VERSION "created by canmatrix"

NS_ :

BS_:

BU_: IPD

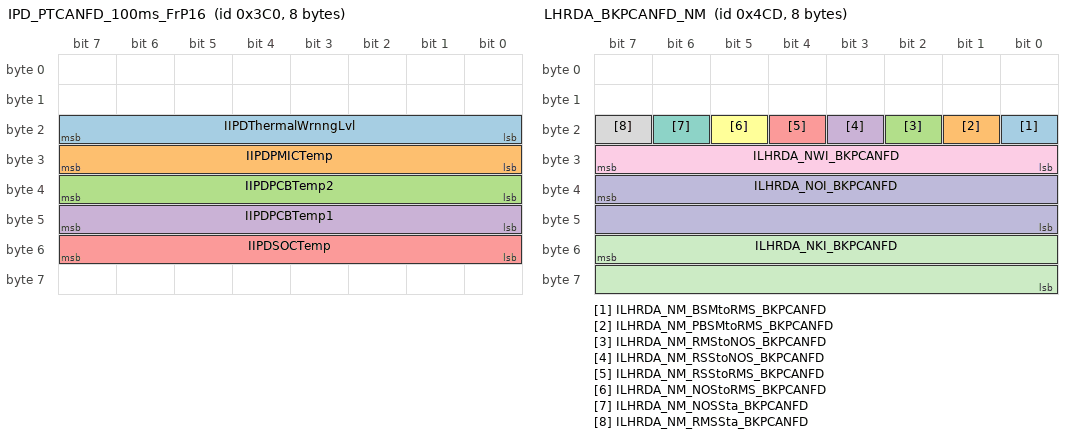
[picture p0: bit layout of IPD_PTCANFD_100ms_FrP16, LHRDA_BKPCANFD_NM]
BO_ 960 IPD_PTCANFD_100ms_FrP16: 8 IPD
 SG_ IIPDThermalWrnngLvl : 23|8@0+ (1,0) [0|255] "null" Vector__XXX
 SG_ IIPDPMICTemp : 31|8@0+ (1,-40) [-40|215] "℃" Vector__XXX
 SG_ IIPDPCBTemp2 : 39|8@0+ (1,-40) [-40|215] "℃" Vector__XXX
 SG_ IIPDPCBTemp1 : 47|8@0+ (1,-40) [-40|215] "℃" Vector__XXX
 SG_ IIPDSOCTemp : 55|8@0+ (1,-40) [-40|215] "℃" Vector__XXX

BO_ 1229 LHRDA_BKPCANFD_NM: 8 Vector__XXX
 SG_ ILHRDA_NM_BSMtoRMS_BKPCANFD : 16|1@0+ (1,0) [0|1] "null" Vector__XXX
 SG_ ILHRDA_NM_PBSMtoRMS_BKPCANFD : 17|1@0+ (1,0) [0|1] "null" Vector__XXX
 SG_ ILHRDA_NM_RMStoNOS_BKPCANFD : 18|1@0+ (1,0) [0|1] "null" Vector__XXX
 SG_ ILHRDA_NM_RSStoNOS_BKPCANFD : 19|1@0+ (1,0) [0|1] "null" Vector__XXX
 SG_ ILHRDA_NM_RSStoRMS_BKPCANFD : 20|1@0+ (1,0) [0|1] "null" Vector__XXX
 SG_ ILHRDA_NM_NOStoRMS_BKPCANFD : 21|1@0+ (1,0) [0|1] "null" Vector__XXX
 SG_ ILHRDA_NM_NOSSta_BKPCANFD : 22|1@0+ (1,0) [0|1] "null" Vector__XXX
 SG_ ILHRDA_NM_RMSSta_BKPCANFD : 23|1@0+ (1,0) [0|1] "null" Vector__XXX
 SG_ ILHRDA_NWI_BKPCANFD : 31|8@0+ (1,0) [0|255] "null" Vector__XXX
 SG_ ILHRDA_NOI_BKPCANFD : 39|16@0+ (1,0) [0|65535] "null" Vector__XXX
 SG_ ILHRDA_NKI_BKPCANFD : 55|16@0+ (1,0) [0|65535] "null" Vector__XXX

BO_ 181 LHZCU_BKBCANFD_10ms_FrP32: 12 Vector__XXX
 SG_ IDircnLghtOnReq_LHZCU : 41|2@0+ (1,0) [0|3] "null" IPD

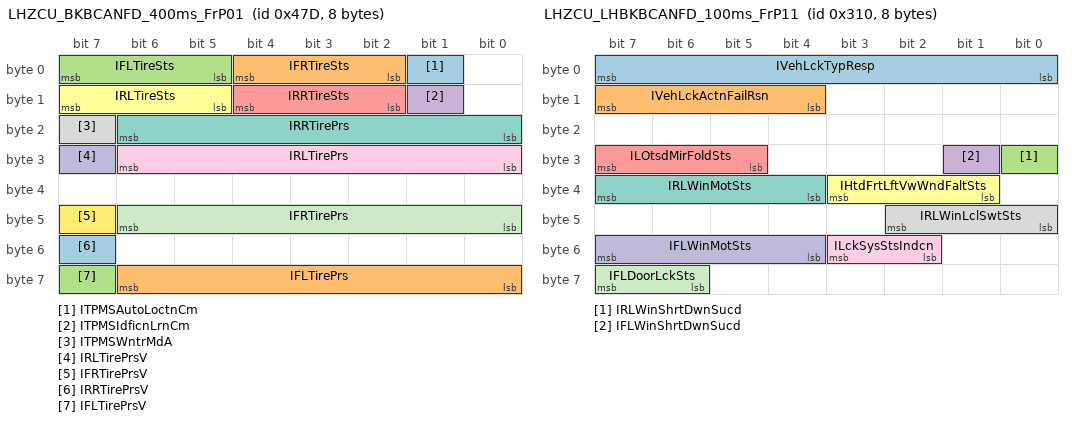
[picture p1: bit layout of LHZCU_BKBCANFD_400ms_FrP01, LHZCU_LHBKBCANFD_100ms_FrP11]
BO_ 1149 LHZCU_BKBCANFD_400ms_FrP01: 8 Vector__XXX
 SG_ ITPMSAutoLoctnCm : 1|1@0+ (1,0) [0|1] "null" Vector__XXX
 SG_ IFRTireSts : 4|3@0+ (1,0) [0|7] "null" IPD
 SG_ IFLTireSts : 7|3@0+ (1,0) [0|7] "null" IPD
 SG_ ITPMSIdficnLrnCm : 9|1@0+ (1,0) [0|1] "null" Vector__XXX
 SG_ IRRTireSts : 12|3@0+ (1,0) [0|7] "null" IPD
 SG_ IRLTireSts : 15|3@0+ (1,0) [0|7] "null" IPD
 SG_ IRRTirePrs : 22|7@0+ (4,0) [0|508] "kPa" IPD
 SG_ ITPMSWntrMdA : 23|1@0+ (1,0) [0|1] "null" IPD
 SG_ IRLTirePrs : 30|7@0+ (4,0) [0|508] "kPa" IPD
 SG_ IRLTirePrsV : 31|1@0+ (1,0) [0|1] "null" IPD
 SG_ IFRTirePrs : 46|7@0+ (4,0) [0|508] "kPa" IPD
 SG_ IFRTirePrsV : 47|1@0+ (1,0) [0|1] "null" IPD
 SG_ IRRTirePrsV : 55|1@0+ (1,0) [0|1] "null" IPD
 SG_ IFLTirePrs : 62|7@0+ (4,0) [0|508] "kPa" IPD
 SG_ IFLTirePrsV : 63|1@0+ (1,0) [0|1] "null" IPD

BO_ 638 LHZCU_BKBCANFD_50ms_FrP24: 20 Vector__XXX
 SG_ IVehIlluminateCtrlCmd : 24|1@0+ (1,0) [0|1] "null" Vector__XXX
 SG_ IBrkLghtSta : 32|1@0+ (1,0) [0|1] "null" Vector__XXX
 SG_ IBrkLghtFltSta : 40|1@0+ (1,0) [0|1] "null" Vector__XXX
 SG_ IDircnLghtSts : 52|3@0+ (1,0) [0|7] "null" Vector__XXX
 SG_ IDircnLghtMdSts : 53|1@0+ (1,0) [0|1] "null" Vector__XXX
 SG_ IRevsLghtFltSta : 54|1@0+ (1,0) [0|1] "null" Vector__XXX
 SG_ IRevsLghtSta : 55|1@0+ (1,0) [0|1] "null" Vector__XXX
 SG_ IRearFogLghtAcFltsts : 56|1@0+ (1,0) [0|1] "null" Vector__XXX
 SG_ IRearFogLghtAcSts : 57|1@0+ (1,0) [0|1] "null" Vector__XXX
 SG_ IRearFogLghtCtrl : 58|1@0+ (1,0) [0|1] "null" Vector__XXX
 SG_ ISideLghtFltsts : 59|1@0+ (1,0) [0|1] "null" Vector__XXX
 SG_ IRRSideLghtCtrl : 61|1@0+ (1,0) [0|1] "null" Vector__XXX
 SG_ IRLSideLghtCtrl : 62|1@0+ (1,0) [0|1] "null" Vector__XXX
 SG_ IHdlmpLvlngFltSts : 64|1@0+ (1,0) [0|1] "null" Vector__XXX
 SG_ IHdlmpLvlngCrtl : 67|3@0+ (1,0) [0|7] "null" Vector__XXX
 SG_ IDayTmRunngLghtFltsts : 68|1@0+ (1,0) [0|1] "null" Vector__XXX
 SG_ IDayTmRunngLghtSts : 69|1@0+ (1,0) [0|1] "null" Vector__XXX
 SG_ IFrtFogLghtSts : 74|1@0+ (1,0) [0|1] "null" Vector__XXX
 SG_ IRFrtFogLghtCtrl : 75|1@0+ (1,0) [0|1] "null" Vector__XXX
 SG_ ILFrtFogLghtCtrl : 76|1@0+ (1,0) [0|1] "null" Vector__XXX
 SG_ IHdlmpLvlngSts : 79|3@0+ (1,0) [0|7] "null" Vector__XXX
 SG_ IDircnLghtSwReq : 84|3@0+ (1,0) [0|7] "null" IPD
 SG_ IFrtFogLghtFltSts : 87|1@0+ (1,0) [0|1] "null" Vector__XXX
 SG_ IDircnLghtFltsts : 105|2@0+ (1,0) [0|3] "null" IPD

BO_ 745 LHZCU_BKBCANFD_50ms_FrP34: 16 Vector__XXX
 SG_ IAutoMainBeamLghtOn : 12|1@0+ (1,0) [0|1] "null" IPD
 SG_ IMainBeamLghtOn : 13|1@0+ (1,0) [0|1] "null" IPD
 SG_ IRLDoorLckSts : 21|2@0+ (1,0) [0|3] "null" Vector__XXX
 SG_ IComfortDircnLghtDsp : 25|2@0+ (1,0) [0|3] "null" Vector__XXX
 SG_ IFrtWiperTemp : 39|8@0+ (0.5,-40) [-40|87.5] "degreeCelsius" Vector__XXX
 SG_ IDircnLghtMdDsp : 44|2@0+ (1,0) [0|3] "null" Vector__XXX
 SG_ IAllWndAndSrfLazyClsReq : 45|1@0+ (1,0) [0|1] "null" Vector__XXX
 SG_ IRrSrvcPosReq : 46|1@0+ (1,0) [0|1] "null" Vector__XXX
 SG_ IRrWiperFnEnb : 47|1@0+ (1,0) [0|1] "null" Vector__XXX

BO_ 1150 LHZCU_LHBKBCANFDF_400ms_FrP18: 8 Vector__XXX
 SG_ ITPMSF : 12|1@0+ (1,0) [0|1] "null" IPD
 SG_ ITPMSTirePrsLowIO : 13|1@0+ (1,0) [0|1] "null" IPD

BO_ 784 LHZCU_LHBKBCANFD_100ms_FrP11: 8 Vector__XXX
 SG_ IVehLckTypResp : 7|8@0+ (1,0) [0|255] "null" Vector__XXX
 SG_ IVehLckActnFailRsn : 15|4@0+ (1,0) [0|15] "null" Vector__XXX
 SG_ IRLWinShrtDwnSucd : 24|1@0+ (1,0) [0|1] "null" Vector__XXX
 SG_ IFLWinShrtDwnSucd : 25|1@0+ (1,0) [0|1] "null" Vector__XXX
 SG_ ILOtsdMirFoldSts : 31|3@0+ (1,0) [0|7] "null" IPD
 SG_ IHtdFrtLftVwWndFaltSts : 35|3@0+ (1,0) [0|7] "null" Vector__XXX
 SG_ IRLWinMotSts : 39|4@0+ (1,0) [0|15] "null" Vector__XXX
 SG_ IRLWinLclSwtSts : 42|3@0+ (1,0) [0|7] "null" Vector__XXX
 SG_ ILckSysStsIndcn : 51|2@0+ (1,0) [0|3] "null" Vector__XXX
 SG_ IFLWinMotSts : 55|4@0+ (1,0) [0|15] "null" Vector__XXX
 SG_ IFLDoorLckSts : 63|2@0+ (1,0) [0|3] "null" Vector__XXX

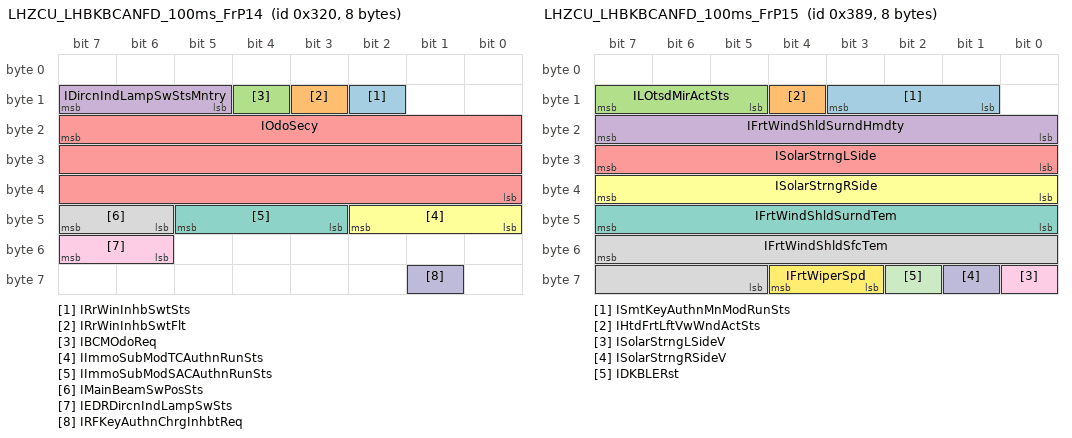
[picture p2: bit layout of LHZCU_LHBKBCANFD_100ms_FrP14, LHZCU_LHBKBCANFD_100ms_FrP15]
BO_ 800 LHZCU_LHBKBCANFD_100ms_FrP14: 8 Vector__XXX
 SG_ IRrWinInhbSwtSts : 10|1@0+ (1,0) [0|1] "null" Vector__XXX
 SG_ IRrWinInhbSwtFlt : 11|1@0+ (1,0) [0|1] "null" Vector__XXX
 SG_ IBCMOdoReq : 12|1@0+ (1,0) [0|1] "null" Vector__XXX
 SG_ IDircnIndLampSwStsMntry : 15|3@0+ (1,0) [0|7] "null" IPD
 SG_ IOdoSecy : 23|24@0+ (1,0) [0|16777215] "km" Vector__XXX
 SG_ IImmoSubModTCAuthnRunSts : 42|3@0+ (1,0) [0|7] "null" Vector__XXX
 SG_ IImmoSubModSACAuthnRunSts : 45|3@0+ (1,0) [0|7] "null" Vector__XXX
 SG_ IMainBeamSwPosSts : 47|2@0+ (1,0) [0|3] "null" IPD
 SG_ IEDRDircnIndLampSwSts : 55|2@0+ (1,0) [0|3] "null" Vector__XXX
 SG_ IRFKeyAuthnChrgInhbtReq : 57|1@0+ (1,0) [0|1] "null" Vector__XXX

BO_ 905 LHZCU_LHBKBCANFD_100ms_FrP15: 8 Vector__XXX
 SG_ ISmtKeyAuthnMnModRunSts : 11|3@0+ (1,0) [0|7] "null" Vector__XXX
 SG_ IHtdFrtLftVwWndActSts : 12|1@0+ (1,0) [0|1] "null" Vector__XXX
 SG_ ILOtsdMirActSts : 15|3@0+ (1,0) [0|7] "null" Vector__XXX
 SG_ IFrtWindShldSurndHmdty : 23|8@0+ (0.5,0) [0|127.5] "Percent" Vector__XXX
 SG_ ISolarStrngLSide : 31|8@0+ (5,0) [0|1275] "null" Vector__XXX
 SG_ ISolarStrngRSide : 39|8@0+ (5,0) [0|1275] "null" Vector__XXX
 SG_ IFrtWindShldSurndTem : 47|8@0+ (0.5,-40) [-40|87.5] "degreeCelsius" Vector__XXX
 SG_ IFrtWindShldSfcTem : 55|11@0+ (0.1,-40) [-40|164.7] "degreeCelsius" Vector__XXX
 SG_ ISolarStrngLSideV : 56|1@0+ (1,0) [0|1] "null" Vector__XXX
 SG_ ISolarStrngRSideV : 57|1@0+ (1,0) [0|1] "null" Vector__XXX
 SG_ IDKBLERst : 58|1@0+ (1,0) [0|1] "null" Vector__XXX
 SG_ IFrtWiperSpd : 60|2@0+ (1,0) [0|3] "null" IPD

BO_ 783 LHZCU_LHBKBCANFD_100ms_FrP16: 64 Vector__XXX
 SG_ ILHZCUeFs12Crnt : 7|9@0+ (0.1,0) [0|51.1] "A" Vector__XXX
 SG_ ILHZCUeSw40Crnt : 14|9@0+ (0.1,0) [0|51.1] "A" Vector__XXX
 SG_ IWlcmReq : 19|2@0+ (1,0) [0|3] "null" Vector__XXX
 SG_ IFllwMeReq : 21|2@0+ (1,0) [0|3] "null" Vector__XXX
 SG_ ILHZCUInptVol : 47|8@0+ (0.1,0) [0|25.5] "V" Vector__XXX
 SG_ ILHZCUeFs8Crnt : 55|9@0+ (0.1,0) [0|51.1] "A" Vector__XXX
 SG_ ILHZCUeSw24Crnt : 56|9@0+ (0.1,0) [0|51.1] "A" Vector__XXX
 SG_ ILHZCUeSw17Crnt : 76|9@0+ (0.1,0) [0|51.1] "A" Vector__XXX
 SG_ IKickSnsrDetnEnb : 77|1@0+ (1,0) [0|1] "null" Vector__XXX
 SG_ ILHZCUeSw16Crnt : 83|9@0+ (0.1,0) [0|51.1] "A" Vector__XXX
 SG_ ILHZCUeSw15Crnt : 90|9@0+ (0.1,0) [0|51.1] "A" Vector__XXX
 SG_ ILHZCUeSw14Crnt : 97|9@0+ (0.1,0) [0|51.1] "A" Vector__XXX
 SG_ ILHZCUeSw13Crnt : 104|9@0+ (0.1,0) [0|51.1] "A" Vector__XXX
 SG_ ILHZCUeSw12Crnt : 127|9@0+ (0.1,0) [0|51.1] "A" Vector__XXX
 SG_ ILHZCUeSw26Crnt : 128|9@0+ (0.1,0) [0|51.1] "A" Vector__XXX
 SG_ ILHZCUeFs6Crnt : 148|9@0+ (0.1,0) [0|51.1] "A" Vector__XXX
 SG_ IKickSnsrDfct : 149|1@0+ (1,0) [0|1] "null" Vector__XXX
 SG_ IKickSnsrEleDfct : 150|1@0+ (1,0) [0|1] "null" Vector__XXX
 SG_ IKickSnsrPlayProtn : 151|1@0+ (1,0) [0|1] "null" Vector__XXX
 SG_ ILHZCUeSw32Crnt : 155|9@0+ (0.1,0) [0|51.1] "A" Vector__XXX
 SG_ ILHZCUeFs4Crnt : 162|9@0+ (0.1,0) [0|51.1] "A" Vector__XXX
 SG_ ILHZCUeSw27Crnt : 168|9@0+ (0.1,0) [0|51.1] "A" Vector__XXX
 SG_ IKickSnsrSts : 169|1@0+ (1,0) [0|1] "null" Vector__XXX
 SG_ ILHZCUBkupInptVol : 191|8@0+ (0.1,0) [0|25.5] "V" Vector__XXX
 SG_ ILHZCUeSw1Crnt : 199|9@0+ (0.1,0) [0|51.1] "A" Vector__XXX
 SG_ ILHZCUeSw20Crnt : 206|9@0+ (0.1,0) [0|51.1] "A" Vector__XXX
 SG_ ILHZCUeSw3Crnt : 213|9@0+ (0.1,0) [0|51.1] "A" Vector__XXX
 SG_ ILHZCUeSw29Crnt : 216|9@0+ (0.1,0) [0|51.1] "A" Vector__XXX
 SG_ ILHZCUeSw36Crnt : 239|9@0+ (0.1,0) [0|51.1] "A" Vector__XXX
 SG_ ILHZCUeFs13Crnt : 240|9@0+ (0.1,0) [0|51.1] "A" Vector__XXX
 SG_ ILHZCUeSw30Crnt : 263|9@0+ (0.1,0) [0|51.1] "A" Vector__XXX
 SG_ ILHZCUeSw31Crnt : 264|9@0+ (0.1,0) [0|51.1] "A" Vector__XXX
 SG_ IFrwlLghtReq_LHZCU : 267|1@0+ (1,0) [0|1] "null" Vector__XXX
 SG_ ILHZCUeSw43Crnt : 287|9@0+ (0.1,0) [0|51.1] "A" Vector__XXX
 SG_ ILHZCUAddtnInptVol : 303|8@0+ (0.1,0) [0|25.5] "V" Vector__XXX
 SG_ ILHZCUeSw44Crnt : 311|9@0+ (0.1,0) [0|51.1] "A" Vector__XXX
 SG_ ILHZCUeSw45Crnt : 318|9@0+ (0.1,0) [0|51.1] "A" Vector__XXX
 SG_ ILHZCUeSw46Crnt : 335|9@0+ (0.1,0) [0|51.1] "A" Vector__XXX
 SG_ ILHZCUeSw47Crnt : 336|9@0+ (0.1,0) [0|51.1] "A" Vector__XXX
 SG_ IWlcmLghtReq_LHZCU : 338|1@0+ (1,0) [0|1] "null" Vector__XXX
 SG_ IFLDoorOpenSts : 341|2@0+ (1,0) [0|3] "null" IPD
 SG_ IHUDLghtSnsrHdwrFltPrst : 342|1@0+ (1,0) [0|1] "null" Vector__XXX
 SG_ IHUDFwdLkngAmbtLghtLvl : 383|14@0+ (10,0) [0|163830] "LUX" Vector__XXX
 SG_ IFollowMeHomeReq_LHZCU : 384|1@0+ (1,0) [0|1] "null" Vector__XXX
 SG_ IBklghtReq : 385|1@0+ (1,0) [0|1] "null" Vector__XXX
 SG_ IHUDRLSAmbtLghtLvl : 399|12@0+ (10,0) [0|40950] "LUX" Vector__XXX
 SG_ ILHZCUeFs15Crnt : 400|9@0+ (0.1,0) [0|51.1] "A" Vector__XXX
 SG_ IHmdtySnsrHdwrFltPrst : 401|1@0+ (1,0) [0|1] "null" Vector__XXX
 SG_ IFrtPsngDoorOpenSts_LHZCU : 403|2@0+ (1,0) [0|3] "null" IPD
 SG_ ILHZCUeFs17Crnt : 423|9@0+ (0.1,0) [0|51.1] "A" Vector__XXX

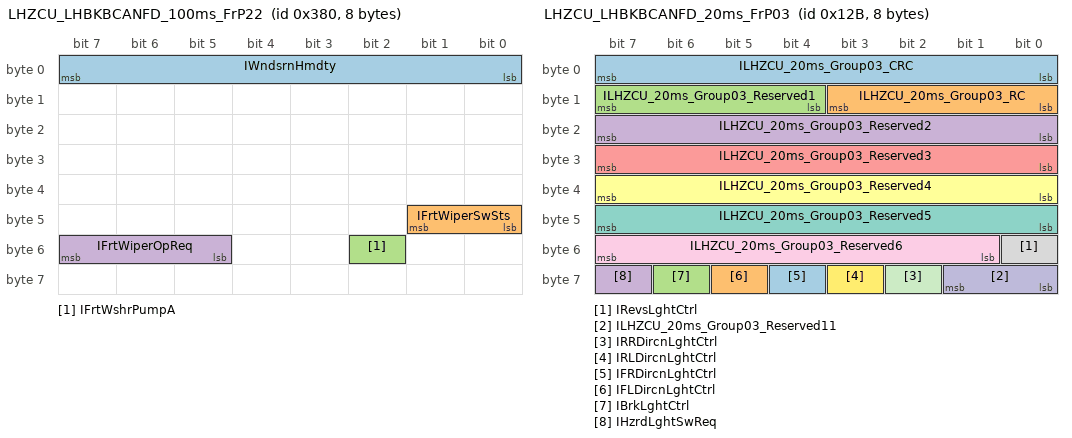
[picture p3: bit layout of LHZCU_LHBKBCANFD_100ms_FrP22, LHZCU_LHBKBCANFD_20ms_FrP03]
BO_ 896 LHZCU_LHBKBCANFD_100ms_FrP22: 8 Vector__XXX
 SG_ IWndsrnHmdty : 7|8@0+ (1,0) [0|255] "null" IPD
 SG_ IFrtWiperSwSts : 41|2@0+ (1,0) [0|3] "null" IPD
 SG_ IFrtWshrPumpA : 50|1@0+ (1,0) [0|1] "null" Vector__XXX
 SG_ IFrtWiperOpReq : 55|3@0+ (1,0) [0|7] "null" Vector__XXX

BO_ 299 LHZCU_LHBKBCANFD_20ms_FrP03: 8 Vector__XXX
 SG_ ILHZCU_20ms_Group03_CRC : 7|8@0+ (1,0) [0|255] "null" IPD
 SG_ ILHZCU_20ms_Group03_RC : 11|4@0+ (1,0) [0|15] "null" IPD
 SG_ ILHZCU_20ms_Group03_Reserved1 : 15|4@0+ (1,0) [0|15] "null" IPD
 SG_ ILHZCU_20ms_Group03_Reserved2 : 23|8@0+ (1,0) [0|255] "null" IPD
 SG_ ILHZCU_20ms_Group03_Reserved3 : 31|8@0+ (1,0) [0|255] "null" IPD
 SG_ ILHZCU_20ms_Group03_Reserved4 : 39|8@0+ (1,0) [0|255] "null" IPD
 SG_ ILHZCU_20ms_Group03_Reserved5 : 47|8@0+ (1,0) [0|255] "null" IPD
 SG_ IRevsLghtCtrl : 48|1@0+ (1,0) [0|1] "null" IPD
 SG_ ILHZCU_20ms_Group03_Reserved6 : 55|7@0+ (1,0) [0|127] "null" IPD
 SG_ ILHZCU_20ms_Group03_Reserved11 : 57|2@0+ (1,0) [0|3] "null" IPD
 SG_ IRRDircnLghtCtrl : 58|1@0+ (1,0) [0|1] "null" IPD
 SG_ IRLDircnLghtCtrl : 59|1@0+ (1,0) [0|1] "null" IPD
 SG_ IFRDircnLghtCtrl : 60|1@0+ (1,0) [0|1] "null" IPD
 SG_ IFLDircnLghtCtrl : 61|1@0+ (1,0) [0|1] "null" IPD
 SG_ IBrkLghtCtrl : 62|1@0+ (1,0) [0|1] "null" IPD
 SG_ IHzrdLghtSwReq : 63|1@0+ (1,0) [0|1] "null" IPD

BO_ 566 LHZCU_LHBKBCANFD_50ms_FrP04: 8 Vector__XXX
 SG_ IFindCarFuncInfoDsp : 2|2@0+ (1,0) [0|3] "null" Vector__XXX
 SG_ IDipdBeamLghtFltsts : 5|1@0+ (1,0) [0|1] "null" IPD
 SG_ IFLDoorHndlPESwtActv : 7|2@0+ (1,0) [0|3] "null" IPD
 SG_ IFRDoorHndlPESwtActv : 13|2@0+ (1,0) [0|3] "null" IPD
 SG_ IMainBeamLghtMdSts : 15|2@0+ (1,0) [0|3] "null" IPD
 SG_ IVehHzrdMdSts : 19|4@0+ (1,0) [0|15] "null" IPD
 SG_ IHzrdLghtSwSts : 20|1@0+ (1,0) [0|1] "null" IPD
 SG_ IBrkLghtSwStsV : 21|1@0+ (1,0) [0|1] "null" Vector__XXX
 SG_ IBrkLghtSwSts : 22|1@0+ (1,0) [0|1] "null" Vector__XXX
 SG_ IRrWiperReq : 23|1@0+ (1,0) [0|1] "null" Vector__XXX
 SG_ IMainBeamLghtFltSts : 26|1@0+ (1,0) [0|1] "null" IPD
 SG_ IMainBeamLghtSts : 27|1@0+ (1,0) [0|1] "null" Vector__XXX
 SG_ IMainBeamLghtSwSts : 29|2@0+ (1,0) [0|3] "null" Vector__XXX
 SG_ IDircnIndLghtSwSts : 31|2@0+ (1,0) [0|3] "null" IPD
 SG_ ILdspcRlseSwtActv : 32|1@0+ (1,0) [0|1] "null" Vector__XXX
 SG_ IRRWinDrvrSwtSts : 35|3@0+ (1,0) [0|7] "null" Vector__XXX
 SG_ ILckCtrlResp : 39|4@0+ (1,0) [0|15] "null" IPD
 SG_ IRLWinDrvrSwtSts : 44|3@0+ (1,0) [0|7] "null" Vector__XXX
 SG_ IFRWinDrvrSwtSts : 47|3@0+ (1,0) [0|7] "null" Vector__XXX
 SG_ IDipdBeamLghtSts : 48|1@0+ (1,0) [0|1] "null" IPD
 SG_ IBrkPdlTrigd : 49|1@0+ (1,0) [0|1] "null" Vector__XXX
 SG_ IFLWinLclSwtSts : 52|3@0+ (1,0) [0|7] "null" Vector__XXX
 SG_ IExtrLckActnIndcn : 55|3@0+ (1,0) [0|7] "null" Vector__XXX
 SG_ IAutoMainBeamLghtSts : 57|2@0+ (1,0) [0|3] "null" Vector__XXX
 SG_ IDrvrDetSnsrFltSts : 60|3@0+ (1,0) [0|7] "null" Vector__XXX
 SG_ IDircnIndLghtMdSts : 63|3@0+ (1,0) [0|7] "null" IPD

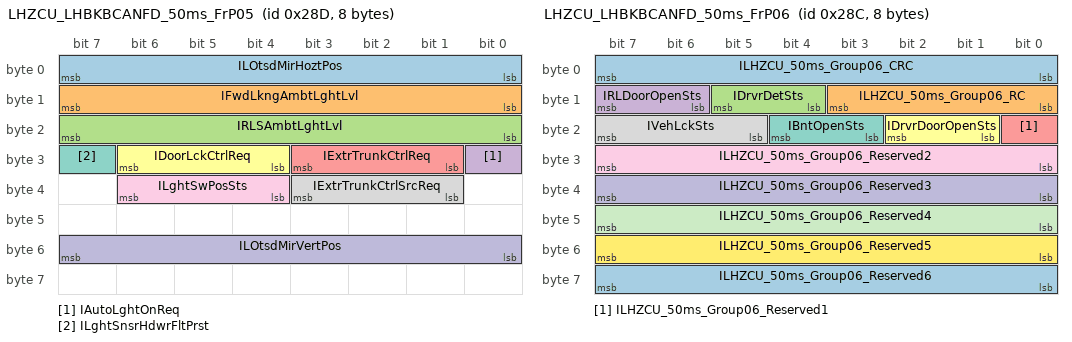
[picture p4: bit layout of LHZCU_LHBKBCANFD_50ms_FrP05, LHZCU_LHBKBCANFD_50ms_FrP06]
BO_ 653 LHZCU_LHBKBCANFD_50ms_FrP05: 8 Vector__XXX
 SG_ ILOtsdMirHoztPos : 7|8@0+ (1,0) [0|255] "null" Vector__XXX
 SG_ IFwdLkngAmbtLghtLvl : 15|8@0+ (20,0) [0|5100] "lux" IPD
 SG_ IRLSAmbtLghtLvl : 23|8@0+ (20,0) [0|5100] "lux" IPD
 SG_ IAutoLghtOnReq : 24|1@0+ (1,0) [0|1] "null" IPD
 SG_ IExtrTrunkCtrlReq : 27|3@0+ (1,0) [0|7] "null" Vector__XXX
 SG_ IDoorLckCtrlReq : 30|3@0+ (1,0) [0|7] "null" Vector__XXX
 SG_ ILghtSnsrHdwrFltPrst : 31|1@0+ (1,0) [0|1] "null" IPD
 SG_ IExtrTrunkCtrlSrcReq : 35|3@0+ (1,0) [0|7] "null" Vector__XXX
 SG_ ILghtSwPosSts : 38|3@0+ (1,0) [0|7] "null" IPD
 SG_ ILOtsdMirVertPos : 55|8@0+ (1,0) [0|255] "null" Vector__XXX

BO_ 652 LHZCU_LHBKBCANFD_50ms_FrP06: 8 Vector__XXX
 SG_ ILHZCU_50ms_Group06_CRC : 7|8@0+ (1,0) [0|255] "null" IPD
 SG_ ILHZCU_50ms_Group06_RC : 11|4@0+ (1,0) [0|15] "null" IPD
 SG_ IDrvrDetSts : 13|2@0+ (1,0) [0|3] "null" IPD
 SG_ IRLDoorOpenSts : 15|2@0+ (1,0) [0|3] "null" IPD
 SG_ ILHZCU_50ms_Group06_Reserved1 : 16|1@0+ (1,0) [0|1] "null" IPD
 SG_ IDrvrDoorOpenSts : 18|2@0+ (1,0) [0|3] "null" IPD
 SG_ IBntOpenSts : 20|2@0+ (1,0) [0|3] "null" IPD
 SG_ IVehLckSts : 23|3@0+ (1,0) [0|7] "null" IPD
 SG_ ILHZCU_50ms_Group06_Reserved2 : 31|8@0+ (1,0) [0|255] "null" IPD
 SG_ ILHZCU_50ms_Group06_Reserved3 : 39|8@0+ (1,0) [0|255] "null" IPD
 SG_ ILHZCU_50ms_Group06_Reserved4 : 47|8@0+ (1,0) [0|255] "null" IPD
 SG_ ILHZCU_50ms_Group06_Reserved5 : 55|8@0+ (1,0) [0|255] "null" IPD
 SG_ ILHZCU_50ms_Group06_Reserved6 : 63|8@0+ (1,0) [0|255] "null" IPD

BO_ 714 PICM_PTCANFD_100ms_FrP06: 20 Vector__XXX
 SG_ IAGSModestatus2 : 13|2@0+ (1,0) [0|3] "null" Vector__XXX
 SG_ IAGSModestatus1 : 15|2@0+ (1,0) [0|3] "null" Vector__XXX
 SG_ IAGS1FltRsn : 23|12@0+ (1,0) [0|4095] "null" Vector__XXX
 SG_ IAGS2FltRsn : 27|12@0+ (1,0) [0|4095] "null" Vector__XXX
 SG_ IAGSActualPosition1 : 47|8@0+ (0.392157,0) [0.000000|100.000035] "null" Vector__XXX
 SG_ IAGSActualPosition2 : 55|8@0+ (0.392157,0) [0.000000|100.000035] "null" Vector__XXX
 SG_ IEPTElecWtrPumpActuSpd : 63|8@0+ (0.4,0) [0|102] "null" IPD
 SG_ IESSElecWtrPumpActuSpd : 71|8@0+ (0.4,0) [0|102] "null" Vector__XXX
 SG_ IEDUClntTem : 79|8@0+ (1,-40) [-40|215] "null" IPD
 SG_ IAGSTorqueResponse2 : 81|2@0+ (1,0) [0|3] "null" Vector__XXX
 SG_ IAGSTorqueResponse1 : 83|2@0+ (1,0) [0|3] "null" Vector__XXX
 SG_ IAGSSelflearnStatus2 : 85|2@0+ (1,0) [0|3] "null" Vector__XXX
 SG_ IAGSSelflearnStatus1 : 87|2@0+ (1,0) [0|3] "null" Vector__XXX
 SG_ IEDUClntTemV : 93|1@0+ (1,0) [0|1] "null" IPD
 SG_ IAGSMoveStatus2 : 94|1@0+ (1,0) [0|1] "null" Vector__XXX
 SG_ IAGSMoveStatus1 : 95|1@0+ (1,0) [0|1] "null" Vector__XXX

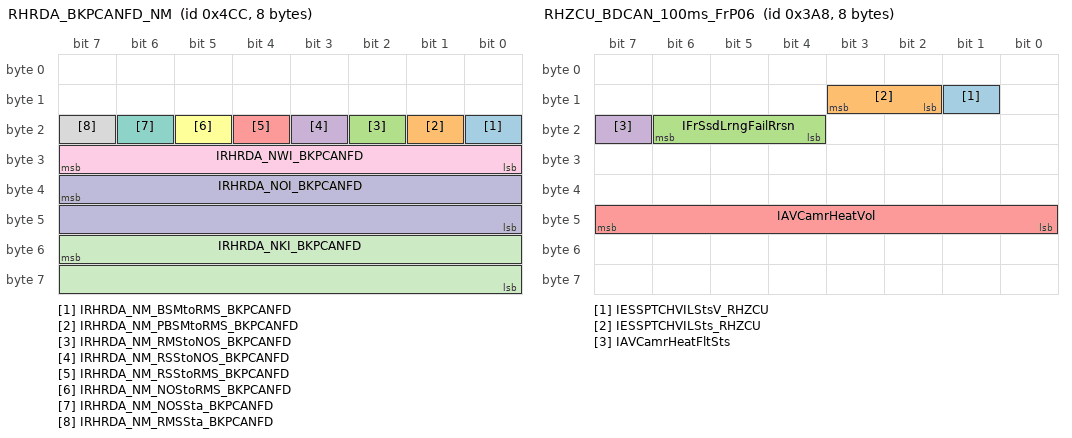
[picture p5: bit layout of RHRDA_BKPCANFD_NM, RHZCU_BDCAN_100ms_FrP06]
BO_ 1228 RHRDA_BKPCANFD_NM: 8 Vector__XXX
 SG_ IRHRDA_NM_BSMtoRMS_BKPCANFD : 16|1@0+ (1,0) [0|1] "null" Vector__XXX
 SG_ IRHRDA_NM_PBSMtoRMS_BKPCANFD : 17|1@0+ (1,0) [0|1] "null" Vector__XXX
 SG_ IRHRDA_NM_RMStoNOS_BKPCANFD : 18|1@0+ (1,0) [0|1] "null" Vector__XXX
 SG_ IRHRDA_NM_RSStoNOS_BKPCANFD : 19|1@0+ (1,0) [0|1] "null" Vector__XXX
 SG_ IRHRDA_NM_RSStoRMS_BKPCANFD : 20|1@0+ (1,0) [0|1] "null" Vector__XXX
 SG_ IRHRDA_NM_NOStoRMS_BKPCANFD : 21|1@0+ (1,0) [0|1] "null" Vector__XXX
 SG_ IRHRDA_NM_NOSSta_BKPCANFD : 22|1@0+ (1,0) [0|1] "null" Vector__XXX
 SG_ IRHRDA_NM_RMSSta_BKPCANFD : 23|1@0+ (1,0) [0|1] "null" Vector__XXX
 SG_ IRHRDA_NWI_BKPCANFD : 31|8@0+ (1,0) [0|255] "null" Vector__XXX
 SG_ IRHRDA_NOI_BKPCANFD : 39|16@0+ (1,0) [0|65535] "null" Vector__XXX
 SG_ IRHRDA_NKI_BKPCANFD : 55|16@0+ (1,0) [0|65535] "null" Vector__XXX

BO_ 936 RHZCU_BDCAN_100ms_FrP06: 8 Vector__XXX
 SG_ IESSPTCHVILStsV_RHZCU : 9|1@0+ (1,0) [0|1] "null" Vector__XXX
 SG_ IESSPTCHVILSts_RHZCU : 11|2@0+ (1,0) [0|3] "null" Vector__XXX
 SG_ IFrSsdLrngFailRrsn : 22|3@0+ (1,0) [0|7] "null" Vector__XXX
 SG_ IAVCamrHeatFltSts : 23|1@0+ (1,0) [0|1] "null" IPD
 SG_ IAVCamrHeatVol : 47|8@0+ (0.1,3) [3|28.5] "V" IPD

BO_ 701 RHZCU_RHBKBCANFD_100ms_FrP11: 12 Vector__XXX
 SG_ IITMSEDUClntInltTem : 7|8@0+ (1,-40) [-40|215] "degreeCelsius" IPD
 SG_ IITMSAGS1Pos : 15|8@0+ (1,0) [0|255] "Percent" Vector__XXX
 SG_ IITMSAGS2Pos : 23|8@0+ (1,0) [0|255] "Percent" Vector__XXX
 SG_ IITMSEDUClntInltTemV : 48|1@0+ (1,0) [0|1] "null" IPD
 SG_ IEACPwrLmtSts : 49|1@0+ (1,0) [0|1] "null" Vector__XXX
 SG_ IITMSEnbWPTC : 51|2@0+ (1,0) [0|3] "null" Vector__XXX
 SG_ IITMSEPTCoolngFanSts : 53|2@0+ (1,0) [0|3] "null" Vector__XXX
 SG_ IITMSMotHeatEnb : 55|1@0+ (1,0) [0|1] "null" Vector__XXX
 SG_ IITMSBMSClntPumpSts : 59|2@0+ (1,0) [0|3] "null" Vector__XXX
 SG_ IPTCPwrLmtSts : 60|1@0+ (1,0) [0|1] "null" Vector__XXX
 SG_ IITMSEPTEDUClntPumpSts : 63|3@0+ (1,0) [0|7] "null" IPD
 SG_ IITMSTMHeatPowReq : 71|8@0+ (0.1,0) [0|25.5] "null" Vector__XXX

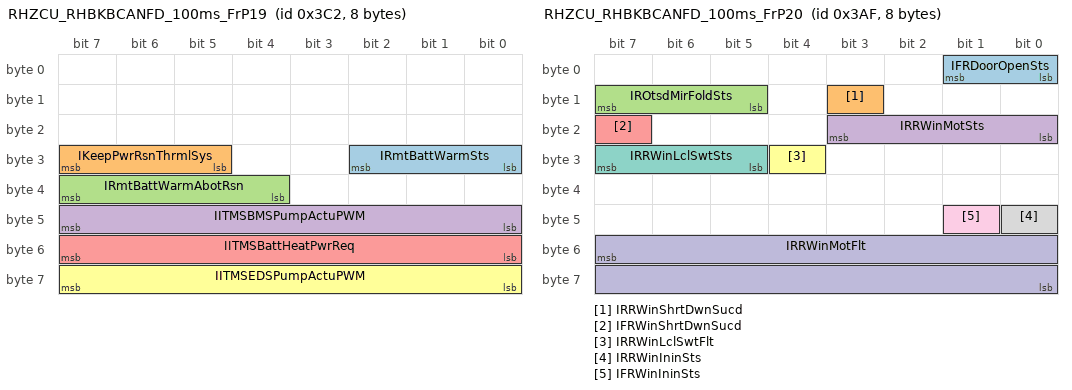
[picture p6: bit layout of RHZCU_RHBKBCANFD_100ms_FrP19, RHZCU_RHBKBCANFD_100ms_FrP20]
BO_ 962 RHZCU_RHBKBCANFD_100ms_FrP19: 8 Vector__XXX
 SG_ IRmtBattWarmSts : 26|3@0+ (1,0) [0|7] "null" Vector__XXX
 SG_ IKeepPwrRsnThrmlSys : 31|3@0+ (1,0) [0|7] "null" Vector__XXX
 SG_ IRmtBattWarmAbotRsn : 39|4@0+ (1,0) [0|15] "null" Vector__XXX
 SG_ IITMSBMSPumpActuPWM : 47|8@0+ (0.4,0) [0|102] "Percent" Vector__XXX
 SG_ IITMSBattHeatPwrReq : 55|8@0+ (0.1,0) [0|25.5] "kW" Vector__XXX
 SG_ IITMSEDSPumpActuPWM : 63|8@0+ (0.4,0) [0|102] "Percent
%" IPD

BO_ 943 RHZCU_RHBKBCANFD_100ms_FrP20: 8 Vector__XXX
 SG_ IFRDoorOpenSts : 1|2@0+ (1,0) [0|3] "null" IPD
 SG_ IRRWinShrtDwnSucd : 11|1@0+ (1,0) [0|1] "null" Vector__XXX
 SG_ IROtsdMirFoldSts : 15|3@0+ (1,0) [0|7] "null" IPD
 SG_ IRRWinMotSts : 19|4@0+ (1,0) [0|15] "null" Vector__XXX
 SG_ IFRWinShrtDwnSucd : 23|1@0+ (1,0) [0|1] "null" Vector__XXX
 SG_ IRRWinLclSwtFlt : 28|1@0+ (1,0) [0|1] "null" Vector__XXX
 SG_ IRRWinLclSwtSts : 31|3@0+ (1,0) [0|7] "null" Vector__XXX
 SG_ IRRWinIninSts : 40|1@0+ (1,0) [0|1] "null" Vector__XXX
 SG_ IFRWinIninSts : 41|1@0+ (1,0) [0|1] "null" Vector__XXX
 SG_ IRRWinMotFlt : 55|16@0+ (1,0) [0|65535] "null" Vector__XXX

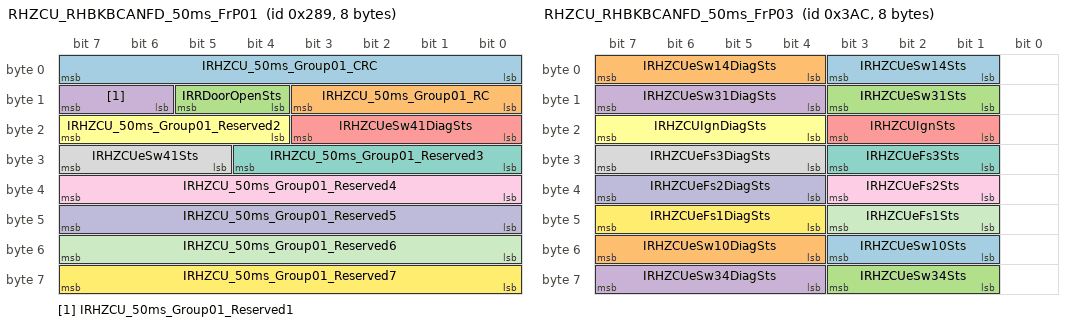
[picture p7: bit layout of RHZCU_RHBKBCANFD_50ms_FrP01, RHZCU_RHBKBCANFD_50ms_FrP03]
BO_ 649 RHZCU_RHBKBCANFD_50ms_FrP01: 8 Vector__XXX
 SG_ IRHZCU_50ms_Group01_CRC : 7|8@0+ (1,0) [0|255] "null" IPD
 SG_ IRHZCU_50ms_Group01_RC : 11|4@0+ (1,0) [0|15] "null" IPD
 SG_ IRRDoorOpenSts : 13|2@0+ (1,0) [0|3] "null" IPD
 SG_ IRHZCU_50ms_Group01_Reserved1 : 15|2@0+ (1,0) [0|3] "null" IPD
 SG_ IRHZCUeSw41DiagSts : 19|4@0+ (1,0) [0|15] "null" IPD
 SG_ IRHZCU_50ms_Group01_Reserved2 : 23|4@0+ (1,0) [0|15] "null" IPD
 SG_ IRHZCU_50ms_Group01_Reserved3 : 28|5@0+ (1,0) [0|31] "null" IPD
 SG_ IRHZCUeSw41Sts : 31|3@0+ (1,0) [0|7] "null" IPD
 SG_ IRHZCU_50ms_Group01_Reserved4 : 39|8@0+ (1,0) [0|255] "null" IPD
 SG_ IRHZCU_50ms_Group01_Reserved5 : 47|8@0+ (1,0) [0|255] "null" IPD
 SG_ IRHZCU_50ms_Group01_Reserved6 : 55|8@0+ (1,0) [0|255] "null" IPD
 SG_ IRHZCU_50ms_Group01_Reserved7 : 63|8@0+ (1,0) [0|255] "null" IPD

BO_ 940 RHZCU_RHBKBCANFD_50ms_FrP03: 8 Vector__XXX
 SG_ IRHZCUeSw14Sts : 3|3@0+ (1,0) [0|7] "null" Vector__XXX
 SG_ IRHZCUeSw14DiagSts : 7|4@0+ (1,0) [0|15] "null" Vector__XXX
 SG_ IRHZCUeSw31Sts : 11|3@0+ (1,0) [0|7] "null" Vector__XXX
 SG_ IRHZCUeSw31DiagSts : 15|4@0+ (1,0) [0|15] "null" Vector__XXX
 SG_ IRHZCUIgnSts : 19|3@0+ (1,0) [0|7] "null" IPD
 SG_ IRHZCUIgnDiagSts : 23|4@0+ (1,0) [0|15] "null" Vector__XXX
 SG_ IRHZCUeFs3Sts : 27|3@0+ (1,0) [0|7] "null" Vector__XXX
 SG_ IRHZCUeFs3DiagSts : 31|4@0+ (1,0) [0|15] "null" Vector__XXX
 SG_ IRHZCUeFs2Sts : 35|3@0+ (1,0) [0|7] "null" Vector__XXX
 SG_ IRHZCUeFs2DiagSts : 39|4@0+ (1,0) [0|15] "null" Vector__XXX
 SG_ IRHZCUeFs1Sts : 43|3@0+ (1,0) [0|7] "null" Vector__XXX
 SG_ IRHZCUeFs1DiagSts : 47|4@0+ (1,0) [0|15] "null" Vector__XXX
 SG_ IRHZCUeSw10Sts : 51|3@0+ (1,0) [0|7] "null" Vector__XXX
 SG_ IRHZCUeSw10DiagSts : 55|4@0+ (1,0) [0|15] "null" Vector__XXX
 SG_ IRHZCUeSw34Sts : 59|3@0+ (1,0) [0|7] "null" Vector__XXX
 SG_ IRHZCUeSw34DiagSts : 63|4@0+ (1,0) [0|15] "null" Vector__XXX

BO_ 564 RZCU_LHBKBCANFD_50ms_FrP37: 8 Vector__XXX
 SG_ IRLDircnLghtSts : 26|1@0+ (1,0) [0|1] "null" Vector__XXX
 SG_ IRRDircnLghtSts : 35|1@0+ (1,0) [0|1] "null" Vector__XXX
 SG_ IRRDircnLghtFltsts : 37|1@0+ (1,0) [0|1] "null" Vector__XXX
 SG_ IRLDircnLghtFltsts : 39|1@0+ (1,0) [0|1] "null" Vector__XXX
 SG_ IRRDircnLghtFltsts_HW : 40|1@0+ (1,0) [0|1] "null" Vector__XXX
 SG_ IRLDircnLghtFltsts_HW : 41|1@0+ (1,0) [0|1] "null" Vector__XXX
 SG_ IRearFogLghtFltsts : 42|1@0+ (1,0) [0|1] "null" Vector__XXX
 SG_ IRearFogLghtSts : 43|1@0+ (1,0) [0|1] "null" Vector__XXX
 SG_ IRevsLghtFltSts : 44|1@0+ (1,0) [0|1] "null" Vector__XXX
 SG_ IBrkLghtFltSts_HW : 45|1@0+ (1,0) [0|1] "null" Vector__XXX
 SG_ IBrkLghtSts_HW : 50|1@0+ (1,0) [0|1] "null" Vector__XXX
 SG_ IRLDircnLghtSts_HW : 51|1@0+ (1,0) [0|1] "null" Vector__XXX
 SG_ IRRDircnLghtSts_HW : 52|1@0+ (1,0) [0|1] "null" Vector__XXX
 SG_ ILdspcOpenSts : 53|1@0+ (1,0) [0|1] "null" IPD
 SG_ IRevsLghtSts : 54|1@0+ (1,0) [0|1] "null" IPD
 SG_ ILdspcOpenStsV : 55|1@0+ (1,0) [0|1] "null" IPD
 SG_ IRLChrgrFlapOpenPos : 63|8@0+ (1,0) [0|255] "null" Vector__XXX

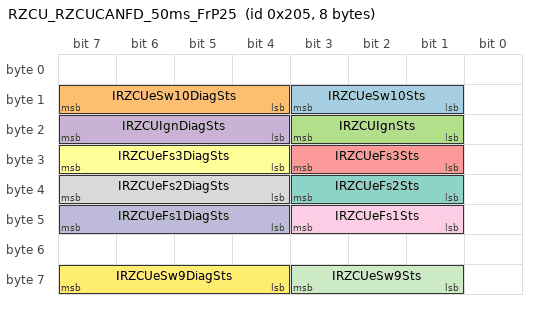
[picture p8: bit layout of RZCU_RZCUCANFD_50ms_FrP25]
BO_ 517 RZCU_RZCUCANFD_50ms_FrP25: 8 Vector__XXX
 SG_ IRZCUeSw10Sts : 11|3@0+ (1,0) [0|7] "null" Vector__XXX
 SG_ IRZCUeSw10DiagSts : 15|4@0+ (1,0) [0|15] "null" Vector__XXX
 SG_ IRZCUIgnSts : 19|3@0+ (1,0) [0|7] "null" IPD
 SG_ IRZCUIgnDiagSts : 23|4@0+ (1,0) [0|15] "null" IPD
 SG_ IRZCUeFs3Sts : 27|3@0+ (1,0) [0|7] "null" Vector__XXX
 SG_ IRZCUeFs3DiagSts : 31|4@0+ (1,0) [0|15] "null" Vector__XXX
 SG_ IRZCUeFs2Sts : 35|3@0+ (1,0) [0|7] "null" Vector__XXX
 SG_ IRZCUeFs2DiagSts : 39|4@0+ (1,0) [0|15] "null" Vector__XXX
 SG_ IRZCUeFs1Sts : 43|3@0+ (1,0) [0|7] "null" Vector__XXX
 SG_ IRZCUeFs1DiagSts : 47|4@0+ (1,0) [0|15] "null" Vector__XXX
 SG_ IRZCUeSw9Sts : 59|3@0+ (1,0) [0|7] "null" Vector__XXX
 SG_ IRZCUeSw9DiagSts : 63|4@0+ (1,0) [0|15] "null" Vector__XXX

BA_DEF_ BO_ "FrameTriggeringName" STRING;
BA_DEF_ BO_ "GenMsgCycleTime" INT 0 65535;
BA_DEF_ BO_ "GenMsgDelayTime" INT 0 65535;
BA_DEF_ BO_ "GenMsgSendType" ENUM  "cyclicX","spontanX","cyclicIfActiveX","spontanWithDelay","cyclicAndSpontanX","cyclicAndSpontanWithDelay","spontanWithRepitition","cyclicIfActiveAndSpontanWD","cyclicIfActiveFast","cyclicWithRepeatOnDemand","none";
BA_DEF_ BO_ "GenMsgStartValue" STRING;
BA_DEF_ BO_ "PduName" STRING;
BA_DEF_ BO_ "VFrameFormat" ENUM  "StandardCAN","ExtendedCAN","reserved","reserved","reserved","reserved","reserved","reserved","reserved","reserved","reserved","reserved","reserved","reserved","StandardCAN_FD","ExtendedCAN_FD";
BA_DEF_ SG_ "CompuMethodName" STRING;
BA_DEF_ SG_ "GenSigStartValue" FLOAT 0 100000000000;
BA_DEF_ SG_ "ISignalName" STRING;
BA_DEF_ SG_ "LongName" STRING;
BA_DEF_ SG_ "SysSignalName" STRING;
BA_DEF_ SG_ "SystemSignalLongSymbol" STRING;
BA_ "FrameTriggeringName" BO_ 960 "IPD_PTCANFD_100ms_FrP16";
BA_ "GenMsgCycleTime" BO_ 960 100;
BA_ "GenMsgSendType" BO_ 960 0;
BA_ "GenMsgStartValue" BO_ 960 "000000ffffffff00";
BA_ "PduName" BO_ 960 "IPD_100ms_PDU16";
BA_ "VFrameFormat" BO_ 960 14;
BA_ "FrameTriggeringName" BO_ 1229 "LHRDA_BKPCANFD_NM";
BA_ "GenMsgSendType" BO_ 1229 1;
BA_ "GenMsgStartValue" BO_ 1229 "0000000000000000";
BA_ "PduName" BO_ 1229 "NmPDU_BKPCANFD_LHRDA";
BA_ "VFrameFormat" BO_ 1229 14;
BA_ "FrameTriggeringName" BO_ 181 "LHZCU_BKBCANFD_10ms_FrP32";
BA_ "GenMsgCycleTime" BO_ 181 10;
BA_ "GenMsgSendType" BO_ 181 0;
BA_ "GenMsgStartValue" BO_ 181 "000000000000000000000000";
BA_ "PduName" BO_ 181 "LHZCU_10ms_PDU32";
BA_ "VFrameFormat" BO_ 181 14;
BA_ "FrameTriggeringName" BO_ 1149 "LHZCU_BKBCANFD_400ms_FrP01";
BA_ "GenMsgCycleTime" BO_ 1149 400;
BA_ "GenMsgSendType" BO_ 1149 0;
BA_ "GenMsgStartValue" BO_ 1149 "0202373700370037";
BA_ "PduName" BO_ 1149 "LHZCU_400ms_PDU01";
BA_ "VFrameFormat" BO_ 1149 14;
BA_ "FrameTriggeringName" BO_ 638 "LHZCU_BKBCANFD_50ms_FrP24";
BA_ "GenMsgCycleTime" BO_ 638 50;
BA_ "GenMsgSendType" BO_ 638 0;
BA_ "GenMsgStartValue" BO_ 638 "0000000000000000000000000000000000000000";
BA_ "PduName" BO_ 638 "LHZCU_50ms_PDU24";
BA_ "VFrameFormat" BO_ 638 14;
BA_ "FrameTriggeringName" BO_ 745 "LHZCU_BKBCANFD_50ms_FrP34";
BA_ "GenMsgCycleTime" BO_ 745 50;
BA_ "GenMsgSendType" BO_ 745 0;
BA_ "GenMsgStartValue" BO_ 745 "00000000000000000000000000000000";
BA_ "PduName" BO_ 745 "LHZCU_50ms_PDU34";
BA_ "VFrameFormat" BO_ 745 14;
BA_ "FrameTriggeringName" BO_ 1150 "LHZCU_LHBKBCANFDF_400ms_FrP18";
BA_ "GenMsgCycleTime" BO_ 1150 400;
BA_ "GenMsgSendType" BO_ 1150 0;
BA_ "GenMsgStartValue" BO_ 1150 "0000000000000000";
BA_ "PduName" BO_ 1150 "LHZCU_400ms_PDU18";
BA_ "VFrameFormat" BO_ 1150 14;
BA_ "FrameTriggeringName" BO_ 784 "LHZCU_LHBKBCANFD_100ms_FrP11";
BA_ "GenMsgCycleTime" BO_ 784 100;
BA_ "GenMsgSendType" BO_ 784 0;
BA_ "GenMsgStartValue" BO_ 784 "0000000000000000";
BA_ "PduName" BO_ 784 "LHZCU_100ms_PDU11";
BA_ "VFrameFormat" BO_ 784 14;
BA_ "FrameTriggeringName" BO_ 800 "LHZCU_LHBKBCANFD_100ms_FrP14";
BA_ "GenMsgCycleTime" BO_ 800 100;
BA_ "GenMsgSendType" BO_ 800 0;
BA_ "GenMsgStartValue" BO_ 800 "0000000000000000";
BA_ "PduName" BO_ 800 "LHZCU_100ms_PDU14";
BA_ "VFrameFormat" BO_ 800 14;
BA_ "FrameTriggeringName" BO_ 905 "LHZCU_LHBKBCANFD_100ms_FrP15";
BA_ "GenMsgCycleTime" BO_ 905 100;
BA_ "GenMsgSendType" BO_ 905 0;
BA_ "GenMsgStartValue" BO_ 905 "0000000000000000";
BA_ "PduName" BO_ 905 "LHZCU_100ms_PDU15";
BA_ "VFrameFormat" BO_ 905 14;
BA_ "FrameTriggeringName" BO_ 783 "LHZCU_LHBKBCANFD_100ms_FrP16";
BA_ "GenMsgCycleTime" BO_ 783 100;
BA_ "GenMsgSendType" BO_ 783 0;
BA_ "GenMsgStartValue" BO_ 783 "00000000000000000000000000000000000000000000000000000000000000000000000000000000000000000000000000000000000000000000000000000000";
BA_ "PduName" BO_ 783 "LHZCU_100ms_PDU16";
BA_ "VFrameFormat" BO_ 783 14;
BA_ "FrameTriggeringName" BO_ 896 "LHZCU_LHBKBCANFD_100ms_FrP22";
BA_ "GenMsgCycleTime" BO_ 896 100;
BA_ "GenMsgSendType" BO_ 896 0;
BA_ "GenMsgStartValue" BO_ 896 "0000000000000000";
BA_ "PduName" BO_ 896 "LHZCU_100ms_PDU22";
BA_ "VFrameFormat" BO_ 896 14;
BA_ "FrameTriggeringName" BO_ 299 "LHZCU_LHBKBCANFD_20ms_FrP03";
BA_ "GenMsgCycleTime" BO_ 299 20;
BA_ "GenMsgSendType" BO_ 299 0;
BA_ "GenMsgStartValue" BO_ 299 "00f0fffffffffe03";
BA_ "PduName" BO_ 299 "LHZCU_20ms_PDU03";
BA_ "VFrameFormat" BO_ 299 14;
BA_ "FrameTriggeringName" BO_ 566 "LHZCU_LHBKBCANFD_50ms_FrP04";
BA_ "GenMsgCycleTime" BO_ 566 50;
BA_ "GenMsgSendType" BO_ 566 0;
BA_ "GenMsgStartValue" BO_ 566 "0010000000000000";
BA_ "PduName" BO_ 566 "LHZCU_50ms_PDU04";
BA_ "VFrameFormat" BO_ 566 14;
BA_ "FrameTriggeringName" BO_ 653 "LHZCU_LHBKBCANFD_50ms_FrP05";
BA_ "GenMsgCycleTime" BO_ 653 50;
BA_ "GenMsgSendType" BO_ 653 0;
BA_ "GenMsgStartValue" BO_ 653 "ff0000000000ff00";
BA_ "PduName" BO_ 653 "LHZCU_50ms_PDU05";
BA_ "VFrameFormat" BO_ 653 14;
BA_ "FrameTriggeringName" BO_ 652 "LHZCU_LHBKBCANFD_50ms_FrP06";
BA_ "GenMsgCycleTime" BO_ 652 50;
BA_ "GenMsgSendType" BO_ 652 0;
BA_ "GenMsgStartValue" BO_ 652 "0000e1ffffffffff";
BA_ "PduName" BO_ 652 "LHZCU_50ms_PDU06";
BA_ "VFrameFormat" BO_ 652 14;
BA_ "FrameTriggeringName" BO_ 714 "PICM_PTCANFD_100ms_FrP06";
BA_ "GenMsgCycleTime" BO_ 714 100;
BA_ "GenMsgSendType" BO_ 714 0;
BA_ "GenMsgStartValue" BO_ 714 "00f00000000000ffff00ff000000000000000000";
BA_ "PduName" BO_ 714 "PICM_100ms_PDU06";
BA_ "VFrameFormat" BO_ 714 14;
BA_ "FrameTriggeringName" BO_ 1228 "RHRDA_BKPCANFD_NM";
BA_ "GenMsgSendType" BO_ 1228 1;
BA_ "GenMsgStartValue" BO_ 1228 "0000000000000000";
BA_ "PduName" BO_ 1228 "NmPDU_BKPCANFD_RHRDA";
BA_ "VFrameFormat" BO_ 1228 14;
BA_ "FrameTriggeringName" BO_ 936 "RHZCU_BDCAN_100ms_FrP06";
BA_ "GenMsgCycleTime" BO_ 936 100;
BA_ "GenMsgSendType" BO_ 936 0;
BA_ "GenMsgStartValue" BO_ 936 "0002000000000000";
BA_ "PduName" BO_ 936 "RHZCU_100ms_PDU06";
BA_ "VFrameFormat" BO_ 936 14;
BA_ "FrameTriggeringName" BO_ 701 "RHZCU_RHBKBCANFD_100ms_FrP11";
BA_ "GenMsgCycleTime" BO_ 701 100;
BA_ "GenMsgSendType" BO_ 701 0;
BA_ "GenMsgStartValue" BO_ 701 "000000000000000000000000";
BA_ "PduName" BO_ 701 "RHZCU_100ms_PDU11";
BA_ "VFrameFormat" BO_ 701 14;
BA_ "FrameTriggeringName" BO_ 962 "RHZCU_RHBKBCANFD_100ms_FrP19";
BA_ "GenMsgCycleTime" BO_ 962 100;
BA_ "GenMsgSendType" BO_ 962 0;
BA_ "GenMsgStartValue" BO_ 962 "0000000000000000";
BA_ "PduName" BO_ 962 "RHZCU_100ms_PDU19";
BA_ "VFrameFormat" BO_ 962 14;
BA_ "FrameTriggeringName" BO_ 943 "RHZCU_RHBKBCANFD_100ms_FrP20";
BA_ "GenMsgCycleTime" BO_ 943 100;
BA_ "GenMsgSendType" BO_ 943 0;
BA_ "GenMsgStartValue" BO_ 943 "0000000000000000";
BA_ "PduName" BO_ 943 "RHZCU_100ms_PDU20";
BA_ "VFrameFormat" BO_ 943 14;
BA_ "FrameTriggeringName" BO_ 649 "RHZCU_RHBKBCANFD_50ms_FrP01";
BA_ "GenMsgCycleTime" BO_ 649 50;
BA_ "GenMsgSendType" BO_ 649 0;
BA_ "GenMsgStartValue" BO_ 649 "00c0f01fffffffff";
BA_ "PduName" BO_ 649 "RHZCU_50ms_PDU01";
BA_ "VFrameFormat" BO_ 649 14;
BA_ "FrameTriggeringName" BO_ 940 "RHZCU_RHBKBCANFD_50ms_FrP03";
BA_ "GenMsgCycleTime" BO_ 940 50;
BA_ "GenMsgSendType" BO_ 940 0;
BA_ "GenMsgStartValue" BO_ 940 "0000000000000000";
BA_ "PduName" BO_ 940 "RHZCU_50ms_PDU03";
BA_ "VFrameFormat" BO_ 940 14;
BA_ "FrameTriggeringName" BO_ 564 "RZCU_LHBKBCANFD_50ms_FrP37";
BA_ "GenMsgCycleTime" BO_ 564 50;
BA_ "GenMsgSendType" BO_ 564 0;
BA_ "GenMsgStartValue" BO_ 564 "0000000000000000";
BA_ "PduName" BO_ 564 "RZCU_50ms_PDU37";
BA_ "VFrameFormat" BO_ 564 14;
BA_ "FrameTriggeringName" BO_ 517 "RZCU_RZCUCANFD_50ms_FrP25";
BA_ "GenMsgCycleTime" BO_ 517 50;
BA_ "GenMsgSendType" BO_ 517 0;
BA_ "GenMsgStartValue" BO_ 517 "0000000000000000";
BA_ "PduName" BO_ 517 "RZCU_50ms_PDU25";
BA_ "VFrameFormat" BO_ 517 14;
BA_ "CompuMethodName" SG_ 960 IIPDThermalWrnngLvl "IPDThermalWrnngLvl";
BA_ "ISignalName" SG_ 960 IIPDThermalWrnngLvl "IIPDThermalWrnngLvl";
BA_ "LongName" SG_ 960 IIPDThermalWrnngLvl "IPD Thermal Warning Level";
BA_ "SysSignalName" SG_ 960 IIPDThermalWrnngLvl "IPDThermalWrnngLvl";
BA_ "CompuMethodName" SG_ 960 IIPDPMICTemp "IPDPMICTemp";
BA_ "GenSigStartValue" SG_ 960 IIPDPMICTemp 255;
BA_ "ISignalName" SG_ 960 IIPDPMICTemp "IIPDPMICTemp";
BA_ "LongName" SG_ 960 IIPDPMICTemp "IPD PMIC Temperature";
BA_ "SysSignalName" SG_ 960 IIPDPMICTemp "IPDPMICTemp";
BA_ "CompuMethodName" SG_ 960 IIPDPCBTemp2 "IPDPCBTemp2";
BA_ "GenSigStartValue" SG_ 960 IIPDPCBTemp2 255;
BA_ "ISignalName" SG_ 960 IIPDPCBTemp2 "IIPDPCBTemp2";
BA_ "LongName" SG_ 960 IIPDPCBTemp2 "IPD PCB Temperature 2";
BA_ "SysSignalName" SG_ 960 IIPDPCBTemp2 "IPDPCBTemp2";
BA_ "CompuMethodName" SG_ 960 IIPDPCBTemp1 "IPDPCBTemp1";
BA_ "GenSigStartValue" SG_ 960 IIPDPCBTemp1 255;
BA_ "ISignalName" SG_ 960 IIPDPCBTemp1 "IIPDPCBTemp1";
BA_ "LongName" SG_ 960 IIPDPCBTemp1 "IPD PCB Temperature 1";
BA_ "SysSignalName" SG_ 960 IIPDPCBTemp1 "IPDPCBTemp1";
BA_ "CompuMethodName" SG_ 960 IIPDSOCTemp "IPDSOCTemp";
BA_ "GenSigStartValue" SG_ 960 IIPDSOCTemp 255;
BA_ "ISignalName" SG_ 960 IIPDSOCTemp "IIPDSOCTemp";
BA_ "LongName" SG_ 960 IIPDSOCTemp "IPD SOC Temperature";
BA_ "SysSignalName" SG_ 960 IIPDSOCTemp "IPDSOCTemp";
BA_ "CompuMethodName" SG_ 1229 ILHRDA_NM_BSMtoRMS_BKPCANFD "LHRDA_NM_BSMtoRMS_BKPCANFD";
BA_ "ISignalName" SG_ 1229 ILHRDA_NM_BSMtoRMS_BKPCANFD "ILHRDA_NM_BSMtoRMS_BKPCANFD";
BA_ "LongName" SG_ 1229 ILHRDA_NM_BSMtoRMS_BKPCANFD "LHRDA_NM_BSMtoRMS_BKPCANFD";
BA_ "SysSignalName" SG_ 1229 ILHRDA_NM_BSMtoRMS_BKPCANFD "LHRDA_NM_BSMtoRMS_BKPCANFD";
BA_ "CompuMethodName" SG_ 1229 ILHRDA_NM_PBSMtoRMS_BKPCANFD "LHRDA_NM_PBSMtoRMS_BKPCANFD";
BA_ "ISignalName" SG_ 1229 ILHRDA_NM_PBSMtoRMS_BKPCANFD "ILHRDA_NM_PBSMtoRMS_BKPCANFD";
BA_ "LongName" SG_ 1229 ILHRDA_NM_PBSMtoRMS_BKPCANFD "LHRDA_NM_PBSMtoRMS_BKPCANFD";
BA_ "SysSignalName" SG_ 1229 ILHRDA_NM_PBSMtoRMS_BKPCANFD "LHRDA_NM_PBSMtoRMS_BKPCANFD";
BA_ "CompuMethodName" SG_ 1229 ILHRDA_NM_RMStoNOS_BKPCANFD "LHRDA_NM_RMStoNOS_BKPCANFD";
BA_ "ISignalName" SG_ 1229 ILHRDA_NM_RMStoNOS_BKPCANFD "ILHRDA_NM_RMStoNOS_BKPCANFD";
BA_ "LongName" SG_ 1229 ILHRDA_NM_RMStoNOS_BKPCANFD "LHRDA_NM_RMStoNOS_BKPCANFD";
BA_ "SysSignalName" SG_ 1229 ILHRDA_NM_RMStoNOS_BKPCANFD "LHRDA_NM_RMStoNOS_BKPCANFD";
BA_ "CompuMethodName" SG_ 1229 ILHRDA_NM_RSStoNOS_BKPCANFD "LHRDA_NM_RSStoNOS_BKPCANFD";
BA_ "ISignalName" SG_ 1229 ILHRDA_NM_RSStoNOS_BKPCANFD "ILHRDA_NM_RSStoNOS_BKPCANFD";
BA_ "LongName" SG_ 1229 ILHRDA_NM_RSStoNOS_BKPCANFD "LHRDA_NM_RSStoNOS_BKPCANFD";
BA_ "SysSignalName" SG_ 1229 ILHRDA_NM_RSStoNOS_BKPCANFD "LHRDA_NM_RSStoNOS_BKPCANFD";
BA_ "CompuMethodName" SG_ 1229 ILHRDA_NM_RSStoRMS_BKPCANFD "LHRDA_NM_RSStoRMS_BKPCANFD";
BA_ "ISignalName" SG_ 1229 ILHRDA_NM_RSStoRMS_BKPCANFD "ILHRDA_NM_RSStoRMS_BKPCANFD";
BA_ "LongName" SG_ 1229 ILHRDA_NM_RSStoRMS_BKPCANFD "LHRDA_NM_RSStoRMS_BKPCANFD";
BA_ "SysSignalName" SG_ 1229 ILHRDA_NM_RSStoRMS_BKPCANFD "LHRDA_NM_RSStoRMS_BKPCANFD";
BA_ "CompuMethodName" SG_ 1229 ILHRDA_NM_NOStoRMS_BKPCANFD "LHRDA_NM_NOStoRMS_BKPCANFD";
BA_ "ISignalName" SG_ 1229 ILHRDA_NM_NOStoRMS_BKPCANFD "ILHRDA_NM_NOStoRMS_BKPCANFD";
BA_ "LongName" SG_ 1229 ILHRDA_NM_NOStoRMS_BKPCANFD "LHRDA_NM_NOStoRMS_BKPCANFD";
BA_ "SysSignalName" SG_ 1229 ILHRDA_NM_NOStoRMS_BKPCANFD "LHRDA_NM_NOStoRMS_BKPCANFD";
BA_ "CompuMethodName" SG_ 1229 ILHRDA_NM_NOSSta_BKPCANFD "LHRDA_NM_NOSSta_BKPCANFD";
BA_ "ISignalName" SG_ 1229 ILHRDA_NM_NOSSta_BKPCANFD "ILHRDA_NM_NOSSta_BKPCANFD";
BA_ "LongName" SG_ 1229 ILHRDA_NM_NOSSta_BKPCANFD "LHRDA_NM_NOSSta_BKPCANFD";
BA_ "SysSignalName" SG_ 1229 ILHRDA_NM_NOSSta_BKPCANFD "LHRDA_NM_NOSSta_BKPCANFD";
BA_ "CompuMethodName" SG_ 1229 ILHRDA_NM_RMSSta_BKPCANFD "LHRDA_NM_RMSSta_BKPCANFD";
BA_ "ISignalName" SG_ 1229 ILHRDA_NM_RMSSta_BKPCANFD "ILHRDA_NM_RMSSta_BKPCANFD";
BA_ "LongName" SG_ 1229 ILHRDA_NM_RMSSta_BKPCANFD "LHRDA_NM_RMSSta_BKPCANFD";
BA_ "SysSignalName" SG_ 1229 ILHRDA_NM_RMSSta_BKPCANFD "LHRDA_NM_RMSSta_BKPCANFD";
BA_ "CompuMethodName" SG_ 1229 ILHRDA_NWI_BKPCANFD "LHRDA_NWI_BKPCANFD";
BA_ "ISignalName" SG_ 1229 ILHRDA_NWI_BKPCANFD "ILHRDA_NWI_BKPCANFD";
BA_ "LongName" SG_ 1229 ILHRDA_NWI_BKPCANFD "LHRDA BKPCANFD Network_Wakeup_Indication";
BA_ "SysSignalName" SG_ 1229 ILHRDA_NWI_BKPCANFD "LHRDA_NWI_BKPCANFD";
BA_ "CompuMethodName" SG_ 1229 ILHRDA_NOI_BKPCANFD "LHRDA_NOI_BKPCANFD";
BA_ "ISignalName" SG_ 1229 ILHRDA_NOI_BKPCANFD "ILHRDA_NOI_BKPCANFD";
BA_ "LongName" SG_ 1229 ILHRDA_NOI_BKPCANFD "LHRDA BKPCANFD Network Operation Indication";
BA_ "SysSignalName" SG_ 1229 ILHRDA_NOI_BKPCANFD "LHRDA_NOI_BKPCANFD";
BA_ "CompuMethodName" SG_ 1229 ILHRDA_NKI_BKPCANFD "LHRDA_NKI_BKPCANFD";
BA_ "ISignalName" SG_ 1229 ILHRDA_NKI_BKPCANFD "ILHRDA_NKI_BKPCANFD";
BA_ "LongName" SG_ 1229 ILHRDA_NKI_BKPCANFD "LHRDA BKPCANFD Network Keep Indication";
BA_ "SysSignalName" SG_ 1229 ILHRDA_NKI_BKPCANFD "LHRDA_NKI_BKPCANFD";
BA_ "CompuMethodName" SG_ 181 IDircnLghtOnReq_LHZCU "DircnLghtOnReq_LHZCU";
BA_ "ISignalName" SG_ 181 IDircnLghtOnReq_LHZCU "IDircnLghtOnReq_LHZCU";
BA_ "LongName" SG_ 181 IDircnLghtOnReq_LHZCU "Direction Light On Request";
BA_ "SysSignalName" SG_ 181 IDircnLghtOnReq_LHZCU "DircnLghtOnReq_LHZCU";
BA_ "CompuMethodName" SG_ 1149 ITPMSAutoLoctnCm "TPMSAutoLoctnCm";
BA_ "GenSigStartValue" SG_ 1149 ITPMSAutoLoctnCm 1;
BA_ "ISignalName" SG_ 1149 ITPMSAutoLoctnCm "ITPMSAutoLoctnCm";
BA_ "LongName" SG_ 1149 ITPMSAutoLoctnCm "Tire_Pressure_Monitor_System_Auto_Location_Complete";
BA_ "SysSignalName" SG_ 1149 ITPMSAutoLoctnCm "TPMSAutoLoctnCm";
BA_ "CompuMethodName" SG_ 1149 IFRTireSts "FRTireSts";
BA_ "ISignalName" SG_ 1149 IFRTireSts "IFRTireSts";
BA_ "LongName" SG_ 1149 IFRTireSts "Front_Right_Tire_Status";
BA_ "SysSignalName" SG_ 1149 IFRTireSts "FRTireSts";
BA_ "CompuMethodName" SG_ 1149 IFLTireSts "FLTireSts";
BA_ "ISignalName" SG_ 1149 IFLTireSts "IFLTireSts";
BA_ "LongName" SG_ 1149 IFLTireSts "Front_Left_Tire_Status";
BA_ "SysSignalName" SG_ 1149 IFLTireSts "FLTireSts";
BA_ "CompuMethodName" SG_ 1149 ITPMSIdficnLrnCm "TPMSIdficnLrnCm";
BA_ "GenSigStartValue" SG_ 1149 ITPMSIdficnLrnCm 1;
BA_ "ISignalName" SG_ 1149 ITPMSIdficnLrnCm "ITPMSIdficnLrnCm";
BA_ "LongName" SG_ 1149 ITPMSIdficnLrnCm "Tire_Pressure_Monitor_System_Identification_Learn_Complete";
BA_ "SysSignalName" SG_ 1149 ITPMSIdficnLrnCm "TPMSIdficnLrnCm";
BA_ "CompuMethodName" SG_ 1149 IRRTireSts "RRTireSts";
BA_ "ISignalName" SG_ 1149 IRRTireSts "IRRTireSts";
BA_ "LongName" SG_ 1149 IRRTireSts "Rear_Right_Tire_Status";
BA_ "SysSignalName" SG_ 1149 IRRTireSts "RRTireSts";
BA_ "CompuMethodName" SG_ 1149 IRLTireSts "RLTireSts";
BA_ "ISignalName" SG_ 1149 IRLTireSts "IRLTireSts";
BA_ "LongName" SG_ 1149 IRLTireSts "Rear_Left_Tire_Status";
BA_ "SysSignalName" SG_ 1149 IRLTireSts "RLTireSts";
BA_ "CompuMethodName" SG_ 1149 IRRTirePrs "RRTirePrs";
BA_ "GenSigStartValue" SG_ 1149 IRRTirePrs 55;
BA_ "ISignalName" SG_ 1149 IRRTirePrs "IRRTirePrs";
BA_ "LongName" SG_ 1149 IRRTirePrs "Rear_Right_Tire_Pressure";
BA_ "SysSignalName" SG_ 1149 IRRTirePrs "RRTirePrs";
BA_ "CompuMethodName" SG_ 1149 ITPMSWntrMdA "TPMSWntrMdA";
BA_ "ISignalName" SG_ 1149 ITPMSWntrMdA "ITPMSWntrMdA";
BA_ "LongName" SG_ 1149 ITPMSWntrMdA "Tire Pressure Monitor System Winter Mode Active";
BA_ "SysSignalName" SG_ 1149 ITPMSWntrMdA "TPMSWntrMdA";
BA_ "CompuMethodName" SG_ 1149 IRLTirePrs "RLTirePrs";
BA_ "GenSigStartValue" SG_ 1149 IRLTirePrs 55;
BA_ "ISignalName" SG_ 1149 IRLTirePrs "IRLTirePrs";
BA_ "LongName" SG_ 1149 IRLTirePrs "Rear_Left_Tire_Pressure";
BA_ "SysSignalName" SG_ 1149 IRLTirePrs "RLTirePrs";
BA_ "CompuMethodName" SG_ 1149 IRLTirePrsV "RLTirePrsV";
BA_ "ISignalName" SG_ 1149 IRLTirePrsV "IRLTirePrsV";
BA_ "LongName" SG_ 1149 IRLTirePrsV "Rear_Left_Tire_Pressure_Validity";
BA_ "SysSignalName" SG_ 1149 IRLTirePrsV "RLTirePrsV";
BA_ "CompuMethodName" SG_ 1149 IFRTirePrs "FRTirePrs";
BA_ "GenSigStartValue" SG_ 1149 IFRTirePrs 55;
BA_ "ISignalName" SG_ 1149 IFRTirePrs "IFRTirePrs";
BA_ "LongName" SG_ 1149 IFRTirePrs "Front_Right_Tire_Pressure";
BA_ "SysSignalName" SG_ 1149 IFRTirePrs "FRTirePrs";
BA_ "CompuMethodName" SG_ 1149 IFRTirePrsV "FRTirePrsV";
BA_ "ISignalName" SG_ 1149 IFRTirePrsV "IFRTirePrsV";
BA_ "LongName" SG_ 1149 IFRTirePrsV "Front_Right_Tire_Pressure_Validity";
BA_ "SysSignalName" SG_ 1149 IFRTirePrsV "FRTirePrsV";
BA_ "CompuMethodName" SG_ 1149 IRRTirePrsV "RRTirePrsV";
BA_ "ISignalName" SG_ 1149 IRRTirePrsV "IRRTirePrsV";
BA_ "LongName" SG_ 1149 IRRTirePrsV "Rear_Right_Tire_Pressure_Validity";
BA_ "SysSignalName" SG_ 1149 IRRTirePrsV "RRTirePrsV";
BA_ "CompuMethodName" SG_ 1149 IFLTirePrs "FLTirePrs";
BA_ "GenSigStartValue" SG_ 1149 IFLTirePrs 55;
BA_ "ISignalName" SG_ 1149 IFLTirePrs "IFLTirePrs";
BA_ "LongName" SG_ 1149 IFLTirePrs "Front_Left_Tire_Pressure";
BA_ "SysSignalName" SG_ 1149 IFLTirePrs "FLTirePrs";
BA_ "CompuMethodName" SG_ 1149 IFLTirePrsV "FLTirePrsV";
BA_ "ISignalName" SG_ 1149 IFLTirePrsV "IFLTirePrsV";
BA_ "LongName" SG_ 1149 IFLTirePrsV "Front_Left_Tire_Pressure_Validity";
BA_ "SysSignalName" SG_ 1149 IFLTirePrsV "FLTirePrsV";
BA_ "CompuMethodName" SG_ 638 IVehIlluminateCtrlCmd "VehIlluminateCtrlCmd";
BA_ "ISignalName" SG_ 638 IVehIlluminateCtrlCmd "IVehIlluminateCtrlCmd";
BA_ "LongName" SG_ 638 IVehIlluminateCtrlCmd "Vehicle Illuminate Control Command";
BA_ "SysSignalName" SG_ 638 IVehIlluminateCtrlCmd "VehIlluminateCtrlCmd";
BA_ "CompuMethodName" SG_ 638 IBrkLghtSta "BrkLghtSta";
BA_ "ISignalName" SG_ 638 IBrkLghtSta "IBrkLghtSta";
BA_ "LongName" SG_ 638 IBrkLghtSta "Brake_Light_State";
BA_ "SysSignalName" SG_ 638 IBrkLghtSta "BrkLghtSta";
BA_ "CompuMethodName" SG_ 638 IBrkLghtFltSta "BrkLghtFltSta";
BA_ "ISignalName" SG_ 638 IBrkLghtFltSta "IBrkLghtFltSta";
BA_ "LongName" SG_ 638 IBrkLghtFltSta "Brake_Light_Fault_State";
BA_ "SysSignalName" SG_ 638 IBrkLghtFltSta "BrkLghtFltSta";
BA_ "CompuMethodName" SG_ 638 IDircnLghtSts "DircnLghtSts";
BA_ "ISignalName" SG_ 638 IDircnLghtSts "IDircnLghtSts";
BA_ "LongName" SG_ 638 IDircnLghtSts "Direction_Light_Status";
BA_ "SysSignalName" SG_ 638 IDircnLghtSts "DircnLghtSts";
BA_ "CompuMethodName" SG_ 638 IDircnLghtMdSts "DircnLghtMdSts";
BA_ "ISignalName" SG_ 638 IDircnLghtMdSts "IDircnLghtMdSts";
BA_ "LongName" SG_ 638 IDircnLghtMdSts "Direction_Light_Mode_Status";
BA_ "SysSignalName" SG_ 638 IDircnLghtMdSts "DircnLghtMdSts";
BA_ "CompuMethodName" SG_ 638 IRevsLghtFltSta "RevsLghtFltSta";
BA_ "ISignalName" SG_ 638 IRevsLghtFltSta "IRevsLghtFltSta";
BA_ "LongName" SG_ 638 IRevsLghtFltSta "Reverse_Light_Fault_State";
BA_ "SysSignalName" SG_ 638 IRevsLghtFltSta "RevsLghtFltSta";
BA_ "CompuMethodName" SG_ 638 IRevsLghtSta "RevsLghtSta";
BA_ "ISignalName" SG_ 638 IRevsLghtSta "IRevsLghtSta";
BA_ "LongName" SG_ 638 IRevsLghtSta "Reverse_Light_State";
BA_ "SysSignalName" SG_ 638 IRevsLghtSta "RevsLghtSta";
BA_ "CompuMethodName" SG_ 638 IRearFogLghtAcFltsts "RearFogLghtAcFltsts";
BA_ "ISignalName" SG_ 638 IRearFogLghtAcFltsts "IRearFogLghtAcFltsts";
BA_ "LongName" SG_ 638 IRearFogLghtAcFltsts "Rear_Fog_Light_Active_Fault_Status";
BA_ "SysSignalName" SG_ 638 IRearFogLghtAcFltsts "RearFogLghtAcFltsts";
BA_ "CompuMethodName" SG_ 638 IRearFogLghtAcSts "RearFogLghtAcSts";
BA_ "ISignalName" SG_ 638 IRearFogLghtAcSts "IRearFogLghtAcSts";
BA_ "LongName" SG_ 638 IRearFogLghtAcSts "Rear_Fog_Light__Active_Status";
BA_ "SysSignalName" SG_ 638 IRearFogLghtAcSts "RearFogLghtAcSts";
BA_ "CompuMethodName" SG_ 638 IRearFogLghtCtrl "RearFogLghtCtrl";
BA_ "ISignalName" SG_ 638 IRearFogLghtCtrl "IRearFogLghtCtrl";
BA_ "LongName" SG_ 638 IRearFogLghtCtrl "Rear_Fog_Light_Control";
BA_ "SysSignalName" SG_ 638 IRearFogLghtCtrl "RearFogLghtCtrl";
BA_ "CompuMethodName" SG_ 638 ISideLghtFltsts "SideLghtFltsts";
BA_ "ISignalName" SG_ 638 ISideLghtFltsts "ISideLghtFltsts";
BA_ "LongName" SG_ 638 ISideLghtFltsts "Side_Light_Fault_Status";
BA_ "SysSignalName" SG_ 638 ISideLghtFltsts "SideLghtFltsts";
BA_ "CompuMethodName" SG_ 638 IRRSideLghtCtrl "RRSideLghtCtrl";
BA_ "ISignalName" SG_ 638 IRRSideLghtCtrl "IRRSideLghtCtrl";
BA_ "LongName" SG_ 638 IRRSideLghtCtrl "Right_Rear_Side_Light_Control";
BA_ "SysSignalName" SG_ 638 IRRSideLghtCtrl "RRSideLghtCtrl";
BA_ "CompuMethodName" SG_ 638 IRLSideLghtCtrl "RLSideLghtCtrl";
BA_ "ISignalName" SG_ 638 IRLSideLghtCtrl "IRLSideLghtCtrl";
BA_ "LongName" SG_ 638 IRLSideLghtCtrl "Left_Rear_Side_Light_Control";
BA_ "SysSignalName" SG_ 638 IRLSideLghtCtrl "RLSideLghtCtrl";
BA_ "CompuMethodName" SG_ 638 IHdlmpLvlngFltSts "HdlmpLvlngFltSts";
BA_ "ISignalName" SG_ 638 IHdlmpLvlngFltSts "IHdlmpLvlngFltSts";
BA_ "LongName" SG_ 638 IHdlmpLvlngFltSts "Headlamp_Leveling_Fault_Status";
BA_ "SysSignalName" SG_ 638 IHdlmpLvlngFltSts "HdlmpLvlngFltSts";
BA_ "CompuMethodName" SG_ 638 IHdlmpLvlngCrtl "HdlmpLvlngCrtl";
BA_ "ISignalName" SG_ 638 IHdlmpLvlngCrtl "IHdlmpLvlngCrtl";
BA_ "LongName" SG_ 638 IHdlmpLvlngCrtl "Headlamp_Leveling_Control";
BA_ "SysSignalName" SG_ 638 IHdlmpLvlngCrtl "HdlmpLvlngCrtl";
BA_ "CompuMethodName" SG_ 638 IDayTmRunngLghtFltsts "DayTmRunngLghtFltsts";
BA_ "ISignalName" SG_ 638 IDayTmRunngLghtFltsts "IDayTmRunngLghtFltsts";
BA_ "LongName" SG_ 638 IDayTmRunngLghtFltsts "Day_time_Running_Light_Fault_Status";
BA_ "SysSignalName" SG_ 638 IDayTmRunngLghtFltsts "DayTmRunngLghtFltsts";
BA_ "CompuMethodName" SG_ 638 IDayTmRunngLghtSts "DayTmRunngLghtSts";
BA_ "ISignalName" SG_ 638 IDayTmRunngLghtSts "IDayTmRunngLghtSts";
BA_ "LongName" SG_ 638 IDayTmRunngLghtSts "Day_time_Running_Light_Status";
BA_ "SysSignalName" SG_ 638 IDayTmRunngLghtSts "DayTmRunngLghtSts";
BA_ "CompuMethodName" SG_ 638 IFrtFogLghtSts "FrtFogLghtSts";
BA_ "ISignalName" SG_ 638 IFrtFogLghtSts "IFrtFogLghtSts";
BA_ "LongName" SG_ 638 IFrtFogLghtSts "Left_Front_Fog_Light_Status";
BA_ "SysSignalName" SG_ 638 IFrtFogLghtSts "FrtFogLghtSts";
BA_ "CompuMethodName" SG_ 638 IRFrtFogLghtCtrl "RFrtFogLghtCtrl";
BA_ "ISignalName" SG_ 638 IRFrtFogLghtCtrl "IRFrtFogLghtCtrl";
BA_ "LongName" SG_ 638 IRFrtFogLghtCtrl "Right_Front_Fog_Light_Control";
BA_ "SysSignalName" SG_ 638 IRFrtFogLghtCtrl "RFrtFogLghtCtrl";
BA_ "CompuMethodName" SG_ 638 ILFrtFogLghtCtrl "LFrtFogLghtCtrl";
BA_ "ISignalName" SG_ 638 ILFrtFogLghtCtrl "ILFrtFogLghtCtrl";
BA_ "LongName" SG_ 638 ILFrtFogLghtCtrl "Left_Front_Fog_Light_Control";
BA_ "SysSignalName" SG_ 638 ILFrtFogLghtCtrl "LFrtFogLghtCtrl";
BA_ "CompuMethodName" SG_ 638 IHdlmpLvlngSts "HdlmpLvlngSts";
BA_ "ISignalName" SG_ 638 IHdlmpLvlngSts "IHdlmpLvlngSts";
BA_ "LongName" SG_ 638 IHdlmpLvlngSts "Headlamp_Leveling_Status";
BA_ "SysSignalName" SG_ 638 IHdlmpLvlngSts "HdlmpLvlngSts";
BA_ "CompuMethodName" SG_ 638 IDircnLghtSwReq "DircnLghtSwReq";
BA_ "ISignalName" SG_ 638 IDircnLghtSwReq "IDircnLghtSwReq";
BA_ "LongName" SG_ 638 IDircnLghtSwReq "Direction_Light_Switch_Request";
BA_ "SysSignalName" SG_ 638 IDircnLghtSwReq "DircnLghtSwReq";
BA_ "CompuMethodName" SG_ 638 IFrtFogLghtFltSts "FrtFogLghtFltSts";
BA_ "ISignalName" SG_ 638 IFrtFogLghtFltSts "IFrtFogLghtFltSts";
BA_ "LongName" SG_ 638 IFrtFogLghtFltSts "Right_Front_Fog_Light_Status";
BA_ "SysSignalName" SG_ 638 IFrtFogLghtFltSts "FrtFogLghtFltSts";
BA_ "CompuMethodName" SG_ 638 IDircnLghtFltsts "DircnLghtFltsts";
BA_ "ISignalName" SG_ 638 IDircnLghtFltsts "IDircnLghtFltsts";
BA_ "LongName" SG_ 638 IDircnLghtFltsts "Direction_Light_Fault_Status";
BA_ "SysSignalName" SG_ 638 IDircnLghtFltsts "DircnLghtFltsts";
BA_ "CompuMethodName" SG_ 745 IAutoMainBeamLghtOn "AutoMainBeamLghtOn";
BA_ "ISignalName" SG_ 745 IAutoMainBeamLghtOn "IAutoMainBeamLghtOn";
BA_ "LongName" SG_ 745 IAutoMainBeamLghtOn "Auto Main Beam Light On";
BA_ "SysSignalName" SG_ 745 IAutoMainBeamLghtOn "AutoMainBeamLghtOn";
BA_ "CompuMethodName" SG_ 745 IMainBeamLghtOn "MainBeamLghtOn";
BA_ "ISignalName" SG_ 745 IMainBeamLghtOn "IMainBeamLghtOn";
BA_ "LongName" SG_ 745 IMainBeamLghtOn "Main_Beam_Light_On";
BA_ "SysSignalName" SG_ 745 IMainBeamLghtOn "MainBeamLghtOn";
BA_ "CompuMethodName" SG_ 745 IRLDoorLckSts "RLDoorLckSts";
BA_ "ISignalName" SG_ 745 IRLDoorLckSts "IRLDoorLckSts";
BA_ "LongName" SG_ 745 IRLDoorLckSts "Rear Left Door Lock Status";
BA_ "SysSignalName" SG_ 745 IRLDoorLckSts "RLDoorLckSts";
BA_ "CompuMethodName" SG_ 745 IComfortDircnLghtDsp "ComfortDircnLghtDsp";
BA_ "ISignalName" SG_ 745 IComfortDircnLghtDsp "IComfortDircnLghtDsp";
BA_ "LongName" SG_ 745 IComfortDircnLghtDsp "Comfortable Direction Light Display";
BA_ "SysSignalName" SG_ 745 IComfortDircnLghtDsp "ComfortDircnLghtDsp";
BA_ "CompuMethodName" SG_ 745 IFrtWiperTemp "FrtWiperTemp";
BA_ "ISignalName" SG_ 745 IFrtWiperTemp "IFrtWiperTemp";
BA_ "LongName" SG_ 745 IFrtWiperTemp "Front Wiper Temperature";
BA_ "SysSignalName" SG_ 745 IFrtWiperTemp "FrtWiperTemp";
BA_ "CompuMethodName" SG_ 745 IDircnLghtMdDsp "DircnLghtMdDsp";
BA_ "ISignalName" SG_ 745 IDircnLghtMdDsp "IDircnLghtMdDsp";
BA_ "LongName" SG_ 745 IDircnLghtMdDsp "Driection light Mode Display";
BA_ "SysSignalName" SG_ 745 IDircnLghtMdDsp "DircnLghtMdDsp";
BA_ "CompuMethodName" SG_ 745 IAllWndAndSrfLazyClsReq "AllWndAndSrfLazyClsReq";
BA_ "ISignalName" SG_ 745 IAllWndAndSrfLazyClsReq "IAllWndAndSrfLazyClsReq";
BA_ "LongName" SG_ 745 IAllWndAndSrfLazyClsReq "All Window And Sunroof Lazy Close Request";
BA_ "SysSignalName" SG_ 745 IAllWndAndSrfLazyClsReq "AllWndAndSrfLazyClsReq";
BA_ "CompuMethodName" SG_ 745 IRrSrvcPosReq "RrSrvcPosReq";
BA_ "ISignalName" SG_ 745 IRrSrvcPosReq "IRrSrvcPosReq";
BA_ "LongName" SG_ 745 IRrSrvcPosReq "Rear Service Position Request";
BA_ "SysSignalName" SG_ 745 IRrSrvcPosReq "RrSrvcPosReq";
BA_ "CompuMethodName" SG_ 745 IRrWiperFnEnb "RrWiperFnEnb";
BA_ "ISignalName" SG_ 745 IRrWiperFnEnb "IRrWiperFnEnb";
BA_ "LongName" SG_ 745 IRrWiperFnEnb "Rear Wiper Function Enable";
BA_ "SysSignalName" SG_ 745 IRrWiperFnEnb "RrWiperFnEnb";
BA_ "CompuMethodName" SG_ 1150 ITPMSF "TPMSF";
BA_ "ISignalName" SG_ 1150 ITPMSF "ITPMSF";
BA_ "LongName" SG_ 1150 ITPMSF "Tire Pressure Monitor System Failed";
BA_ "SysSignalName" SG_ 1150 ITPMSF "TPMSF";
BA_ "CompuMethodName" SG_ 1150 ITPMSTirePrsLowIO "TPMSTirePrsLowIO";
BA_ "ISignalName" SG_ 1150 ITPMSTirePrsLowIO "ITPMSTirePrsLowIO";
BA_ "LongName" SG_ 1150 ITPMSTirePrsLowIO "Tire Pressure Monitor System Tire Pressure Low Indication On";
BA_ "SysSignalName" SG_ 1150 ITPMSTirePrsLowIO "TPMSTirePrsLowIO";
BA_ "CompuMethodName" SG_ 784 IVehLckTypResp "VehLckTypResp";
BA_ "ISignalName" SG_ 784 IVehLckTypResp "IVehLckTypResp";
BA_ "LongName" SG_ 784 IVehLckTypResp "Vehicle Lock Type Response";
BA_ "SysSignalName" SG_ 784 IVehLckTypResp "VehLckTypResp";
BA_ "CompuMethodName" SG_ 784 IVehLckActnFailRsn "VehLckActnFailRsn";
BA_ "ISignalName" SG_ 784 IVehLckActnFailRsn "IVehLckActnFailRsn";
BA_ "LongName" SG_ 784 IVehLckActnFailRsn "Vehicle Lock Action Fail Reason";
BA_ "SysSignalName" SG_ 784 IVehLckActnFailRsn "VehLckActnFailRsn";
BA_ "CompuMethodName" SG_ 784 IRLWinShrtDwnSucd "RLWinShrtDwnSucd";
BA_ "ISignalName" SG_ 784 IRLWinShrtDwnSucd "IRLWinShrtDwnSucd";
BA_ "LongName" SG_ 784 IRLWinShrtDwnSucd "Rear Left Window short down successed";
BA_ "SysSignalName" SG_ 784 IRLWinShrtDwnSucd "RLWinShrtDwnSucd";
BA_ "CompuMethodName" SG_ 784 IFLWinShrtDwnSucd "FLWinShrtDwnSucd";
BA_ "ISignalName" SG_ 784 IFLWinShrtDwnSucd "IFLWinShrtDwnSucd";
BA_ "LongName" SG_ 784 IFLWinShrtDwnSucd "Front Left Window short down successed";
BA_ "SysSignalName" SG_ 784 IFLWinShrtDwnSucd "FLWinShrtDwnSucd";
BA_ "CompuMethodName" SG_ 784 ILOtsdMirFoldSts "LOtsdMirFoldSts";
BA_ "ISignalName" SG_ 784 ILOtsdMirFoldSts "ILOtsdMirFoldSts";
BA_ "LongName" SG_ 784 ILOtsdMirFoldSts "Left Outside Mirror Fold Status";
BA_ "SysSignalName" SG_ 784 ILOtsdMirFoldSts "LOtsdMirFoldSts";
BA_ "CompuMethodName" SG_ 784 IHtdFrtLftVwWndFaltSts "HtdFrtLftVwWndFaltSts";
BA_ "ISignalName" SG_ 784 IHtdFrtLftVwWndFaltSts "IHtdFrtLftVwWndFaltSts";
BA_ "LongName" SG_ 784 IHtdFrtLftVwWndFaltSts "Heated Front  Left View Window Fault Status";
BA_ "SysSignalName" SG_ 784 IHtdFrtLftVwWndFaltSts "HtdFrtLftVwWndFaltSts";
BA_ "CompuMethodName" SG_ 784 IRLWinMotSts "RLWinMotSts";
BA_ "ISignalName" SG_ 784 IRLWinMotSts "IRLWinMotSts";
BA_ "LongName" SG_ 784 IRLWinMotSts "Rear Left Window Motor Status";
BA_ "SysSignalName" SG_ 784 IRLWinMotSts "RLWinMotSts";
BA_ "CompuMethodName" SG_ 784 IRLWinLclSwtSts "RLWinLclSwtSts";
BA_ "ISignalName" SG_ 784 IRLWinLclSwtSts "IRLWinLclSwtSts";
BA_ "LongName" SG_ 784 IRLWinLclSwtSts "Rear Left Window Local Switch Status";
BA_ "SysSignalName" SG_ 784 IRLWinLclSwtSts "RLWinLclSwtSts";
BA_ "CompuMethodName" SG_ 784 ILckSysStsIndcn "LckSysStsIndcn";
BA_ "ISignalName" SG_ 784 ILckSysStsIndcn "ILckSysStsIndcn";
BA_ "LongName" SG_ 784 ILckSysStsIndcn "Lock System Status Indication";
BA_ "SysSignalName" SG_ 784 ILckSysStsIndcn "LckSysStsIndcn";
BA_ "CompuMethodName" SG_ 784 IFLWinMotSts "FLWinMotSts";
BA_ "ISignalName" SG_ 784 IFLWinMotSts "IFLWinMotSts";
BA_ "LongName" SG_ 784 IFLWinMotSts "Front Left Window Motor Status";
BA_ "SysSignalName" SG_ 784 IFLWinMotSts "FLWinMotSts";
BA_ "CompuMethodName" SG_ 784 IFLDoorLckSts "FLDoorLckSts";
BA_ "ISignalName" SG_ 784 IFLDoorLckSts "IFLDoorLckSts";
BA_ "LongName" SG_ 784 IFLDoorLckSts "Front Left Door Lock Status";
BA_ "SysSignalName" SG_ 784 IFLDoorLckSts "FLDoorLckSts";
BA_ "CompuMethodName" SG_ 800 IRrWinInhbSwtSts "RrWinInhbSwtSts";
BA_ "ISignalName" SG_ 800 IRrWinInhbSwtSts "IRrWinInhbSwtSts";
BA_ "LongName" SG_ 800 IRrWinInhbSwtSts "Rear Window Inhibit Switch Status";
BA_ "SysSignalName" SG_ 800 IRrWinInhbSwtSts "RrWinInhbSwtSts";
BA_ "CompuMethodName" SG_ 800 IRrWinInhbSwtFlt "RrWinInhbSwtFlt";
BA_ "ISignalName" SG_ 800 IRrWinInhbSwtFlt "IRrWinInhbSwtFlt";
BA_ "LongName" SG_ 800 IRrWinInhbSwtFlt "Rear Window Inhibit Switch Fault";
BA_ "SysSignalName" SG_ 800 IRrWinInhbSwtFlt "RrWinInhbSwtFlt";
BA_ "CompuMethodName" SG_ 800 IBCMOdoReq "BCMOdoReq";
BA_ "ISignalName" SG_ 800 IBCMOdoReq "IBCMOdoReq";
BA_ "LongName" SG_ 800 IBCMOdoReq "Body Control Module Odometer Request";
BA_ "SysSignalName" SG_ 800 IBCMOdoReq "BCMOdoReq";
BA_ "CompuMethodName" SG_ 800 IDircnIndLampSwStsMntry "DircnIndLampSwStsMntry";
BA_ "ISignalName" SG_ 800 IDircnIndLampSwStsMntry "IDircnIndLampSwStsMntry";
BA_ "LongName" SG_ 800 IDircnIndLampSwStsMntry "Direction Indication Lamp Switch Status Momentary";
BA_ "SysSignalName" SG_ 800 IDircnIndLampSwStsMntry "DircnIndLampSwStsMntry";
BA_ "CompuMethodName" SG_ 800 IOdoSecy "OdoSecy";
BA_ "ISignalName" SG_ 800 IOdoSecy "IOdoSecy";
BA_ "LongName" SG_ 800 IOdoSecy "Odometer Secondary";
BA_ "SysSignalName" SG_ 800 IOdoSecy "OdoSecy";
BA_ "CompuMethodName" SG_ 800 IImmoSubModTCAuthnRunSts "ImmoSubModTCAuthnRunSts";
BA_ "ISignalName" SG_ 800 IImmoSubModTCAuthnRunSts "IImmoSubModTCAuthnRunSts";
BA_ "LongName" SG_ 800 IImmoSubModTCAuthnRunSts "Immobilizer_Sub_Module_Traction_Controller_Authentication_Run_Status";
BA_ "SysSignalName" SG_ 800 IImmoSubModTCAuthnRunSts "ImmoSubModTCAuthnRunSts";
BA_ "CompuMethodName" SG_ 800 IImmoSubModSACAuthnRunSts "ImmoSubModSACAuthnRunSts";
BA_ "ISignalName" SG_ 800 IImmoSubModSACAuthnRunSts "IImmoSubModSACAuthnRunSts";
BA_ "LongName" SG_ 800 IImmoSubModSACAuthnRunSts "Immobilizer_Sub_Module_Sencondery_Axis_Controller_Authentication_Run_Status";
BA_ "SysSignalName" SG_ 800 IImmoSubModSACAuthnRunSts "ImmoSubModSACAuthnRunSts";
BA_ "CompuMethodName" SG_ 800 IMainBeamSwPosSts "MainBeamSwPosSts";
BA_ "ISignalName" SG_ 800 IMainBeamSwPosSts "IMainBeamSwPosSts";
BA_ "LongName" SG_ 800 IMainBeamSwPosSts "Main Beam Switch Position Status";
BA_ "SysSignalName" SG_ 800 IMainBeamSwPosSts "MainBeamSwPosSts";
BA_ "CompuMethodName" SG_ 800 IEDRDircnIndLampSwSts "EDRDircnIndLampSwSts";
BA_ "ISignalName" SG_ 800 IEDRDircnIndLampSwSts "IEDRDircnIndLampSwSts";
BA_ "LongName" SG_ 800 IEDRDircnIndLampSwSts "EDR direction indication lamp switch status";
BA_ "SysSignalName" SG_ 800 IEDRDircnIndLampSwSts "EDRDircnIndLampSwSts";
BA_ "CompuMethodName" SG_ 800 IRFKeyAuthnChrgInhbtReq "RFKeyAuthnChrgInhbtReq";
BA_ "ISignalName" SG_ 800 IRFKeyAuthnChrgInhbtReq "IRFKeyAuthnChrgInhbtReq";
BA_ "LongName" SG_ 800 IRFKeyAuthnChrgInhbtReq "RFKey Authentication Charging Inhibit Request";
BA_ "SysSignalName" SG_ 800 IRFKeyAuthnChrgInhbtReq "RFKeyAuthnChrgInhbtReq";
BA_ "CompuMethodName" SG_ 905 ISmtKeyAuthnMnModRunSts "SmtKeyAuthnMnModRunSts";
BA_ "ISignalName" SG_ 905 ISmtKeyAuthnMnModRunSts "ISmtKeyAuthnMnModRunSts";
BA_ "LongName" SG_ 905 ISmtKeyAuthnMnModRunSts "Smart_Key__Authentication_Platform_Run_Status";
BA_ "SysSignalName" SG_ 905 ISmtKeyAuthnMnModRunSts "SmtKeyAuthnMnModRunSts";
BA_ "CompuMethodName" SG_ 905 IHtdFrtLftVwWndActSts "HtdFrtLftVwWndActSts";
BA_ "ISignalName" SG_ 905 IHtdFrtLftVwWndActSts "IHtdFrtLftVwWndActSts";
BA_ "LongName" SG_ 905 IHtdFrtLftVwWndActSts "Heated Front  Left View Window Actual Status";
BA_ "SysSignalName" SG_ 905 IHtdFrtLftVwWndActSts "HtdFrtLftVwWndActSts";
BA_ "CompuMethodName" SG_ 905 ILOtsdMirActSts "LOtsdMirActSts";
BA_ "ISignalName" SG_ 905 ILOtsdMirActSts "ILOtsdMirActSts";
BA_ "LongName" SG_ 905 ILOtsdMirActSts "Left_Outside_Mirror_Action_Status";
BA_ "SysSignalName" SG_ 905 ILOtsdMirActSts "LOtsdMirActSts";
BA_ "CompuMethodName" SG_ 905 IFrtWindShldSurndHmdty "FrtWindShldSurndHmdty";
BA_ "ISignalName" SG_ 905 IFrtWindShldSurndHmdty "IFrtWindShldSurndHmdty";
BA_ "LongName" SG_ 905 IFrtWindShldSurndHmdty "Front Windsheld Surround Humidity";
BA_ "SysSignalName" SG_ 905 IFrtWindShldSurndHmdty "FrtWindShldSurndHmdty";
BA_ "CompuMethodName" SG_ 905 ISolarStrngLSide "SolarStrngLSide";
BA_ "ISignalName" SG_ 905 ISolarStrngLSide "ISolarStrngLSide";
BA_ "LongName" SG_ 905 ISolarStrngLSide "Solar Strength Left Side";
BA_ "SysSignalName" SG_ 905 ISolarStrngLSide "SolarStrngLSide";
BA_ "CompuMethodName" SG_ 905 ISolarStrngRSide "SolarStrngRSide";
BA_ "ISignalName" SG_ 905 ISolarStrngRSide "ISolarStrngRSide";
BA_ "LongName" SG_ 905 ISolarStrngRSide "Solar Strength Right Side";
BA_ "SysSignalName" SG_ 905 ISolarStrngRSide "SolarStrngRSide";
BA_ "CompuMethodName" SG_ 905 IFrtWindShldSurndTem "FrtWindShldSurndTem";
BA_ "ISignalName" SG_ 905 IFrtWindShldSurndTem "IFrtWindShldSurndTem";
BA_ "LongName" SG_ 905 IFrtWindShldSurndTem "Front Windsheld Surround Temperature";
BA_ "SysSignalName" SG_ 905 IFrtWindShldSurndTem "FrtWindShldSurndTem";
BA_ "CompuMethodName" SG_ 905 IFrtWindShldSfcTem "FrtWindShldSfcTem";
BA_ "ISignalName" SG_ 905 IFrtWindShldSfcTem "IFrtWindShldSfcTem";
BA_ "LongName" SG_ 905 IFrtWindShldSfcTem "Front Windsheld Surface Temperature";
BA_ "SysSignalName" SG_ 905 IFrtWindShldSfcTem "FrtWindShldSfcTem";
BA_ "CompuMethodName" SG_ 905 ISolarStrngLSideV "SolarStrngLSideV";
BA_ "ISignalName" SG_ 905 ISolarStrngLSideV "ISolarStrngLSideV";
BA_ "LongName" SG_ 905 ISolarStrngLSideV "Solar Strength Left Side Valid";
BA_ "SysSignalName" SG_ 905 ISolarStrngLSideV "SolarStrngLSideV";
BA_ "CompuMethodName" SG_ 905 ISolarStrngRSideV "SolarStrngRSideV";
BA_ "ISignalName" SG_ 905 ISolarStrngRSideV "ISolarStrngRSideV";
BA_ "LongName" SG_ 905 ISolarStrngRSideV "Solar Strength Right Side Valid";
BA_ "SysSignalName" SG_ 905 ISolarStrngRSideV "SolarStrngRSideV";
BA_ "CompuMethodName" SG_ 905 IDKBLERst "DKBLERst";
BA_ "ISignalName" SG_ 905 IDKBLERst "IDKBLERst";
BA_ "LongName" SG_ 905 IDKBLERst "Digital Key Ble Reset";
BA_ "SysSignalName" SG_ 905 IDKBLERst "DKBLERst";
BA_ "CompuMethodName" SG_ 905 IFrtWiperSpd "FrtWiperSpd";
BA_ "ISignalName" SG_ 905 IFrtWiperSpd "IFrtWiperSpd";
BA_ "LongName" SG_ 905 IFrtWiperSpd "Front Wiper Speed";
BA_ "SysSignalName" SG_ 905 IFrtWiperSpd "FrtWiperSpd";
BA_ "CompuMethodName" SG_ 783 ILHZCUeFs12Crnt "LHZCUeFs12Crnt";
BA_ "ISignalName" SG_ 783 ILHZCUeFs12Crnt "ILHZCUeFs12Crnt";
BA_ "LongName" SG_ 783 ILHZCUeFs12Crnt "LHZCU eFuse12 Current";
BA_ "SysSignalName" SG_ 783 ILHZCUeFs12Crnt "LHZCUeFs12Crnt";
BA_ "CompuMethodName" SG_ 783 ILHZCUeSw40Crnt "LHZCUeSw40Crnt";
BA_ "ISignalName" SG_ 783 ILHZCUeSw40Crnt "ILHZCUeSw40Crnt";
BA_ "LongName" SG_ 783 ILHZCUeSw40Crnt "LHZCU eSwitch40 Current";
BA_ "SysSignalName" SG_ 783 ILHZCUeSw40Crnt "LHZCUeSw40Crnt";
BA_ "CompuMethodName" SG_ 783 IWlcmReq "WlcmReq";
BA_ "ISignalName" SG_ 783 IWlcmReq "IWlcmReq";
BA_ "LongName" SG_ 783 IWlcmReq "Welcome Request";
BA_ "SysSignalName" SG_ 783 IWlcmReq "WlcmReq";
BA_ "CompuMethodName" SG_ 783 IFllwMeReq "FllwMeReq";
BA_ "ISignalName" SG_ 783 IFllwMeReq "IFllwMeReq";
BA_ "LongName" SG_ 783 IFllwMeReq "Follow ME Home Request";
BA_ "SysSignalName" SG_ 783 IFllwMeReq "FllwMeReq";
BA_ "CompuMethodName" SG_ 783 ILHZCUInptVol "LHZCUInptVol";
BA_ "ISignalName" SG_ 783 ILHZCUInptVol "ILHZCUInptVol";
BA_ "LongName" SG_ 783 ILHZCUInptVol "LHZCU Input Voltage";
BA_ "SysSignalName" SG_ 783 ILHZCUInptVol "LHZCUInptVol";
BA_ "CompuMethodName" SG_ 783 ILHZCUeFs8Crnt "LHZCUeFs8Crnt";
BA_ "ISignalName" SG_ 783 ILHZCUeFs8Crnt "ILHZCUeFs8Crnt";
BA_ "LongName" SG_ 783 ILHZCUeFs8Crnt "LHZCU eFuse8 Current";
BA_ "SysSignalName" SG_ 783 ILHZCUeFs8Crnt "LHZCUeFs8Crnt";
BA_ "CompuMethodName" SG_ 783 ILHZCUeSw24Crnt "LHZCUeSw24Crnt";
BA_ "ISignalName" SG_ 783 ILHZCUeSw24Crnt "ILHZCUeSw24Crnt";
BA_ "LongName" SG_ 783 ILHZCUeSw24Crnt "LHZCU eSwitch24 Current";
BA_ "SysSignalName" SG_ 783 ILHZCUeSw24Crnt "LHZCUeSw24Crnt";
BA_ "CompuMethodName" SG_ 783 ILHZCUeSw17Crnt "LHZCUeSw17Crnt";
BA_ "ISignalName" SG_ 783 ILHZCUeSw17Crnt "ILHZCUeSw17Crnt";
BA_ "LongName" SG_ 783 ILHZCUeSw17Crnt "LHZCU eSwitch17 Current";
BA_ "SysSignalName" SG_ 783 ILHZCUeSw17Crnt "LHZCUeSw17Crnt";
BA_ "CompuMethodName" SG_ 783 IKickSnsrDetnEnb "KickSnsrDetnEnb";
BA_ "ISignalName" SG_ 783 IKickSnsrDetnEnb "IKickSnsrDetnEnb";
BA_ "LongName" SG_ 783 IKickSnsrDetnEnb "Kick Sensor Detect Enable CAN";
BA_ "SysSignalName" SG_ 783 IKickSnsrDetnEnb "KickSnsrDetnEnb";
BA_ "CompuMethodName" SG_ 783 ILHZCUeSw16Crnt "LHZCUeSw16Crnt";
BA_ "ISignalName" SG_ 783 ILHZCUeSw16Crnt "ILHZCUeSw16Crnt";
BA_ "LongName" SG_ 783 ILHZCUeSw16Crnt "LHZCU eSwitch16 Current";
BA_ "SysSignalName" SG_ 783 ILHZCUeSw16Crnt "LHZCUeSw16Crnt";
BA_ "CompuMethodName" SG_ 783 ILHZCUeSw15Crnt "LHZCUeSw15Crnt";
BA_ "ISignalName" SG_ 783 ILHZCUeSw15Crnt "ILHZCUeSw15Crnt";
BA_ "LongName" SG_ 783 ILHZCUeSw15Crnt "LHZCU eSwitch15 Current";
BA_ "SysSignalName" SG_ 783 ILHZCUeSw15Crnt "LHZCUeSw15Crnt";
BA_ "CompuMethodName" SG_ 783 ILHZCUeSw14Crnt "LHZCUeSw14Crnt";
BA_ "ISignalName" SG_ 783 ILHZCUeSw14Crnt "ILHZCUeSw14Crnt";
BA_ "LongName" SG_ 783 ILHZCUeSw14Crnt "LHZCU eSwitch14 Current";
BA_ "SysSignalName" SG_ 783 ILHZCUeSw14Crnt "LHZCUeSw14Crnt";
BA_ "CompuMethodName" SG_ 783 ILHZCUeSw13Crnt "LHZCUeSw13Crnt";
BA_ "ISignalName" SG_ 783 ILHZCUeSw13Crnt "ILHZCUeSw13Crnt";
BA_ "LongName" SG_ 783 ILHZCUeSw13Crnt "LHZCU eSwitch13 Current";
BA_ "SysSignalName" SG_ 783 ILHZCUeSw13Crnt "LHZCUeSw13Crnt";
BA_ "CompuMethodName" SG_ 783 ILHZCUeSw12Crnt "LHZCUeSw12Crnt";
BA_ "ISignalName" SG_ 783 ILHZCUeSw12Crnt "ILHZCUeSw12Crnt";
BA_ "LongName" SG_ 783 ILHZCUeSw12Crnt "LHZCU eSwitch12 Current";
BA_ "SysSignalName" SG_ 783 ILHZCUeSw12Crnt "LHZCUeSw12Crnt";
BA_ "CompuMethodName" SG_ 783 ILHZCUeSw26Crnt "LHZCUeSw26Crnt";
BA_ "ISignalName" SG_ 783 ILHZCUeSw26Crnt "ILHZCUeSw26Crnt";
BA_ "LongName" SG_ 783 ILHZCUeSw26Crnt "LHZCU eSwitch26 Current";
BA_ "SysSignalName" SG_ 783 ILHZCUeSw26Crnt "LHZCUeSw26Crnt";
BA_ "CompuMethodName" SG_ 783 ILHZCUeFs6Crnt "LHZCUeFs6Crnt";
BA_ "ISignalName" SG_ 783 ILHZCUeFs6Crnt "ILHZCUeFs6Crnt";
BA_ "LongName" SG_ 783 ILHZCUeFs6Crnt "LHZCU eFuse6 Current";
BA_ "SysSignalName" SG_ 783 ILHZCUeFs6Crnt "LHZCUeFs6Crnt";
BA_ "CompuMethodName" SG_ 783 IKickSnsrDfct "KickSnsrDfct";
BA_ "ISignalName" SG_ 783 IKickSnsrDfct "IKickSnsrDfct";
BA_ "LongName" SG_ 783 IKickSnsrDfct "Kick Sensor Defect Status CAN";
BA_ "SysSignalName" SG_ 783 IKickSnsrDfct "KickSnsrDfct";
BA_ "CompuMethodName" SG_ 783 IKickSnsrEleDfct "KickSnsrEleDfct";
BA_ "ISignalName" SG_ 783 IKickSnsrEleDfct "IKickSnsrEleDfct";
BA_ "LongName" SG_ 783 IKickSnsrEleDfct "Kick Sensor Electric Defect Status CAN";
BA_ "SysSignalName" SG_ 783 IKickSnsrEleDfct "KickSnsrEleDfct";
BA_ "CompuMethodName" SG_ 783 IKickSnsrPlayProtn "KickSnsrPlayProtn";
BA_ "ISignalName" SG_ 783 IKickSnsrPlayProtn "IKickSnsrPlayProtn";
BA_ "LongName" SG_ 783 IKickSnsrPlayProtn "Kick Sensor Play Protection Status CAN";
BA_ "SysSignalName" SG_ 783 IKickSnsrPlayProtn "KickSnsrPlayProtn";
BA_ "CompuMethodName" SG_ 783 ILHZCUeSw32Crnt "LHZCUeSw32Crnt";
BA_ "ISignalName" SG_ 783 ILHZCUeSw32Crnt "ILHZCUeSw32Crnt";
BA_ "LongName" SG_ 783 ILHZCUeSw32Crnt "LHZCU eSwitch32 Current";
BA_ "SysSignalName" SG_ 783 ILHZCUeSw32Crnt "LHZCUeSw32Crnt";
BA_ "CompuMethodName" SG_ 783 ILHZCUeFs4Crnt "LHZCUeFs4Crnt";
BA_ "ISignalName" SG_ 783 ILHZCUeFs4Crnt "ILHZCUeFs4Crnt";
BA_ "LongName" SG_ 783 ILHZCUeFs4Crnt "LHZCU eFuse4 Current";
BA_ "SysSignalName" SG_ 783 ILHZCUeFs4Crnt "LHZCUeFs4Crnt";
BA_ "CompuMethodName" SG_ 783 ILHZCUeSw27Crnt "LHZCUeSw27Crnt";
BA_ "ISignalName" SG_ 783 ILHZCUeSw27Crnt "ILHZCUeSw27Crnt";
BA_ "LongName" SG_ 783 ILHZCUeSw27Crnt "LHZCU eSwitch27 Current";
BA_ "SysSignalName" SG_ 783 ILHZCUeSw27Crnt "LHZCUeSw27Crnt";
BA_ "CompuMethodName" SG_ 783 IKickSnsrSts "KickSnsrSts";
BA_ "ISignalName" SG_ 783 IKickSnsrSts "IKickSnsrSts";
BA_ "LongName" SG_ 783 IKickSnsrSts "Kick Sensor Active Status CAN";
BA_ "SysSignalName" SG_ 783 IKickSnsrSts "KickSnsrSts";
BA_ "CompuMethodName" SG_ 783 ILHZCUBkupInptVol "LHZCUBkupInptVol";
BA_ "ISignalName" SG_ 783 ILHZCUBkupInptVol "ILHZCUBkupInptVol";
BA_ "LongName" SG_ 783 ILHZCUBkupInptVol "LHZCU Backup Input Voltage";
BA_ "SysSignalName" SG_ 783 ILHZCUBkupInptVol "LHZCUBkupInptVol";
BA_ "CompuMethodName" SG_ 783 ILHZCUeSw1Crnt "LHZCUeSw1Crnt";
BA_ "ISignalName" SG_ 783 ILHZCUeSw1Crnt "ILHZCUeSw1Crnt";
BA_ "LongName" SG_ 783 ILHZCUeSw1Crnt "LHZCU eSwitch1 Current";
BA_ "SysSignalName" SG_ 783 ILHZCUeSw1Crnt "LHZCUeSw1Crnt";
BA_ "CompuMethodName" SG_ 783 ILHZCUeSw20Crnt "LHZCUeSw20Crnt";
BA_ "ISignalName" SG_ 783 ILHZCUeSw20Crnt "ILHZCUeSw20Crnt";
BA_ "LongName" SG_ 783 ILHZCUeSw20Crnt "LHZCU eSwitch20 Current";
BA_ "SysSignalName" SG_ 783 ILHZCUeSw20Crnt "LHZCUeSw20Crnt";
BA_ "CompuMethodName" SG_ 783 ILHZCUeSw3Crnt "LHZCUeSw3Crnt";
BA_ "ISignalName" SG_ 783 ILHZCUeSw3Crnt "ILHZCUeSw3Crnt";
BA_ "LongName" SG_ 783 ILHZCUeSw3Crnt "LHZCU eSwitch3 Current";
BA_ "SysSignalName" SG_ 783 ILHZCUeSw3Crnt "LHZCUeSw3Crnt";
BA_ "CompuMethodName" SG_ 783 ILHZCUeSw29Crnt "LHZCUeSw29Crnt";
BA_ "ISignalName" SG_ 783 ILHZCUeSw29Crnt "ILHZCUeSw29Crnt";
BA_ "LongName" SG_ 783 ILHZCUeSw29Crnt "LHZCU eSwitch29 Current";
BA_ "SysSignalName" SG_ 783 ILHZCUeSw29Crnt "LHZCUeSw29Crnt";
BA_ "CompuMethodName" SG_ 783 ILHZCUeSw36Crnt "LHZCUeSw36Crnt";
BA_ "ISignalName" SG_ 783 ILHZCUeSw36Crnt "ILHZCUeSw36Crnt";
BA_ "LongName" SG_ 783 ILHZCUeSw36Crnt "LHZCU eSwitch36 Current";
BA_ "SysSignalName" SG_ 783 ILHZCUeSw36Crnt "LHZCUeSw36Crnt";
BA_ "CompuMethodName" SG_ 783 ILHZCUeFs13Crnt "LHZCUeFs13Crnt";
BA_ "ISignalName" SG_ 783 ILHZCUeFs13Crnt "ILHZCUeFs13Crnt";
BA_ "LongName" SG_ 783 ILHZCUeFs13Crnt "LHZCU eFuse13 Current";
BA_ "SysSignalName" SG_ 783 ILHZCUeFs13Crnt "LHZCUeFs13Crnt";
BA_ "CompuMethodName" SG_ 783 ILHZCUeSw30Crnt "LHZCUeSw30Crnt";
BA_ "ISignalName" SG_ 783 ILHZCUeSw30Crnt "ILHZCUeSw30Crnt";
BA_ "LongName" SG_ 783 ILHZCUeSw30Crnt "LHZCU eSwitch30 Current";
BA_ "SysSignalName" SG_ 783 ILHZCUeSw30Crnt "LHZCUeSw30Crnt";
BA_ "CompuMethodName" SG_ 783 ILHZCUeSw31Crnt "LHZCUeSw31Crnt";
BA_ "ISignalName" SG_ 783 ILHZCUeSw31Crnt "ILHZCUeSw31Crnt";
BA_ "LongName" SG_ 783 ILHZCUeSw31Crnt "LHZCU eSwitch31 Current";
BA_ "SysSignalName" SG_ 783 ILHZCUeSw31Crnt "LHZCUeSw31Crnt";
BA_ "CompuMethodName" SG_ 783 IFrwlLghtReq_LHZCU "FrwlLghtReq_LHZCU";
BA_ "ISignalName" SG_ 783 IFrwlLghtReq_LHZCU "IFrwlLghtReq_LHZCU";
BA_ "LongName" SG_ 783 IFrwlLghtReq_LHZCU "Farewell Light Request";
BA_ "SysSignalName" SG_ 783 IFrwlLghtReq_LHZCU "FrwlLghtReq_LHZCU";
BA_ "CompuMethodName" SG_ 783 ILHZCUeSw43Crnt "LHZCUeSw43Crnt";
BA_ "ISignalName" SG_ 783 ILHZCUeSw43Crnt "ILHZCUeSw43Crnt";
BA_ "LongName" SG_ 783 ILHZCUeSw43Crnt "LHZCU eSwitch43 Current";
BA_ "SysSignalName" SG_ 783 ILHZCUeSw43Crnt "LHZCUeSw43Crnt";
BA_ "CompuMethodName" SG_ 783 ILHZCUAddtnInptVol "LHZCUAddtnInptVol";
BA_ "ISignalName" SG_ 783 ILHZCUAddtnInptVol "ILHZCUAddtnInptVol";
BA_ "LongName" SG_ 783 ILHZCUAddtnInptVol "LHZCU Additional Input Voltage";
BA_ "SysSignalName" SG_ 783 ILHZCUAddtnInptVol "LHZCUAddtnInptVol";
BA_ "CompuMethodName" SG_ 783 ILHZCUeSw44Crnt "LHZCUeSw44Crnt";
BA_ "ISignalName" SG_ 783 ILHZCUeSw44Crnt "ILHZCUeSw44Crnt";
BA_ "LongName" SG_ 783 ILHZCUeSw44Crnt "LHZCU eSwitch44 Current";
BA_ "SysSignalName" SG_ 783 ILHZCUeSw44Crnt "LHZCUeSw44Crnt";
BA_ "CompuMethodName" SG_ 783 ILHZCUeSw45Crnt "LHZCUeSw45Crnt";
BA_ "ISignalName" SG_ 783 ILHZCUeSw45Crnt "ILHZCUeSw45Crnt";
BA_ "LongName" SG_ 783 ILHZCUeSw45Crnt "LHZCU eSwitch45 Current";
BA_ "SysSignalName" SG_ 783 ILHZCUeSw45Crnt "LHZCUeSw45Crnt";
BA_ "CompuMethodName" SG_ 783 ILHZCUeSw46Crnt "LHZCUeSw46Crnt";
BA_ "ISignalName" SG_ 783 ILHZCUeSw46Crnt "ILHZCUeSw46Crnt";
BA_ "LongName" SG_ 783 ILHZCUeSw46Crnt "LHZCU eSwitch46 Current";
BA_ "SysSignalName" SG_ 783 ILHZCUeSw46Crnt "LHZCUeSw46Crnt";
BA_ "CompuMethodName" SG_ 783 ILHZCUeSw47Crnt "LHZCUeSw47Crnt";
BA_ "ISignalName" SG_ 783 ILHZCUeSw47Crnt "ILHZCUeSw47Crnt";
BA_ "LongName" SG_ 783 ILHZCUeSw47Crnt "LHZCU eSwitch47 Current";
BA_ "SysSignalName" SG_ 783 ILHZCUeSw47Crnt "LHZCUeSw47Crnt";
BA_ "CompuMethodName" SG_ 783 IWlcmLghtReq_LHZCU "WlcmLghtReq_LHZCU";
BA_ "ISignalName" SG_ 783 IWlcmLghtReq_LHZCU "IWlcmLghtReq_LHZCU";
BA_ "LongName" SG_ 783 IWlcmLghtReq_LHZCU "Welcome Light Request";
BA_ "SysSignalName" SG_ 783 IWlcmLghtReq_LHZCU "WlcmLghtReq_LHZCU";
BA_ "CompuMethodName" SG_ 783 IFLDoorOpenSts "FLDoorOpenSts";
BA_ "ISignalName" SG_ 783 IFLDoorOpenSts "IFLDoorOpenSts";
BA_ "LongName" SG_ 783 IFLDoorOpenSts "Front Left Door Open Status";
BA_ "SysSignalName" SG_ 783 IFLDoorOpenSts "FLDoorOpenSts";
BA_ "CompuMethodName" SG_ 783 IHUDLghtSnsrHdwrFltPrst "HUDLghtSnsrHdwrFltPrst";
BA_ "ISignalName" SG_ 783 IHUDLghtSnsrHdwrFltPrst "IHUDLghtSnsrHdwrFltPrst";
BA_ "LongName" SG_ 783 IHUDLghtSnsrHdwrFltPrst "HUD Light Sensor Hardware Fault Present";
BA_ "SysSignalName" SG_ 783 IHUDLghtSnsrHdwrFltPrst "HUDLghtSnsrHdwrFltPrst";
BA_ "CompuMethodName" SG_ 783 IHUDFwdLkngAmbtLghtLvl "HUDFwdLkngAmbtLghtLvl";
BA_ "ISignalName" SG_ 783 IHUDFwdLkngAmbtLghtLvl "IHUDFwdLkngAmbtLghtLvl";
BA_ "LongName" SG_ 783 IHUDFwdLkngAmbtLghtLvl "HUD Forward Light Looking  Ambient light  Level";
BA_ "SysSignalName" SG_ 783 IHUDFwdLkngAmbtLghtLvl "HUDFwdLkngAmbtLghtLvl";
BA_ "CompuMethodName" SG_ 783 IFollowMeHomeReq_LHZCU "FollowMeHomeReq_LHZCU";
BA_ "ISignalName" SG_ 783 IFollowMeHomeReq_LHZCU "IFollowMeHomeReq_LHZCU";
BA_ "LongName" SG_ 783 IFollowMeHomeReq_LHZCU "Follow Me Home Request";
BA_ "SysSignalName" SG_ 783 IFollowMeHomeReq_LHZCU "FollowMeHomeReq_LHZCU";
BA_ "CompuMethodName" SG_ 783 IBklghtReq "BklghtReq";
BA_ "ISignalName" SG_ 783 IBklghtReq "IBklghtReq";
BA_ "LongName" SG_ 783 IBklghtReq "BackLight Request";
BA_ "SysSignalName" SG_ 783 IBklghtReq "BklghtReq";
BA_ "CompuMethodName" SG_ 783 IHUDRLSAmbtLghtLvl "HUDRLSAmbtLghtLvl";
BA_ "ISignalName" SG_ 783 IHUDRLSAmbtLghtLvl "IHUDRLSAmbtLghtLvl";
BA_ "LongName" SG_ 783 IHUDRLSAmbtLghtLvl "HUD Rain Light sensor Ambient Light Level";
BA_ "SysSignalName" SG_ 783 IHUDRLSAmbtLghtLvl "HUDRLSAmbtLghtLvl";
BA_ "CompuMethodName" SG_ 783 ILHZCUeFs15Crnt "LHZCUeFs15Crnt";
BA_ "ISignalName" SG_ 783 ILHZCUeFs15Crnt "ILHZCUeFs15Crnt";
BA_ "LongName" SG_ 783 ILHZCUeFs15Crnt "LHZCU eFuse15 Current";
BA_ "SysSignalName" SG_ 783 ILHZCUeFs15Crnt "LHZCUeFs15Crnt";
BA_ "CompuMethodName" SG_ 783 IHmdtySnsrHdwrFltPrst "HmdtySnsrHdwrFltPrst";
BA_ "ISignalName" SG_ 783 IHmdtySnsrHdwrFltPrst "IHmdtySnsrHdwrFltPrst";
BA_ "LongName" SG_ 783 IHmdtySnsrHdwrFltPrst "Humidity Sensor Hardware Fault Present";
BA_ "SysSignalName" SG_ 783 IHmdtySnsrHdwrFltPrst "HmdtySnsrHdwrFltPrst";
BA_ "CompuMethodName" SG_ 783 IFrtPsngDoorOpenSts_LHZCU "FrtPsngDoorOpenSts_LHZCU";
BA_ "ISignalName" SG_ 783 IFrtPsngDoorOpenSts_LHZCU "IFrtPsngDoorOpenSts_LHZCU";
BA_ "LongName" SG_ 783 IFrtPsngDoorOpenSts_LHZCU "Front Passenger Door Open Status_LHZCU";
BA_ "SysSignalName" SG_ 783 IFrtPsngDoorOpenSts_LHZCU "FrtPsngDoorOpenSts_LHZCU";
BA_ "CompuMethodName" SG_ 783 ILHZCUeFs17Crnt "LHZCUeFs17Crnt";
BA_ "ISignalName" SG_ 783 ILHZCUeFs17Crnt "ILHZCUeFs17Crnt";
BA_ "LongName" SG_ 783 ILHZCUeFs17Crnt "LHZCU eFuse17 Current";
BA_ "SysSignalName" SG_ 783 ILHZCUeFs17Crnt "LHZCUeFs17Crnt";
BA_ "CompuMethodName" SG_ 896 IWndsrnHmdty "WndsrnHmdty";
BA_ "ISignalName" SG_ 896 IWndsrnHmdty "IWndsrnHmdty";
BA_ "LongName" SG_ 896 IWndsrnHmdty "Windscreen Humidity";
BA_ "SysSignalName" SG_ 896 IWndsrnHmdty "WndsrnHmdty";
BA_ "CompuMethodName" SG_ 896 IFrtWiperSwSts "FrtWiperSwSts";
BA_ "ISignalName" SG_ 896 IFrtWiperSwSts "IFrtWiperSwSts";
BA_ "LongName" SG_ 896 IFrtWiperSwSts "Front Wiper Switch Status";
BA_ "SysSignalName" SG_ 896 IFrtWiperSwSts "FrtWiperSwSts";
BA_ "CompuMethodName" SG_ 896 IFrtWshrPumpA "FrtWshrPumpA";
BA_ "ISignalName" SG_ 896 IFrtWshrPumpA "IFrtWshrPumpA";
BA_ "LongName" SG_ 896 IFrtWshrPumpA "Front Washer Pump Active";
BA_ "SysSignalName" SG_ 896 IFrtWshrPumpA "FrtWshrPumpA";
BA_ "CompuMethodName" SG_ 896 IFrtWiperOpReq "FrtWiperOpReq";
BA_ "ISignalName" SG_ 896 IFrtWiperOpReq "IFrtWiperOpReq";
BA_ "LongName" SG_ 896 IFrtWiperOpReq "Front Wiper Operation Request";
BA_ "SysSignalName" SG_ 896 IFrtWiperOpReq "FrtWiperOpReq";
BA_ "CompuMethodName" SG_ 299 ILHZCU_20ms_Group03_CRC "LHZCU_20ms_Group03_CRC";
BA_ "ISignalName" SG_ 299 ILHZCU_20ms_Group03_CRC "ILHZCU_20ms_Group03_CRC";
BA_ "SysSignalName" SG_ 299 ILHZCU_20ms_Group03_CRC "LHZCU_20ms_Group03_CRC";
BA_ "CompuMethodName" SG_ 299 ILHZCU_20ms_Group03_RC "LHZCU_20ms_Group03_RC";
BA_ "ISignalName" SG_ 299 ILHZCU_20ms_Group03_RC "ILHZCU_20ms_Group03_RC";
BA_ "SysSignalName" SG_ 299 ILHZCU_20ms_Group03_RC "LHZCU_20ms_Group03_RC";
BA_ "CompuMethodName" SG_ 299 ILHZCU_20ms_Group03_Reserved1 "LHZCU_20ms_Group03_Reserved1";
BA_ "GenSigStartValue" SG_ 299 ILHZCU_20ms_Group03_Reserved1 15;
BA_ "ISignalName" SG_ 299 ILHZCU_20ms_Group03_Reserved1 "ILHZCU_20ms_Group03_Reserved1";
BA_ "SysSignalName" SG_ 299 ILHZCU_20ms_Group03_Reserved1 "LHZCU_20ms_Group03_Reserved1";
BA_ "CompuMethodName" SG_ 299 ILHZCU_20ms_Group03_Reserved2 "LHZCU_20ms_Group03_Reserved2";
BA_ "GenSigStartValue" SG_ 299 ILHZCU_20ms_Group03_Reserved2 255;
BA_ "ISignalName" SG_ 299 ILHZCU_20ms_Group03_Reserved2 "ILHZCU_20ms_Group03_Reserved2";
BA_ "SysSignalName" SG_ 299 ILHZCU_20ms_Group03_Reserved2 "LHZCU_20ms_Group03_Reserved2";
BA_ "CompuMethodName" SG_ 299 ILHZCU_20ms_Group03_Reserved3 "LHZCU_20ms_Group03_Reserved3";
BA_ "GenSigStartValue" SG_ 299 ILHZCU_20ms_Group03_Reserved3 255;
BA_ "ISignalName" SG_ 299 ILHZCU_20ms_Group03_Reserved3 "ILHZCU_20ms_Group03_Reserved3";
BA_ "SysSignalName" SG_ 299 ILHZCU_20ms_Group03_Reserved3 "LHZCU_20ms_Group03_Reserved3";
BA_ "CompuMethodName" SG_ 299 ILHZCU_20ms_Group03_Reserved4 "LHZCU_20ms_Group03_Reserved4";
BA_ "GenSigStartValue" SG_ 299 ILHZCU_20ms_Group03_Reserved4 255;
BA_ "ISignalName" SG_ 299 ILHZCU_20ms_Group03_Reserved4 "ILHZCU_20ms_Group03_Reserved4";
BA_ "SysSignalName" SG_ 299 ILHZCU_20ms_Group03_Reserved4 "LHZCU_20ms_Group03_Reserved4";
BA_ "CompuMethodName" SG_ 299 ILHZCU_20ms_Group03_Reserved5 "LHZCU_20ms_Group03_Reserved5";
BA_ "GenSigStartValue" SG_ 299 ILHZCU_20ms_Group03_Reserved5 255;
BA_ "ISignalName" SG_ 299 ILHZCU_20ms_Group03_Reserved5 "ILHZCU_20ms_Group03_Reserved5";
BA_ "SysSignalName" SG_ 299 ILHZCU_20ms_Group03_Reserved5 "LHZCU_20ms_Group03_Reserved5";
BA_ "CompuMethodName" SG_ 299 IRevsLghtCtrl "RevsLghtCtrl";
BA_ "ISignalName" SG_ 299 IRevsLghtCtrl "IRevsLghtCtrl";
BA_ "LongName" SG_ 299 IRevsLghtCtrl "Reverse Light Control";
BA_ "SysSignalName" SG_ 299 IRevsLghtCtrl "RevsLghtCtrl";
BA_ "CompuMethodName" SG_ 299 ILHZCU_20ms_Group03_Reserved6 "LHZCU_20ms_Group03_Reserved6";
BA_ "GenSigStartValue" SG_ 299 ILHZCU_20ms_Group03_Reserved6 127;
BA_ "ISignalName" SG_ 299 ILHZCU_20ms_Group03_Reserved6 "ILHZCU_20ms_Group03_Reserved6";
BA_ "SysSignalName" SG_ 299 ILHZCU_20ms_Group03_Reserved6 "LHZCU_20ms_Group03_Reserved6";
BA_ "CompuMethodName" SG_ 299 ILHZCU_20ms_Group03_Reserved11 "LHZCU_20ms_Group03_Reserved11";
BA_ "GenSigStartValue" SG_ 299 ILHZCU_20ms_Group03_Reserved11 3;
BA_ "ISignalName" SG_ 299 ILHZCU_20ms_Group03_Reserved11 "ILHZCU_20ms_Group03_Reserved11";
BA_ "SysSignalName" SG_ 299 ILHZCU_20ms_Group03_Reserved11 "LHZCU_20ms_Group03_Reserved11";
BA_ "CompuMethodName" SG_ 299 IRRDircnLghtCtrl "RRDircnLghtCtrl";
BA_ "ISignalName" SG_ 299 IRRDircnLghtCtrl "IRRDircnLghtCtrl";
BA_ "LongName" SG_ 299 IRRDircnLghtCtrl "Right_Rear_Direction_Light_Control";
BA_ "SysSignalName" SG_ 299 IRRDircnLghtCtrl "RRDircnLghtCtrl";
BA_ "CompuMethodName" SG_ 299 IRLDircnLghtCtrl "RLDircnLghtCtrl";
BA_ "ISignalName" SG_ 299 IRLDircnLghtCtrl "IRLDircnLghtCtrl";
BA_ "LongName" SG_ 299 IRLDircnLghtCtrl "Left_Rear_Direction_Light_Control";
BA_ "SysSignalName" SG_ 299 IRLDircnLghtCtrl "RLDircnLghtCtrl";
BA_ "CompuMethodName" SG_ 299 IFRDircnLghtCtrl "FRDircnLghtCtrl";
BA_ "ISignalName" SG_ 299 IFRDircnLghtCtrl "IFRDircnLghtCtrl";
BA_ "LongName" SG_ 299 IFRDircnLghtCtrl "Right_Front_Direction_Light_Control";
BA_ "SysSignalName" SG_ 299 IFRDircnLghtCtrl "FRDircnLghtCtrl";
BA_ "CompuMethodName" SG_ 299 IFLDircnLghtCtrl "FLDircnLghtCtrl";
BA_ "ISignalName" SG_ 299 IFLDircnLghtCtrl "IFLDircnLghtCtrl";
BA_ "LongName" SG_ 299 IFLDircnLghtCtrl "Left_Front_Direction_Light_Control";
BA_ "SysSignalName" SG_ 299 IFLDircnLghtCtrl "FLDircnLghtCtrl";
BA_ "CompuMethodName" SG_ 299 IBrkLghtCtrl "BrkLghtCtrl";
BA_ "ISignalName" SG_ 299 IBrkLghtCtrl "IBrkLghtCtrl";
BA_ "LongName" SG_ 299 IBrkLghtCtrl "Brake_Light_Control";
BA_ "SysSignalName" SG_ 299 IBrkLghtCtrl "BrkLghtCtrl";
BA_ "CompuMethodName" SG_ 299 IHzrdLghtSwReq "HzrdLghtSwReq";
BA_ "ISignalName" SG_ 299 IHzrdLghtSwReq "IHzrdLghtSwReq";
BA_ "LongName" SG_ 299 IHzrdLghtSwReq "Hazard Light Switch Request";
BA_ "SysSignalName" SG_ 299 IHzrdLghtSwReq "HzrdLghtSwReq";
BA_ "CompuMethodName" SG_ 566 IFindCarFuncInfoDsp "FindCarFuncInfoDsp";
BA_ "ISignalName" SG_ 566 IFindCarFuncInfoDsp "IFindCarFuncInfoDsp";
BA_ "LongName" SG_ 566 IFindCarFuncInfoDsp "Find car function information Display";
BA_ "SysSignalName" SG_ 566 IFindCarFuncInfoDsp "FindCarFuncInfoDsp";
BA_ "CompuMethodName" SG_ 566 IDipdBeamLghtFltsts "DipdBeamLghtFltsts";
BA_ "ISignalName" SG_ 566 IDipdBeamLghtFltsts "IDipdBeamLghtFltsts";
BA_ "LongName" SG_ 566 IDipdBeamLghtFltsts "Dipped_beam_Light_Fault_Status";
BA_ "SysSignalName" SG_ 566 IDipdBeamLghtFltsts "DipdBeamLghtFltsts";
BA_ "CompuMethodName" SG_ 566 IFLDoorHndlPESwtActv "FLDoorHndlPESwtActv";
BA_ "ISignalName" SG_ 566 IFLDoorHndlPESwtActv "IFLDoorHndlPESwtActv";
BA_ "LongName" SG_ 566 IFLDoorHndlPESwtActv "Front Left Door Handle Passive Entry Switch Active";
BA_ "SysSignalName" SG_ 566 IFLDoorHndlPESwtActv "FLDoorHndlPESwtActv";
BA_ "CompuMethodName" SG_ 566 IFRDoorHndlPESwtActv "FRDoorHndlPESwtActv";
BA_ "GenSigStartValue" SG_ 566 IFRDoorHndlPESwtActv 1;
BA_ "ISignalName" SG_ 566 IFRDoorHndlPESwtActv "IFRDoorHndlPESwtActv";
BA_ "LongName" SG_ 566 IFRDoorHndlPESwtActv "Front Right Door Handle Passive Entry Switch Active";
BA_ "SysSignalName" SG_ 566 IFRDoorHndlPESwtActv "FRDoorHndlPESwtActv";
BA_ "CompuMethodName" SG_ 566 IMainBeamLghtMdSts "MainBeamLghtMdSts";
BA_ "ISignalName" SG_ 566 IMainBeamLghtMdSts "IMainBeamLghtMdSts";
BA_ "LongName" SG_ 566 IMainBeamLghtMdSts "Main_beam_Light_Mode_Status";
BA_ "SysSignalName" SG_ 566 IMainBeamLghtMdSts "MainBeamLghtMdSts";
BA_ "CompuMethodName" SG_ 566 IVehHzrdMdSts "VehHzrdMdSts";
BA_ "ISignalName" SG_ 566 IVehHzrdMdSts "IVehHzrdMdSts";
BA_ "LongName" SG_ 566 IVehHzrdMdSts "Vehicle_Hazard_Mode_Status";
BA_ "SysSignalName" SG_ 566 IVehHzrdMdSts "VehHzrdMdSts";
BA_ "CompuMethodName" SG_ 566 IHzrdLghtSwSts "HzrdLghtSwSts";
BA_ "ISignalName" SG_ 566 IHzrdLghtSwSts "IHzrdLghtSwSts";
BA_ "LongName" SG_ 566 IHzrdLghtSwSts "Hazard_Light_Switch_Status";
BA_ "SysSignalName" SG_ 566 IHzrdLghtSwSts "HzrdLghtSwSts";
BA_ "CompuMethodName" SG_ 566 IBrkLghtSwStsV "BrkLghtSwStsV";
BA_ "ISignalName" SG_ 566 IBrkLghtSwStsV "IBrkLghtSwStsV";
BA_ "LongName" SG_ 566 IBrkLghtSwStsV "Brake_Light_Switch _Status_Validty";
BA_ "SysSignalName" SG_ 566 IBrkLghtSwStsV "BrkLghtSwStsV";
BA_ "CompuMethodName" SG_ 566 IBrkLghtSwSts "BrkLghtSwSts";
BA_ "ISignalName" SG_ 566 IBrkLghtSwSts "IBrkLghtSwSts";
BA_ "LongName" SG_ 566 IBrkLghtSwSts "Brake Light Switch Status";
BA_ "SysSignalName" SG_ 566 IBrkLghtSwSts "BrkLghtSwSts";
BA_ "CompuMethodName" SG_ 566 IRrWiperReq "RrWiperReq";
BA_ "ISignalName" SG_ 566 IRrWiperReq "IRrWiperReq";
BA_ "LongName" SG_ 566 IRrWiperReq "Rear Wiper Request";
BA_ "SysSignalName" SG_ 566 IRrWiperReq "RrWiperReq";
BA_ "CompuMethodName" SG_ 566 IMainBeamLghtFltSts "MainBeamLghtFltSts";
BA_ "ISignalName" SG_ 566 IMainBeamLghtFltSts "IMainBeamLghtFltSts";
BA_ "LongName" SG_ 566 IMainBeamLghtFltSts "Main_beam_Light_Fault_Status";
BA_ "SysSignalName" SG_ 566 IMainBeamLghtFltSts "MainBeamLghtFltSts";
BA_ "CompuMethodName" SG_ 566 IMainBeamLghtSts "MainBeamLghtSts";
BA_ "ISignalName" SG_ 566 IMainBeamLghtSts "IMainBeamLghtSts";
BA_ "LongName" SG_ 566 IMainBeamLghtSts "Main_beam_Light_Status";
BA_ "SysSignalName" SG_ 566 IMainBeamLghtSts "MainBeamLghtSts";
BA_ "CompuMethodName" SG_ 566 IMainBeamLghtSwSts "MainBeamLghtSwSts";
BA_ "ISignalName" SG_ 566 IMainBeamLghtSwSts "IMainBeamLghtSwSts";
BA_ "LongName" SG_ 566 IMainBeamLghtSwSts "Main beam Light switch  Status";
BA_ "SysSignalName" SG_ 566 IMainBeamLghtSwSts "MainBeamLghtSwSts";
BA_ "CompuMethodName" SG_ 566 IDircnIndLghtSwSts "DircnIndLghtSwSts";
BA_ "ISignalName" SG_ 566 IDircnIndLghtSwSts "IDircnIndLghtSwSts";
BA_ "LongName" SG_ 566 IDircnIndLghtSwSts "Direction Indication Light Switch Status";
BA_ "SysSignalName" SG_ 566 IDircnIndLghtSwSts "DircnIndLghtSwSts";
BA_ "CompuMethodName" SG_ 566 ILdspcRlseSwtActv "LdspcRlseSwtActv";
BA_ "ISignalName" SG_ 566 ILdspcRlseSwtActv "ILdspcRlseSwtActv";
BA_ "LongName" SG_ 566 ILdspcRlseSwtActv "Loadspace Release Switch Active";
BA_ "SysSignalName" SG_ 566 ILdspcRlseSwtActv "LdspcRlseSwtActv";
BA_ "CompuMethodName" SG_ 566 IRRWinDrvrSwtSts "RRWinDrvrSwtSts";
BA_ "ISignalName" SG_ 566 IRRWinDrvrSwtSts "IRRWinDrvrSwtSts";
BA_ "LongName" SG_ 566 IRRWinDrvrSwtSts "Rear Right Window Driver Switch Status";
BA_ "SysSignalName" SG_ 566 IRRWinDrvrSwtSts "RRWinDrvrSwtSts";
BA_ "CompuMethodName" SG_ 566 ILckCtrlResp "LckCtrlResp";
BA_ "ISignalName" SG_ 566 ILckCtrlResp "ILckCtrlResp";
BA_ "LongName" SG_ 566 ILckCtrlResp "Lock Control Response";
BA_ "SysSignalName" SG_ 566 ILckCtrlResp "LckCtrlResp";
BA_ "CompuMethodName" SG_ 566 IRLWinDrvrSwtSts "RLWinDrvrSwtSts";
BA_ "ISignalName" SG_ 566 IRLWinDrvrSwtSts "IRLWinDrvrSwtSts";
BA_ "LongName" SG_ 566 IRLWinDrvrSwtSts "Rear Left Window Driver Switch Status";
BA_ "SysSignalName" SG_ 566 IRLWinDrvrSwtSts "RLWinDrvrSwtSts";
BA_ "CompuMethodName" SG_ 566 IFRWinDrvrSwtSts "FRWinDrvrSwtSts";
BA_ "ISignalName" SG_ 566 IFRWinDrvrSwtSts "IFRWinDrvrSwtSts";
BA_ "LongName" SG_ 566 IFRWinDrvrSwtSts "Front Right Window Driver Switch Status";
BA_ "SysSignalName" SG_ 566 IFRWinDrvrSwtSts "FRWinDrvrSwtSts";
BA_ "CompuMethodName" SG_ 566 IDipdBeamLghtSts "DipdBeamLghtSts";
BA_ "ISignalName" SG_ 566 IDipdBeamLghtSts "IDipdBeamLghtSts";
BA_ "LongName" SG_ 566 IDipdBeamLghtSts "Dipped_beam_Light_Status";
BA_ "SysSignalName" SG_ 566 IDipdBeamLghtSts "DipdBeamLghtSts";
BA_ "CompuMethodName" SG_ 566 IBrkPdlTrigd "BrkPdlTrigd";
BA_ "ISignalName" SG_ 566 IBrkPdlTrigd "IBrkPdlTrigd";
BA_ "LongName" SG_ 566 IBrkPdlTrigd "Brake Pedal Triggerd";
BA_ "SysSignalName" SG_ 566 IBrkPdlTrigd "BrkPdlTrigd";
BA_ "CompuMethodName" SG_ 566 IFLWinLclSwtSts "FLWinLclSwtSts";
BA_ "ISignalName" SG_ 566 IFLWinLclSwtSts "IFLWinLclSwtSts";
BA_ "LongName" SG_ 566 IFLWinLclSwtSts "Front Left Window Local Switch Status";
BA_ "SysSignalName" SG_ 566 IFLWinLclSwtSts "FLWinLclSwtSts";
BA_ "CompuMethodName" SG_ 566 IExtrLckActnIndcn "ExtrLckActnIndcn";
BA_ "ISignalName" SG_ 566 IExtrLckActnIndcn "IExtrLckActnIndcn";
BA_ "LongName" SG_ 566 IExtrLckActnIndcn "Exterior Lock Action Indication";
BA_ "SysSignalName" SG_ 566 IExtrLckActnIndcn "ExtrLckActnIndcn";
BA_ "CompuMethodName" SG_ 566 IAutoMainBeamLghtSts "AutoMainBeamLghtSts";
BA_ "ISignalName" SG_ 566 IAutoMainBeamLghtSts "IAutoMainBeamLghtSts";
BA_ "LongName" SG_ 566 IAutoMainBeamLghtSts "Auto_Main_Beam_Light_Status";
BA_ "SysSignalName" SG_ 566 IAutoMainBeamLghtSts "AutoMainBeamLghtSts";
BA_ "CompuMethodName" SG_ 566 IDrvrDetSnsrFltSts "DrvrDetSnsrFltSts";
BA_ "ISignalName" SG_ 566 IDrvrDetSnsrFltSts "IDrvrDetSnsrFltSts";
BA_ "LongName" SG_ 566 IDrvrDetSnsrFltSts "Driver Detected Sensor Fault Status";
BA_ "SysSignalName" SG_ 566 IDrvrDetSnsrFltSts "DrvrDetSnsrFltSts";
BA_ "CompuMethodName" SG_ 566 IDircnIndLghtMdSts "DircnIndLghtMdSts";
BA_ "ISignalName" SG_ 566 IDircnIndLghtMdSts "IDircnIndLghtMdSts";
BA_ "LongName" SG_ 566 IDircnIndLghtMdSts "Direction Indication Light Mode Status";
BA_ "SysSignalName" SG_ 566 IDircnIndLghtMdSts "DircnIndLghtMdSts";
BA_ "CompuMethodName" SG_ 653 ILOtsdMirHoztPos "LOtsdMirHoztPos";
BA_ "GenSigStartValue" SG_ 653 ILOtsdMirHoztPos 255;
BA_ "ISignalName" SG_ 653 ILOtsdMirHoztPos "ILOtsdMirHoztPos";
BA_ "LongName" SG_ 653 ILOtsdMirHoztPos "Left Outside Mirror Horizontal Position";
BA_ "SysSignalName" SG_ 653 ILOtsdMirHoztPos "LOtsdMirHoztPos";
BA_ "CompuMethodName" SG_ 653 IFwdLkngAmbtLghtLvl "FwdLkngAmbtLghtLvl";
BA_ "ISignalName" SG_ 653 IFwdLkngAmbtLghtLvl "IFwdLkngAmbtLghtLvl";
BA_ "LongName" SG_ 653 IFwdLkngAmbtLghtLvl "Forward Looking Ambient Light Level";
BA_ "SysSignalName" SG_ 653 IFwdLkngAmbtLghtLvl "FwdLkngAmbtLghtLvl";
BA_ "CompuMethodName" SG_ 653 IRLSAmbtLghtLvl "RLSAmbtLghtLvl";
BA_ "ISignalName" SG_ 653 IRLSAmbtLghtLvl "IRLSAmbtLghtLvl";
BA_ "LongName" SG_ 653 IRLSAmbtLghtLvl "Rain Light Sensor Ambient Light Level";
BA_ "SysSignalName" SG_ 653 IRLSAmbtLghtLvl "RLSAmbtLghtLvl";
BA_ "CompuMethodName" SG_ 653 IAutoLghtOnReq "AutoLghtOnReq";
BA_ "ISignalName" SG_ 653 IAutoLghtOnReq "IAutoLghtOnReq";
BA_ "LongName" SG_ 653 IAutoLghtOnReq "Auto_Light_On_Request";
BA_ "SysSignalName" SG_ 653 IAutoLghtOnReq "AutoLghtOnReq";
BA_ "CompuMethodName" SG_ 653 IExtrTrunkCtrlReq "ExtrTrunkCtrlReq";
BA_ "ISignalName" SG_ 653 IExtrTrunkCtrlReq "IExtrTrunkCtrlReq";
BA_ "LongName" SG_ 653 IExtrTrunkCtrlReq "External Trunk Control request";
BA_ "SysSignalName" SG_ 653 IExtrTrunkCtrlReq "ExtrTrunkCtrlReq";
BA_ "CompuMethodName" SG_ 653 IDoorLckCtrlReq "DoorLckCtrlReq";
BA_ "ISignalName" SG_ 653 IDoorLckCtrlReq "IDoorLckCtrlReq";
BA_ "LongName" SG_ 653 IDoorLckCtrlReq "Door Lock Control Request";
BA_ "SysSignalName" SG_ 653 IDoorLckCtrlReq "DoorLckCtrlReq";
BA_ "CompuMethodName" SG_ 653 ILghtSnsrHdwrFltPrst "LghtSnsrHdwrFltPrst";
BA_ "ISignalName" SG_ 653 ILghtSnsrHdwrFltPrst "ILghtSnsrHdwrFltPrst";
BA_ "LongName" SG_ 653 ILghtSnsrHdwrFltPrst "Light Sensor Hardware Fault Present";
BA_ "SysSignalName" SG_ 653 ILghtSnsrHdwrFltPrst "LghtSnsrHdwrFltPrst";
BA_ "CompuMethodName" SG_ 653 IExtrTrunkCtrlSrcReq "ExtrTrunkCtrlSrcReq";
BA_ "ISignalName" SG_ 653 IExtrTrunkCtrlSrcReq "IExtrTrunkCtrlSrcReq";
BA_ "LongName" SG_ 653 IExtrTrunkCtrlSrcReq "External Trunk Control request source";
BA_ "SysSignalName" SG_ 653 IExtrTrunkCtrlSrcReq "ExtrTrunkCtrlSrcReq";
BA_ "CompuMethodName" SG_ 653 ILghtSwPosSts "LghtSwPosSts";
BA_ "ISignalName" SG_ 653 ILghtSwPosSts "ILghtSwPosSts";
BA_ "LongName" SG_ 653 ILghtSwPosSts "Light Switch Position Status";
BA_ "SysSignalName" SG_ 653 ILghtSwPosSts "LghtSwPosSts";
BA_ "CompuMethodName" SG_ 653 ILOtsdMirVertPos "LOtsdMirVertPos";
BA_ "GenSigStartValue" SG_ 653 ILOtsdMirVertPos 255;
BA_ "ISignalName" SG_ 653 ILOtsdMirVertPos "ILOtsdMirVertPos";
BA_ "LongName" SG_ 653 ILOtsdMirVertPos "Left Outside Mirror Vertical Position";
BA_ "SysSignalName" SG_ 653 ILOtsdMirVertPos "LOtsdMirVertPos";
BA_ "CompuMethodName" SG_ 652 ILHZCU_50ms_Group06_CRC "LHZCU_50ms_Group06_CRC";
BA_ "ISignalName" SG_ 652 ILHZCU_50ms_Group06_CRC "ILHZCU_50ms_Group06_CRC";
BA_ "SysSignalName" SG_ 652 ILHZCU_50ms_Group06_CRC "LHZCU_50ms_Group06_CRC";
BA_ "CompuMethodName" SG_ 652 ILHZCU_50ms_Group06_RC "LHZCU_50ms_Group06_RC";
BA_ "ISignalName" SG_ 652 ILHZCU_50ms_Group06_RC "ILHZCU_50ms_Group06_RC";
BA_ "SysSignalName" SG_ 652 ILHZCU_50ms_Group06_RC "LHZCU_50ms_Group06_RC";
BA_ "CompuMethodName" SG_ 652 IDrvrDetSts "DrvrDetSts";
BA_ "ISignalName" SG_ 652 IDrvrDetSts "IDrvrDetSts";
BA_ "LongName" SG_ 652 IDrvrDetSts "Driver Detected Status";
BA_ "SysSignalName" SG_ 652 IDrvrDetSts "DrvrDetSts";
BA_ "CompuMethodName" SG_ 652 IRLDoorOpenSts "RLDoorOpenSts";
BA_ "ISignalName" SG_ 652 IRLDoorOpenSts "IRLDoorOpenSts";
BA_ "LongName" SG_ 652 IRLDoorOpenSts "Rear Left Door Open Status";
BA_ "SysSignalName" SG_ 652 IRLDoorOpenSts "RLDoorOpenSts";
BA_ "CompuMethodName" SG_ 652 ILHZCU_50ms_Group06_Reserved1 "LHZCU_50ms_Group06_Reserved1";
BA_ "GenSigStartValue" SG_ 652 ILHZCU_50ms_Group06_Reserved1 1;
BA_ "ISignalName" SG_ 652 ILHZCU_50ms_Group06_Reserved1 "ILHZCU_50ms_Group06_Reserved1";
BA_ "SysSignalName" SG_ 652 ILHZCU_50ms_Group06_Reserved1 "LHZCU_50ms_Group06_Reserved1";
BA_ "CompuMethodName" SG_ 652 IDrvrDoorOpenSts "DrvrDoorOpenSts";
BA_ "ISignalName" SG_ 652 IDrvrDoorOpenSts "IDrvrDoorOpenSts";
BA_ "LongName" SG_ 652 IDrvrDoorOpenSts "Driver Door Open Status";
BA_ "SysSignalName" SG_ 652 IDrvrDoorOpenSts "DrvrDoorOpenSts";
BA_ "CompuMethodName" SG_ 652 IBntOpenSts "BntOpenSts";
BA_ "ISignalName" SG_ 652 IBntOpenSts "IBntOpenSts";
BA_ "LongName" SG_ 652 IBntOpenSts "Bonnet_Open_Status";
BA_ "SysSignalName" SG_ 652 IBntOpenSts "BntOpenSts";
BA_ "CompuMethodName" SG_ 652 IVehLckSts "VehLckSts";
BA_ "GenSigStartValue" SG_ 652 IVehLckSts 7;
BA_ "ISignalName" SG_ 652 IVehLckSts "IVehLckSts";
BA_ "LongName" SG_ 652 IVehLckSts "Vehicle Lock Status";
BA_ "SysSignalName" SG_ 652 IVehLckSts "VehLckSts";
BA_ "CompuMethodName" SG_ 652 ILHZCU_50ms_Group06_Reserved2 "LHZCU_50ms_Group06_Reserved2";
BA_ "GenSigStartValue" SG_ 652 ILHZCU_50ms_Group06_Reserved2 255;
BA_ "ISignalName" SG_ 652 ILHZCU_50ms_Group06_Reserved2 "ILHZCU_50ms_Group06_Reserved2";
BA_ "SysSignalName" SG_ 652 ILHZCU_50ms_Group06_Reserved2 "LHZCU_50ms_Group06_Reserved2";
BA_ "CompuMethodName" SG_ 652 ILHZCU_50ms_Group06_Reserved3 "LHZCU_50ms_Group06_Reserved3";
BA_ "GenSigStartValue" SG_ 652 ILHZCU_50ms_Group06_Reserved3 255;
BA_ "ISignalName" SG_ 652 ILHZCU_50ms_Group06_Reserved3 "ILHZCU_50ms_Group06_Reserved3";
BA_ "SysSignalName" SG_ 652 ILHZCU_50ms_Group06_Reserved3 "LHZCU_50ms_Group06_Reserved3";
BA_ "CompuMethodName" SG_ 652 ILHZCU_50ms_Group06_Reserved4 "LHZCU_50ms_Group06_Reserved4";
BA_ "GenSigStartValue" SG_ 652 ILHZCU_50ms_Group06_Reserved4 255;
BA_ "ISignalName" SG_ 652 ILHZCU_50ms_Group06_Reserved4 "ILHZCU_50ms_Group06_Reserved4";
BA_ "SysSignalName" SG_ 652 ILHZCU_50ms_Group06_Reserved4 "LHZCU_50ms_Group06_Reserved4";
BA_ "CompuMethodName" SG_ 652 ILHZCU_50ms_Group06_Reserved5 "LHZCU_50ms_Group06_Reserved5";
BA_ "GenSigStartValue" SG_ 652 ILHZCU_50ms_Group06_Reserved5 255;
BA_ "ISignalName" SG_ 652 ILHZCU_50ms_Group06_Reserved5 "ILHZCU_50ms_Group06_Reserved5";
BA_ "SysSignalName" SG_ 652 ILHZCU_50ms_Group06_Reserved5 "LHZCU_50ms_Group06_Reserved5";
BA_ "CompuMethodName" SG_ 652 ILHZCU_50ms_Group06_Reserved6 "LHZCU_50ms_Group06_Reserved6";
BA_ "GenSigStartValue" SG_ 652 ILHZCU_50ms_Group06_Reserved6 255;
BA_ "ISignalName" SG_ 652 ILHZCU_50ms_Group06_Reserved6 "ILHZCU_50ms_Group06_Reserved6";
BA_ "SysSignalName" SG_ 652 ILHZCU_50ms_Group06_Reserved6 "LHZCU_50ms_Group06_Reserved6";
BA_ "CompuMethodName" SG_ 714 IAGSModestatus2 "AGSModestatus2";
BA_ "GenSigStartValue" SG_ 714 IAGSModestatus2 3;
BA_ "ISignalName" SG_ 714 IAGSModestatus2 "IAGSModestatus2";
BA_ "LongName" SG_ 714 IAGSModestatus2 "Aero Grille Shutter Mode Status 2";
BA_ "SysSignalName" SG_ 714 IAGSModestatus2 "AGSModestatus2";
BA_ "CompuMethodName" SG_ 714 IAGSModestatus1 "AGSModestatus1";
BA_ "GenSigStartValue" SG_ 714 IAGSModestatus1 3;
BA_ "ISignalName" SG_ 714 IAGSModestatus1 "IAGSModestatus1";
BA_ "LongName" SG_ 714 IAGSModestatus1 "Aero Grille Shutter Mode Status 1";
BA_ "SysSignalName" SG_ 714 IAGSModestatus1 "AGSModestatus1";
BA_ "CompuMethodName" SG_ 714 IAGS1FltRsn "AGS1FltRsn";
BA_ "ISignalName" SG_ 714 IAGS1FltRsn "IAGS1FltRsn";
BA_ "LongName" SG_ 714 IAGS1FltRsn "AGS1 Fault Reason";
BA_ "SysSignalName" SG_ 714 IAGS1FltRsn "AGS1FltRsn";
BA_ "CompuMethodName" SG_ 714 IAGS2FltRsn "AGS2FltRsn";
BA_ "ISignalName" SG_ 714 IAGS2FltRsn "IAGS2FltRsn";
BA_ "LongName" SG_ 714 IAGS2FltRsn "AGS2 Fault Reason";
BA_ "SysSignalName" SG_ 714 IAGS2FltRsn "AGS2FltRsn";
BA_ "CompuMethodName" SG_ 714 IAGSActualPosition1 "AGSActualPosition1";
BA_ "ISignalName" SG_ 714 IAGSActualPosition1 "IAGSActualPosition1";
BA_ "LongName" SG_ 714 IAGSActualPosition1 "Aero Grille Shutter Actual Position 1";
BA_ "SysSignalName" SG_ 714 IAGSActualPosition1 "AGSActualPosition1";
BA_ "CompuMethodName" SG_ 714 IAGSActualPosition2 "AGSActualPosition2";
BA_ "ISignalName" SG_ 714 IAGSActualPosition2 "IAGSActualPosition2";
BA_ "LongName" SG_ 714 IAGSActualPosition2 "Aero Grille Shutter Actual Position 2";
BA_ "SysSignalName" SG_ 714 IAGSActualPosition2 "AGSActualPosition2";
BA_ "CompuMethodName" SG_ 714 IEPTElecWtrPumpActuSpd "EPTElecWtrPumpActuSpd";
BA_ "GenSigStartValue" SG_ 714 IEPTElecWtrPumpActuSpd 255;
BA_ "ISignalName" SG_ 714 IEPTElecWtrPumpActuSpd "IEPTElecWtrPumpActuSpd";
BA_ "LongName" SG_ 714 IEPTElecWtrPumpActuSpd "Ept Electric Water Pump Actual Speed";
BA_ "SysSignalName" SG_ 714 IEPTElecWtrPumpActuSpd "EPTElecWtrPumpActuSpd";
BA_ "CompuMethodName" SG_ 714 IESSElecWtrPumpActuSpd "ESSElecWtrPumpActuSpd";
BA_ "GenSigStartValue" SG_ 714 IESSElecWtrPumpActuSpd 255;
BA_ "ISignalName" SG_ 714 IESSElecWtrPumpActuSpd "IESSElecWtrPumpActuSpd";
BA_ "LongName" SG_ 714 IESSElecWtrPumpActuSpd "Ess Electric Water Pump Actual Speed";
BA_ "SysSignalName" SG_ 714 IESSElecWtrPumpActuSpd "ESSElecWtrPumpActuSpd";
BA_ "CompuMethodName" SG_ 714 IEDUClntTem "EDUClntTem";
BA_ "ISignalName" SG_ 714 IEDUClntTem "IEDUClntTem";
BA_ "LongName" SG_ 714 IEDUClntTem "Ecm Power Electric Unit Inlet Coolant Temperature";
BA_ "SysSignalName" SG_ 714 IEDUClntTem "EDUClntTem";
BA_ "CompuMethodName" SG_ 714 IAGSTorqueResponse2 "AGSTorqueResponse2";
BA_ "GenSigStartValue" SG_ 714 IAGSTorqueResponse2 3;
BA_ "ISignalName" SG_ 714 IAGSTorqueResponse2 "IAGSTorqueResponse2";
BA_ "LongName" SG_ 714 IAGSTorqueResponse2 "Aero Grille Shutter Torque Response 2";
BA_ "SysSignalName" SG_ 714 IAGSTorqueResponse2 "AGSTorqueResponse2";
BA_ "CompuMethodName" SG_ 714 IAGSTorqueResponse1 "AGSTorqueResponse1";
BA_ "GenSigStartValue" SG_ 714 IAGSTorqueResponse1 3;
BA_ "ISignalName" SG_ 714 IAGSTorqueResponse1 "IAGSTorqueResponse1";
BA_ "LongName" SG_ 714 IAGSTorqueResponse1 "Aero Grille Shutter Torque Response 1";
BA_ "SysSignalName" SG_ 714 IAGSTorqueResponse1 "AGSTorqueResponse1";
BA_ "CompuMethodName" SG_ 714 IAGSSelflearnStatus2 "AGSSelflearnStatus2";
BA_ "GenSigStartValue" SG_ 714 IAGSSelflearnStatus2 3;
BA_ "ISignalName" SG_ 714 IAGSSelflearnStatus2 "IAGSSelflearnStatus2";
BA_ "LongName" SG_ 714 IAGSSelflearnStatus2 "Aero Grille Shutter Self-learn Status 2";
BA_ "SysSignalName" SG_ 714 IAGSSelflearnStatus2 "AGSSelflearnStatus2";
BA_ "CompuMethodName" SG_ 714 IAGSSelflearnStatus1 "AGSSelflearnStatus1";
BA_ "GenSigStartValue" SG_ 714 IAGSSelflearnStatus1 3;
BA_ "ISignalName" SG_ 714 IAGSSelflearnStatus1 "IAGSSelflearnStatus1";
BA_ "LongName" SG_ 714 IAGSSelflearnStatus1 "Aero Grille Shutter Self-learn Status 1";
BA_ "SysSignalName" SG_ 714 IAGSSelflearnStatus1 "AGSSelflearnStatus1";
BA_ "CompuMethodName" SG_ 714 IEDUClntTemV "EDUClntTemV";
BA_ "ISignalName" SG_ 714 IEDUClntTemV "IEDUClntTemV";
BA_ "LongName" SG_ 714 IEDUClntTemV "Ecm Power Electric Unit Inlet Coolant Temperature Validity";
BA_ "SysSignalName" SG_ 714 IEDUClntTemV "EDUClntTemV";
BA_ "CompuMethodName" SG_ 714 IAGSMoveStatus2 "AGSMoveStatus2";
BA_ "ISignalName" SG_ 714 IAGSMoveStatus2 "IAGSMoveStatus2";
BA_ "LongName" SG_ 714 IAGSMoveStatus2 "Aero Grille Shutter Move Status 2";
BA_ "SysSignalName" SG_ 714 IAGSMoveStatus2 "AGSMoveStatus2";
BA_ "CompuMethodName" SG_ 714 IAGSMoveStatus1 "AGSMoveStatus1";
BA_ "ISignalName" SG_ 714 IAGSMoveStatus1 "IAGSMoveStatus1";
BA_ "LongName" SG_ 714 IAGSMoveStatus1 "Aero Grille Shutter Move Status 1";
BA_ "SysSignalName" SG_ 714 IAGSMoveStatus1 "AGSMoveStatus1";
BA_ "CompuMethodName" SG_ 1228 IRHRDA_NM_BSMtoRMS_BKPCANFD "RHRDA_NM_BSMtoRMS_BKPCANFD";
BA_ "ISignalName" SG_ 1228 IRHRDA_NM_BSMtoRMS_BKPCANFD "IRHRDA_NM_BSMtoRMS_BKPCANFD";
BA_ "LongName" SG_ 1228 IRHRDA_NM_BSMtoRMS_BKPCANFD "RHRDA_NM_BSMtoRMS_BKPCANFD";
BA_ "SysSignalName" SG_ 1228 IRHRDA_NM_BSMtoRMS_BKPCANFD "RHRDA_NM_BSMtoRMS_BKPCANFD";
BA_ "CompuMethodName" SG_ 1228 IRHRDA_NM_PBSMtoRMS_BKPCANFD "RHRDA_NM_PBSMtoRMS_BKPCANFD";
BA_ "ISignalName" SG_ 1228 IRHRDA_NM_PBSMtoRMS_BKPCANFD "IRHRDA_NM_PBSMtoRMS_BKPCANFD";
BA_ "LongName" SG_ 1228 IRHRDA_NM_PBSMtoRMS_BKPCANFD "RHRDA_NM_PBSMtoRMS_BKPCANFD";
BA_ "SysSignalName" SG_ 1228 IRHRDA_NM_PBSMtoRMS_BKPCANFD "RHRDA_NM_PBSMtoRMS_BKPCANFD";
BA_ "CompuMethodName" SG_ 1228 IRHRDA_NM_RMStoNOS_BKPCANFD "RHRDA_NM_RMStoNOS_BKPCANFD";
BA_ "ISignalName" SG_ 1228 IRHRDA_NM_RMStoNOS_BKPCANFD "IRHRDA_NM_RMStoNOS_BKPCANFD";
BA_ "LongName" SG_ 1228 IRHRDA_NM_RMStoNOS_BKPCANFD "RHRDA_NM_RMStoNOS_BKPCANFD";
BA_ "SysSignalName" SG_ 1228 IRHRDA_NM_RMStoNOS_BKPCANFD "RHRDA_NM_RMStoNOS_BKPCANFD";
BA_ "CompuMethodName" SG_ 1228 IRHRDA_NM_RSStoNOS_BKPCANFD "RHRDA_NM_RSStoNOS_BKPCANFD";
BA_ "ISignalName" SG_ 1228 IRHRDA_NM_RSStoNOS_BKPCANFD "IRHRDA_NM_RSStoNOS_BKPCANFD";
BA_ "LongName" SG_ 1228 IRHRDA_NM_RSStoNOS_BKPCANFD "RHRDA_NM_RSStoNOS_BKPCANFD";
BA_ "SysSignalName" SG_ 1228 IRHRDA_NM_RSStoNOS_BKPCANFD "RHRDA_NM_RSStoNOS_BKPCANFD";
BA_ "CompuMethodName" SG_ 1228 IRHRDA_NM_RSStoRMS_BKPCANFD "RHRDA_NM_RSStoRMS_BKPCANFD";
BA_ "ISignalName" SG_ 1228 IRHRDA_NM_RSStoRMS_BKPCANFD "IRHRDA_NM_RSStoRMS_BKPCANFD";
BA_ "LongName" SG_ 1228 IRHRDA_NM_RSStoRMS_BKPCANFD "RHRDA_NM_RSStoRMS_BKPCANFD";
BA_ "SysSignalName" SG_ 1228 IRHRDA_NM_RSStoRMS_BKPCANFD "RHRDA_NM_RSStoRMS_BKPCANFD";
BA_ "CompuMethodName" SG_ 1228 IRHRDA_NM_NOStoRMS_BKPCANFD "RHRDA_NM_NOStoRMS_BKPCANFD";
BA_ "ISignalName" SG_ 1228 IRHRDA_NM_NOStoRMS_BKPCANFD "IRHRDA_NM_NOStoRMS_BKPCANFD";
BA_ "LongName" SG_ 1228 IRHRDA_NM_NOStoRMS_BKPCANFD "RHRDA_NM_NOStoRMS_BKPCANFD";
BA_ "SysSignalName" SG_ 1228 IRHRDA_NM_NOStoRMS_BKPCANFD "RHRDA_NM_NOStoRMS_BKPCANFD";
BA_ "CompuMethodName" SG_ 1228 IRHRDA_NM_NOSSta_BKPCANFD "RHRDA_NM_NOSSta_BKPCANFD";
BA_ "ISignalName" SG_ 1228 IRHRDA_NM_NOSSta_BKPCANFD "IRHRDA_NM_NOSSta_BKPCANFD";
BA_ "LongName" SG_ 1228 IRHRDA_NM_NOSSta_BKPCANFD "RHRDA_NM_NOSSta_BKPCANFD";
BA_ "SysSignalName" SG_ 1228 IRHRDA_NM_NOSSta_BKPCANFD "RHRDA_NM_NOSSta_BKPCANFD";
BA_ "CompuMethodName" SG_ 1228 IRHRDA_NM_RMSSta_BKPCANFD "RHRDA_NM_RMSSta_BKPCANFD";
BA_ "ISignalName" SG_ 1228 IRHRDA_NM_RMSSta_BKPCANFD "IRHRDA_NM_RMSSta_BKPCANFD";
BA_ "LongName" SG_ 1228 IRHRDA_NM_RMSSta_BKPCANFD "RHRDA_NM_RMSSta_BKPCANFD";
BA_ "SysSignalName" SG_ 1228 IRHRDA_NM_RMSSta_BKPCANFD "RHRDA_NM_RMSSta_BKPCANFD";
BA_ "CompuMethodName" SG_ 1228 IRHRDA_NWI_BKPCANFD "RHRDA_NWI_BKPCANFD";
BA_ "ISignalName" SG_ 1228 IRHRDA_NWI_BKPCANFD "IRHRDA_NWI_BKPCANFD";
BA_ "LongName" SG_ 1228 IRHRDA_NWI_BKPCANFD "RHRDA BKPCANFD Network_Wakeup_Indication";
BA_ "SysSignalName" SG_ 1228 IRHRDA_NWI_BKPCANFD "RHRDA_NWI_BKPCANFD";
BA_ "CompuMethodName" SG_ 1228 IRHRDA_NOI_BKPCANFD "RHRDA_NOI_BKPCANFD";
BA_ "ISignalName" SG_ 1228 IRHRDA_NOI_BKPCANFD "IRHRDA_NOI_BKPCANFD";
BA_ "LongName" SG_ 1228 IRHRDA_NOI_BKPCANFD "RHRDA BKPCANFD Network Operation Indication";
BA_ "SysSignalName" SG_ 1228 IRHRDA_NOI_BKPCANFD "RHRDA_NOI_BKPCANFD";
BA_ "CompuMethodName" SG_ 1228 IRHRDA_NKI_BKPCANFD "RHRDA_NKI_BKPCANFD";
BA_ "ISignalName" SG_ 1228 IRHRDA_NKI_BKPCANFD "IRHRDA_NKI_BKPCANFD";
BA_ "LongName" SG_ 1228 IRHRDA_NKI_BKPCANFD "RHRDA BKPCANFD Network Keep Indication";
BA_ "SysSignalName" SG_ 1228 IRHRDA_NKI_BKPCANFD "RHRDA_NKI_BKPCANFD";
BA_ "CompuMethodName" SG_ 936 IESSPTCHVILStsV_RHZCU "ESSPTCHVILStsV_RHZCU";
BA_ "GenSigStartValue" SG_ 936 IESSPTCHVILStsV_RHZCU 1;
BA_ "ISignalName" SG_ 936 IESSPTCHVILStsV_RHZCU "IESSPTCHVILStsV_RHZCU";
BA_ "LongName" SG_ 936 IESSPTCHVILStsV_RHZCU "Energy Store System PTC High Voltage Interlock Loop Status Validity";
BA_ "SysSignalName" SG_ 936 IESSPTCHVILStsV_RHZCU "ESSPTCHVILStsV_RHZCU";
BA_ "CompuMethodName" SG_ 936 IESSPTCHVILSts_RHZCU "ESSPTCHVILSts_RHZCU";
BA_ "ISignalName" SG_ 936 IESSPTCHVILSts_RHZCU "IESSPTCHVILSts_RHZCU";
BA_ "LongName" SG_ 936 IESSPTCHVILSts_RHZCU "Energy Store System PTC High Voltage Interlock Loop Status";
BA_ "SysSignalName" SG_ 936 IESSPTCHVILSts_RHZCU "ESSPTCHVILSts_RHZCU";
BA_ "CompuMethodName" SG_ 936 IFrSsdLrngFailRrsn "FrSsdLrngFailRrsn";
BA_ "ISignalName" SG_ 936 IFrSsdLrngFailRrsn "IFrSsdLrngFailRrsn";
BA_ "LongName" SG_ 936 IFrSsdLrngFailRrsn "Front_Sunshade_Learning_Fail_Reason";
BA_ "SysSignalName" SG_ 936 IFrSsdLrngFailRrsn "FrSsdLrngFailRrsn";
BA_ "CompuMethodName" SG_ 936 IAVCamrHeatFltSts "AVCamrHeatFltSts";
BA_ "ISignalName" SG_ 936 IAVCamrHeatFltSts "IAVCamrHeatFltSts";
BA_ "LongName" SG_ 936 IAVCamrHeatFltSts "AVCamr_Heater_Fault_Status";
BA_ "SysSignalName" SG_ 936 IAVCamrHeatFltSts "AVCamrHeatFltSts";
BA_ "CompuMethodName" SG_ 936 IAVCamrHeatVol "AVCamrHeatVol";
BA_ "ISignalName" SG_ 936 IAVCamrHeatVol "IAVCamrHeatVol";
BA_ "LongName" SG_ 936 IAVCamrHeatVol "AVCamr_Heat_Voltage";
BA_ "SysSignalName" SG_ 936 IAVCamrHeatVol "AVCamrHeatVol";
BA_ "CompuMethodName" SG_ 701 IITMSEDUClntInltTem "ITMSEDUClntInltTem";
BA_ "ISignalName" SG_ 701 IITMSEDUClntInltTem "IITMSEDUClntInltTem";
BA_ "LongName" SG_ 701 IITMSEDUClntInltTem "ITMS_EDU_Coolant_Inlet_Temperature";
BA_ "SysSignalName" SG_ 701 IITMSEDUClntInltTem "ITMSEDUClntInltTem";
BA_ "CompuMethodName" SG_ 701 IITMSAGS1Pos "ITMSAGS1Pos";
BA_ "ISignalName" SG_ 701 IITMSAGS1Pos "IITMSAGS1Pos";
BA_ "LongName" SG_ 701 IITMSAGS1Pos "Aero Grille Shutter 1 Position";
BA_ "SysSignalName" SG_ 701 IITMSAGS1Pos "ITMSAGS1Pos";
BA_ "CompuMethodName" SG_ 701 IITMSAGS2Pos "ITMSAGS2Pos";
BA_ "ISignalName" SG_ 701 IITMSAGS2Pos "IITMSAGS2Pos";
BA_ "LongName" SG_ 701 IITMSAGS2Pos "Aero Grille Shutter 2 Position";
BA_ "SysSignalName" SG_ 701 IITMSAGS2Pos "ITMSAGS2Pos";
BA_ "CompuMethodName" SG_ 701 IITMSEDUClntInltTemV "ITMSEDUClntInltTemV";
BA_ "ISignalName" SG_ 701 IITMSEDUClntInltTemV "IITMSEDUClntInltTemV";
BA_ "LongName" SG_ 701 IITMSEDUClntInltTemV "ITMS EDU Coolant Inlet Temperature Validity";
BA_ "SysSignalName" SG_ 701 IITMSEDUClntInltTemV "ITMSEDUClntInltTemV";
BA_ "CompuMethodName" SG_ 701 IEACPwrLmtSts "EACPwrLmtSts";
BA_ "ISignalName" SG_ 701 IEACPwrLmtSts "IEACPwrLmtSts";
BA_ "LongName" SG_ 701 IEACPwrLmtSts "EAC Power Limit Status";
BA_ "SysSignalName" SG_ 701 IEACPwrLmtSts "EACPwrLmtSts";
BA_ "CompuMethodName" SG_ 701 IITMSEnbWPTC "ITMSEnbWPTC";
BA_ "ISignalName" SG_ 701 IITMSEnbWPTC "IITMSEnbWPTC";
BA_ "LongName" SG_ 701 IITMSEnbWPTC "ITMS Enable WPTC";
BA_ "SysSignalName" SG_ 701 IITMSEnbWPTC "ITMSEnbWPTC";
BA_ "CompuMethodName" SG_ 701 IITMSEPTCoolngFanSts "ITMSEPTCoolngFanSts";
BA_ "ISignalName" SG_ 701 IITMSEPTCoolngFanSts "IITMSEPTCoolngFanSts";
BA_ "LongName" SG_ 701 IITMSEPTCoolngFanSts "ITMS Electric Powertrain Cooling Fan Status";
BA_ "SysSignalName" SG_ 701 IITMSEPTCoolngFanSts "ITMSEPTCoolngFanSts";
BA_ "CompuMethodName" SG_ 701 IITMSMotHeatEnb "ITMSMotHeatEnb";
BA_ "ISignalName" SG_ 701 IITMSMotHeatEnb "IITMSMotHeatEnb";
BA_ "LongName" SG_ 701 IITMSMotHeatEnb "ITMS Motor Heating Enable";
BA_ "SysSignalName" SG_ 701 IITMSMotHeatEnb "ITMSMotHeatEnb";
BA_ "CompuMethodName" SG_ 701 IITMSBMSClntPumpSts "ITMSBMSClntPumpSts";
BA_ "ISignalName" SG_ 701 IITMSBMSClntPumpSts "IITMSBMSClntPumpSts";
BA_ "LongName" SG_ 701 IITMSBMSClntPumpSts "BMS Coolant Pump status";
BA_ "SysSignalName" SG_ 701 IITMSBMSClntPumpSts "ITMSBMSClntPumpSts";
BA_ "CompuMethodName" SG_ 701 IPTCPwrLmtSts "PTCPwrLmtSts";
BA_ "ISignalName" SG_ 701 IPTCPwrLmtSts "IPTCPwrLmtSts";
BA_ "LongName" SG_ 701 IPTCPwrLmtSts "PTC Power Limit Status";
BA_ "SysSignalName" SG_ 701 IPTCPwrLmtSts "PTCPwrLmtSts";
BA_ "CompuMethodName" SG_ 701 IITMSEPTEDUClntPumpSts "ITMSEPTEDUClntPumpSts";
BA_ "ISignalName" SG_ 701 IITMSEPTEDUClntPumpSts "IITMSEPTEDUClntPumpSts";
BA_ "LongName" SG_ 701 IITMSEPTEDUClntPumpSts "ITMS Electric Powertrain Electric Drive Unit Coolant Pump Status";
BA_ "SysSignalName" SG_ 701 IITMSEPTEDUClntPumpSts "ITMSEPTEDUClntPumpSts";
BA_ "CompuMethodName" SG_ 701 IITMSTMHeatPowReq "ITMSTMHeatPowReq";
BA_ "ISignalName" SG_ 701 IITMSTMHeatPowReq "IITMSTMHeatPowReq";
BA_ "LongName" SG_ 701 IITMSTMHeatPowReq "ITMS Traction Motor Heating Power Request";
BA_ "SysSignalName" SG_ 701 IITMSTMHeatPowReq "ITMSTMHeatPowReq";
BA_ "CompuMethodName" SG_ 962 IRmtBattWarmSts "RmtBattWarmSts";
BA_ "ISignalName" SG_ 962 IRmtBattWarmSts "IRmtBattWarmSts";
BA_ "LongName" SG_ 962 IRmtBattWarmSts "Remote contrl Battery warm Status";
BA_ "SysSignalName" SG_ 962 IRmtBattWarmSts "RmtBattWarmSts";
BA_ "CompuMethodName" SG_ 962 IKeepPwrRsnThrmlSys "KeepPwrRsnThrmlSys";
BA_ "ISignalName" SG_ 962 IKeepPwrRsnThrmlSys "IKeepPwrRsnThrmlSys";
BA_ "LongName" SG_ 962 IKeepPwrRsnThrmlSys "Keep Power Reason Thermal System";
BA_ "SysSignalName" SG_ 962 IKeepPwrRsnThrmlSys "KeepPwrRsnThrmlSys";
BA_ "CompuMethodName" SG_ 962 IRmtBattWarmAbotRsn "RmtBattWarmAbotRsn";
BA_ "ISignalName" SG_ 962 IRmtBattWarmAbotRsn "IRmtBattWarmAbotRsn";
BA_ "LongName" SG_ 962 IRmtBattWarmAbotRsn "Remote contrl Battery warm  Abort Reason";
BA_ "SysSignalName" SG_ 962 IRmtBattWarmAbotRsn "RmtBattWarmAbotRsn";
BA_ "CompuMethodName" SG_ 962 IITMSBMSPumpActuPWM "ITMSBMSPumpActuPWM";
BA_ "ISignalName" SG_ 962 IITMSBMSPumpActuPWM "IITMSBMSPumpActuPWM";
BA_ "LongName" SG_ 962 IITMSBMSPumpActuPWM "High Voltage Battery Pump Actual Pwm";
BA_ "SysSignalName" SG_ 962 IITMSBMSPumpActuPWM "ITMSBMSPumpActuPWM";
BA_ "CompuMethodName" SG_ 962 IITMSBattHeatPwrReq "ITMSBattHeatPwrReq";
BA_ "ISignalName" SG_ 962 IITMSBattHeatPwrReq "IITMSBattHeatPwrReq";
BA_ "LongName" SG_ 962 IITMSBattHeatPwrReq "ITMS Battery Heating Request";
BA_ "SysSignalName" SG_ 962 IITMSBattHeatPwrReq "ITMSBattHeatPwrReq";
BA_ "CompuMethodName" SG_ 962 IITMSEDSPumpActuPWM "ITMSEDSPumpActuPWM";
BA_ "ISignalName" SG_ 962 IITMSEDSPumpActuPWM "IITMSEDSPumpActuPWM";
BA_ "LongName" SG_ 962 IITMSEDSPumpActuPWM "ITMS EDSPump Actual PWM";
BA_ "SysSignalName" SG_ 962 IITMSEDSPumpActuPWM "ITMSEDSPumpActuPWM";
BA_ "CompuMethodName" SG_ 943 IFRDoorOpenSts "FRDoorOpenSts";
BA_ "ISignalName" SG_ 943 IFRDoorOpenSts "IFRDoorOpenSts";
BA_ "LongName" SG_ 943 IFRDoorOpenSts "Front Right Door Open Status";
BA_ "SysSignalName" SG_ 943 IFRDoorOpenSts "FRDoorOpenSts";
BA_ "CompuMethodName" SG_ 943 IRRWinShrtDwnSucd "RRWinShrtDwnSucd";
BA_ "ISignalName" SG_ 943 IRRWinShrtDwnSucd "IRRWinShrtDwnSucd";
BA_ "LongName" SG_ 943 IRRWinShrtDwnSucd "Rear Right Window short down successed";
BA_ "SysSignalName" SG_ 943 IRRWinShrtDwnSucd "RRWinShrtDwnSucd";
BA_ "CompuMethodName" SG_ 943 IROtsdMirFoldSts "ROtsdMirFoldSts";
BA_ "ISignalName" SG_ 943 IROtsdMirFoldSts "IROtsdMirFoldSts";
BA_ "LongName" SG_ 943 IROtsdMirFoldSts "Right_Outside_Mirror_Fold_Status";
BA_ "SysSignalName" SG_ 943 IROtsdMirFoldSts "ROtsdMirFoldSts";
BA_ "CompuMethodName" SG_ 943 IRRWinMotSts "RRWinMotSts";
BA_ "ISignalName" SG_ 943 IRRWinMotSts "IRRWinMotSts";
BA_ "LongName" SG_ 943 IRRWinMotSts "Rear Right Window Motor Status";
BA_ "SysSignalName" SG_ 943 IRRWinMotSts "RRWinMotSts";
BA_ "CompuMethodName" SG_ 943 IFRWinShrtDwnSucd "FRWinShrtDwnSucd";
BA_ "ISignalName" SG_ 943 IFRWinShrtDwnSucd "IFRWinShrtDwnSucd";
BA_ "LongName" SG_ 943 IFRWinShrtDwnSucd "Front Right Window short down successed";
BA_ "SysSignalName" SG_ 943 IFRWinShrtDwnSucd "FRWinShrtDwnSucd";
BA_ "CompuMethodName" SG_ 943 IRRWinLclSwtFlt "RRWinLclSwtFlt";
BA_ "ISignalName" SG_ 943 IRRWinLclSwtFlt "IRRWinLclSwtFlt";
BA_ "LongName" SG_ 943 IRRWinLclSwtFlt "Rear Right Window Local Switch Fault";
BA_ "SysSignalName" SG_ 943 IRRWinLclSwtFlt "RRWinLclSwtFlt";
BA_ "CompuMethodName" SG_ 943 IRRWinLclSwtSts "RRWinLclSwtSts";
BA_ "ISignalName" SG_ 943 IRRWinLclSwtSts "IRRWinLclSwtSts";
BA_ "LongName" SG_ 943 IRRWinLclSwtSts "Rear Right Window Local Switch Status";
BA_ "SysSignalName" SG_ 943 IRRWinLclSwtSts "RRWinLclSwtSts";
BA_ "CompuMethodName" SG_ 943 IRRWinIninSts "RRWinIninSts";
BA_ "ISignalName" SG_ 943 IRRWinIninSts "IRRWinIninSts";
BA_ "LongName" SG_ 943 IRRWinIninSts "Rear Right Window Initialized status";
BA_ "SysSignalName" SG_ 943 IRRWinIninSts "RRWinIninSts";
BA_ "CompuMethodName" SG_ 943 IFRWinIninSts "FRWinIninSts";
BA_ "ISignalName" SG_ 943 IFRWinIninSts "IFRWinIninSts";
BA_ "LongName" SG_ 943 IFRWinIninSts "Front Right Window Initialized status";
BA_ "SysSignalName" SG_ 943 IFRWinIninSts "FRWinIninSts";
BA_ "CompuMethodName" SG_ 943 IRRWinMotFlt "RRWinMotFlt";
BA_ "ISignalName" SG_ 943 IRRWinMotFlt "IRRWinMotFlt";
BA_ "LongName" SG_ 943 IRRWinMotFlt "Rear Right Window Motor Fault";
BA_ "SysSignalName" SG_ 943 IRRWinMotFlt "RRWinMotFlt";
BA_ "CompuMethodName" SG_ 649 IRHZCU_50ms_Group01_CRC "RHZCU_50ms_Group01_CRC";
BA_ "ISignalName" SG_ 649 IRHZCU_50ms_Group01_CRC "IRHZCU_50ms_Group01_CRC";
BA_ "SysSignalName" SG_ 649 IRHZCU_50ms_Group01_CRC "RHZCU_50ms_Group01_CRC";
BA_ "CompuMethodName" SG_ 649 IRHZCU_50ms_Group01_RC "RHZCU_50ms_Group01_RC";
BA_ "ISignalName" SG_ 649 IRHZCU_50ms_Group01_RC "IRHZCU_50ms_Group01_RC";
BA_ "SysSignalName" SG_ 649 IRHZCU_50ms_Group01_RC "RHZCU_50ms_Group01_RC";
BA_ "CompuMethodName" SG_ 649 IRRDoorOpenSts "RRDoorOpenSts";
BA_ "ISignalName" SG_ 649 IRRDoorOpenSts "IRRDoorOpenSts";
BA_ "LongName" SG_ 649 IRRDoorOpenSts "Rear_Right_Door_Open_Status";
BA_ "SysSignalName" SG_ 649 IRRDoorOpenSts "RRDoorOpenSts";
BA_ "CompuMethodName" SG_ 649 IRHZCU_50ms_Group01_Reserved1 "RHZCU_50ms_Group01_Reserved1";
BA_ "GenSigStartValue" SG_ 649 IRHZCU_50ms_Group01_Reserved1 3;
BA_ "ISignalName" SG_ 649 IRHZCU_50ms_Group01_Reserved1 "IRHZCU_50ms_Group01_Reserved1";
BA_ "SysSignalName" SG_ 649 IRHZCU_50ms_Group01_Reserved1 "RHZCU_50ms_Group01_Reserved1";
BA_ "CompuMethodName" SG_ 649 IRHZCUeSw41DiagSts "RHZCUeSw41DiagSts";
BA_ "ISignalName" SG_ 649 IRHZCUeSw41DiagSts "IRHZCUeSw41DiagSts";
BA_ "LongName" SG_ 649 IRHZCUeSw41DiagSts "RHZCU eSwitch41 Diagnostic Status";
BA_ "SysSignalName" SG_ 649 IRHZCUeSw41DiagSts "RHZCUeSw41DiagSts";
BA_ "CompuMethodName" SG_ 649 IRHZCU_50ms_Group01_Reserved2 "RHZCU_50ms_Group01_Reserved2";
BA_ "GenSigStartValue" SG_ 649 IRHZCU_50ms_Group01_Reserved2 15;
BA_ "ISignalName" SG_ 649 IRHZCU_50ms_Group01_Reserved2 "IRHZCU_50ms_Group01_Reserved2";
BA_ "SysSignalName" SG_ 649 IRHZCU_50ms_Group01_Reserved2 "RHZCU_50ms_Group01_Reserved2";
BA_ "CompuMethodName" SG_ 649 IRHZCU_50ms_Group01_Reserved3 "RHZCU_50ms_Group01_Reserved3";
BA_ "GenSigStartValue" SG_ 649 IRHZCU_50ms_Group01_Reserved3 31;
BA_ "ISignalName" SG_ 649 IRHZCU_50ms_Group01_Reserved3 "IRHZCU_50ms_Group01_Reserved3";
BA_ "SysSignalName" SG_ 649 IRHZCU_50ms_Group01_Reserved3 "RHZCU_50ms_Group01_Reserved3";
BA_ "CompuMethodName" SG_ 649 IRHZCUeSw41Sts "RHZCUeSw41Sts";
BA_ "ISignalName" SG_ 649 IRHZCUeSw41Sts "IRHZCUeSw41Sts";
BA_ "LongName" SG_ 649 IRHZCUeSw41Sts "RHZCU eSwitch41 Status";
BA_ "SysSignalName" SG_ 649 IRHZCUeSw41Sts "RHZCUeSw41Sts";
BA_ "CompuMethodName" SG_ 649 IRHZCU_50ms_Group01_Reserved4 "RHZCU_50ms_Group01_Reserved4";
BA_ "GenSigStartValue" SG_ 649 IRHZCU_50ms_Group01_Reserved4 255;
BA_ "ISignalName" SG_ 649 IRHZCU_50ms_Group01_Reserved4 "IRHZCU_50ms_Group01_Reserved4";
BA_ "SysSignalName" SG_ 649 IRHZCU_50ms_Group01_Reserved4 "RHZCU_50ms_Group01_Reserved4";
BA_ "CompuMethodName" SG_ 649 IRHZCU_50ms_Group01_Reserved5 "RHZCU_50ms_Group01_Reserved5";
BA_ "GenSigStartValue" SG_ 649 IRHZCU_50ms_Group01_Reserved5 255;
BA_ "ISignalName" SG_ 649 IRHZCU_50ms_Group01_Reserved5 "IRHZCU_50ms_Group01_Reserved5";
BA_ "SysSignalName" SG_ 649 IRHZCU_50ms_Group01_Reserved5 "RHZCU_50ms_Group01_Reserved5";
BA_ "CompuMethodName" SG_ 649 IRHZCU_50ms_Group01_Reserved6 "RHZCU_50ms_Group01_Reserved6";
BA_ "GenSigStartValue" SG_ 649 IRHZCU_50ms_Group01_Reserved6 255;
BA_ "ISignalName" SG_ 649 IRHZCU_50ms_Group01_Reserved6 "IRHZCU_50ms_Group01_Reserved6";
BA_ "SysSignalName" SG_ 649 IRHZCU_50ms_Group01_Reserved6 "RHZCU_50ms_Group01_Reserved6";
BA_ "CompuMethodName" SG_ 649 IRHZCU_50ms_Group01_Reserved7 "RHZCU_50ms_Group01_Reserved7";
BA_ "GenSigStartValue" SG_ 649 IRHZCU_50ms_Group01_Reserved7 255;
BA_ "ISignalName" SG_ 649 IRHZCU_50ms_Group01_Reserved7 "IRHZCU_50ms_Group01_Reserved7";
BA_ "SysSignalName" SG_ 649 IRHZCU_50ms_Group01_Reserved7 "RHZCU_50ms_Group01_Reserved7";
BA_ "CompuMethodName" SG_ 940 IRHZCUeSw14Sts "RHZCUeSw14Sts";
BA_ "ISignalName" SG_ 940 IRHZCUeSw14Sts "IRHZCUeSw14Sts";
BA_ "LongName" SG_ 940 IRHZCUeSw14Sts "RHZCU eSwitch14 Status";
BA_ "SysSignalName" SG_ 940 IRHZCUeSw14Sts "RHZCUeSw14Sts";
BA_ "CompuMethodName" SG_ 940 IRHZCUeSw14DiagSts "RHZCUeSw14DiagSts";
BA_ "ISignalName" SG_ 940 IRHZCUeSw14DiagSts "IRHZCUeSw14DiagSts";
BA_ "LongName" SG_ 940 IRHZCUeSw14DiagSts "RHZCU eSwitch14 Diagnostic Status";
BA_ "SysSignalName" SG_ 940 IRHZCUeSw14DiagSts "RHZCUeSw14DiagSts";
BA_ "CompuMethodName" SG_ 940 IRHZCUeSw31Sts "RHZCUeSw31Sts";
BA_ "ISignalName" SG_ 940 IRHZCUeSw31Sts "IRHZCUeSw31Sts";
BA_ "LongName" SG_ 940 IRHZCUeSw31Sts "RHZCU eSwitch31 Status";
BA_ "SysSignalName" SG_ 940 IRHZCUeSw31Sts "RHZCUeSw31Sts";
BA_ "CompuMethodName" SG_ 940 IRHZCUeSw31DiagSts "RHZCUeSw31DiagSts";
BA_ "ISignalName" SG_ 940 IRHZCUeSw31DiagSts "IRHZCUeSw31DiagSts";
BA_ "LongName" SG_ 940 IRHZCUeSw31DiagSts "RHZCU eSwitch31 Diagnostic Status";
BA_ "SysSignalName" SG_ 940 IRHZCUeSw31DiagSts "RHZCUeSw31DiagSts";
BA_ "CompuMethodName" SG_ 940 IRHZCUIgnSts "RHZCUIgnSts";
BA_ "ISignalName" SG_ 940 IRHZCUIgnSts "IRHZCUIgnSts";
BA_ "LongName" SG_ 940 IRHZCUIgnSts "RHZCU Ignition Status";
BA_ "SysSignalName" SG_ 940 IRHZCUIgnSts "RHZCUIgnSts";
BA_ "CompuMethodName" SG_ 940 IRHZCUIgnDiagSts "RHZCUIgnDiagSts";
BA_ "ISignalName" SG_ 940 IRHZCUIgnDiagSts "IRHZCUIgnDiagSts";
BA_ "LongName" SG_ 940 IRHZCUIgnDiagSts "RHZCU Ignition Diagnostic Status";
BA_ "SysSignalName" SG_ 940 IRHZCUIgnDiagSts "RHZCUIgnDiagSts";
BA_ "CompuMethodName" SG_ 940 IRHZCUeFs3Sts "RHZCUeFs3Sts";
BA_ "ISignalName" SG_ 940 IRHZCUeFs3Sts "IRHZCUeFs3Sts";
BA_ "LongName" SG_ 940 IRHZCUeFs3Sts "RHZCU eFuse3 Status";
BA_ "SysSignalName" SG_ 940 IRHZCUeFs3Sts "RHZCUeFs3Sts";
BA_ "CompuMethodName" SG_ 940 IRHZCUeFs3DiagSts "RHZCUeFs3DiagSts";
BA_ "ISignalName" SG_ 940 IRHZCUeFs3DiagSts "IRHZCUeFs3DiagSts";
BA_ "LongName" SG_ 940 IRHZCUeFs3DiagSts "RHZCU eFuse3 Diagnostic Status";
BA_ "SysSignalName" SG_ 940 IRHZCUeFs3DiagSts "RHZCUeFs3DiagSts";
BA_ "CompuMethodName" SG_ 940 IRHZCUeFs2Sts "RHZCUeFs2Sts";
BA_ "ISignalName" SG_ 940 IRHZCUeFs2Sts "IRHZCUeFs2Sts";
BA_ "LongName" SG_ 940 IRHZCUeFs2Sts "RHZCU eFuse2 Status";
BA_ "SysSignalName" SG_ 940 IRHZCUeFs2Sts "RHZCUeFs2Sts";
BA_ "CompuMethodName" SG_ 940 IRHZCUeFs2DiagSts "RHZCUeFs2DiagSts";
BA_ "ISignalName" SG_ 940 IRHZCUeFs2DiagSts "IRHZCUeFs2DiagSts";
BA_ "LongName" SG_ 940 IRHZCUeFs2DiagSts "RHZCU eFuse2 Diagnostic Status";
BA_ "SysSignalName" SG_ 940 IRHZCUeFs2DiagSts "RHZCUeFs2DiagSts";
BA_ "CompuMethodName" SG_ 940 IRHZCUeFs1Sts "RHZCUeFs1Sts";
BA_ "ISignalName" SG_ 940 IRHZCUeFs1Sts "IRHZCUeFs1Sts";
BA_ "LongName" SG_ 940 IRHZCUeFs1Sts "RHZCU eFuse1 Status";
BA_ "SysSignalName" SG_ 940 IRHZCUeFs1Sts "RHZCUeFs1Sts";
BA_ "CompuMethodName" SG_ 940 IRHZCUeFs1DiagSts "RHZCUeFs1DiagSts";
BA_ "ISignalName" SG_ 940 IRHZCUeFs1DiagSts "IRHZCUeFs1DiagSts";
BA_ "LongName" SG_ 940 IRHZCUeFs1DiagSts "RHZCU eFuse1 Diagnostic Status";
BA_ "SysSignalName" SG_ 940 IRHZCUeFs1DiagSts "RHZCUeFs1DiagSts";
BA_ "CompuMethodName" SG_ 940 IRHZCUeSw10Sts "RHZCUeSw10Sts";
BA_ "ISignalName" SG_ 940 IRHZCUeSw10Sts "IRHZCUeSw10Sts";
BA_ "LongName" SG_ 940 IRHZCUeSw10Sts "RHZCU eSwitch10 Status";
BA_ "SysSignalName" SG_ 940 IRHZCUeSw10Sts "RHZCUeSw10Sts";
BA_ "CompuMethodName" SG_ 940 IRHZCUeSw10DiagSts "RHZCUeSw10DiagSts";
BA_ "ISignalName" SG_ 940 IRHZCUeSw10DiagSts "IRHZCUeSw10DiagSts";
BA_ "LongName" SG_ 940 IRHZCUeSw10DiagSts "RHZCU eSwitch10 Diagnostic Status";
BA_ "SysSignalName" SG_ 940 IRHZCUeSw10DiagSts "RHZCUeSw10DiagSts";
BA_ "CompuMethodName" SG_ 940 IRHZCUeSw34Sts "RHZCUeSw34Sts";
BA_ "ISignalName" SG_ 940 IRHZCUeSw34Sts "IRHZCUeSw34Sts";
BA_ "LongName" SG_ 940 IRHZCUeSw34Sts "RHZCU eSwitch34 Status";
BA_ "SysSignalName" SG_ 940 IRHZCUeSw34Sts "RHZCUeSw34Sts";
BA_ "CompuMethodName" SG_ 940 IRHZCUeSw34DiagSts "RHZCUeSw34DiagSts";
BA_ "ISignalName" SG_ 940 IRHZCUeSw34DiagSts "IRHZCUeSw34DiagSts";
BA_ "LongName" SG_ 940 IRHZCUeSw34DiagSts "RHZCU eSwitch34 Diagnostic Status";
BA_ "SysSignalName" SG_ 940 IRHZCUeSw34DiagSts "RHZCUeSw34DiagSts";
BA_ "CompuMethodName" SG_ 564 IRLDircnLghtSts "RLDircnLghtSts";
BA_ "ISignalName" SG_ 564 IRLDircnLghtSts "IRLDircnLghtSts";
BA_ "LongName" SG_ 564 IRLDircnLghtSts "Rear Left_Direction_Light_Status";
BA_ "SysSignalName" SG_ 564 IRLDircnLghtSts "RLDircnLghtSts";
BA_ "CompuMethodName" SG_ 564 IRRDircnLghtSts "RRDircnLghtSts";
BA_ "ISignalName" SG_ 564 IRRDircnLghtSts "IRRDircnLghtSts";
BA_ "LongName" SG_ 564 IRRDircnLghtSts "Rear_Right_Direction_Light_Status";
BA_ "SysSignalName" SG_ 564 IRRDircnLghtSts "RRDircnLghtSts";
BA_ "CompuMethodName" SG_ 564 IRRDircnLghtFltsts "RRDircnLghtFltsts";
BA_ "ISignalName" SG_ 564 IRRDircnLghtFltsts "IRRDircnLghtFltsts";
BA_ "LongName" SG_ 564 IRRDircnLghtFltsts "Rear_Right_Direction_Light_Fault_Status";
BA_ "SysSignalName" SG_ 564 IRRDircnLghtFltsts "RRDircnLghtFltsts";
BA_ "CompuMethodName" SG_ 564 IRLDircnLghtFltsts "RLDircnLghtFltsts";
BA_ "ISignalName" SG_ 564 IRLDircnLghtFltsts "IRLDircnLghtFltsts";
BA_ "LongName" SG_ 564 IRLDircnLghtFltsts "Rear Left_Direction_Light_Fault_Status";
BA_ "SysSignalName" SG_ 564 IRLDircnLghtFltsts "RLDircnLghtFltsts";
BA_ "CompuMethodName" SG_ 564 IRRDircnLghtFltsts_HW "RRDircnLghtFltsts_HW";
BA_ "ISignalName" SG_ 564 IRRDircnLghtFltsts_HW "IRRDircnLghtFltsts_HW";
BA_ "LongName" SG_ 564 IRRDircnLghtFltsts_HW "Right_Rear_Direction_Light_Fault_Status_HardWired";
BA_ "SysSignalName" SG_ 564 IRRDircnLghtFltsts_HW "RRDircnLghtFltsts_HW";
BA_ "CompuMethodName" SG_ 564 IRLDircnLghtFltsts_HW "RLDircnLghtFltsts_HW";
BA_ "ISignalName" SG_ 564 IRLDircnLghtFltsts_HW "IRLDircnLghtFltsts_HW";
BA_ "LongName" SG_ 564 IRLDircnLghtFltsts_HW "Left_Rear_Direction_Light_Fault_Status_HardWired";
BA_ "SysSignalName" SG_ 564 IRLDircnLghtFltsts_HW "RLDircnLghtFltsts_HW";
BA_ "CompuMethodName" SG_ 564 IRearFogLghtFltsts "RearFogLghtFltsts";
BA_ "ISignalName" SG_ 564 IRearFogLghtFltsts "IRearFogLghtFltsts";
BA_ "LongName" SG_ 564 IRearFogLghtFltsts "Rear_Fog_Light_Fault_Status";
BA_ "SysSignalName" SG_ 564 IRearFogLghtFltsts "RearFogLghtFltsts";
BA_ "CompuMethodName" SG_ 564 IRearFogLghtSts "RearFogLghtSts";
BA_ "ISignalName" SG_ 564 IRearFogLghtSts "IRearFogLghtSts";
BA_ "LongName" SG_ 564 IRearFogLghtSts "Rear_Fog_Light_Status";
BA_ "SysSignalName" SG_ 564 IRearFogLghtSts "RearFogLghtSts";
BA_ "CompuMethodName" SG_ 564 IRevsLghtFltSts "RevsLghtFltSts";
BA_ "ISignalName" SG_ 564 IRevsLghtFltSts "IRevsLghtFltSts";
BA_ "LongName" SG_ 564 IRevsLghtFltSts "Reverse_Light_Fault_Status";
BA_ "SysSignalName" SG_ 564 IRevsLghtFltSts "RevsLghtFltSts";
BA_ "CompuMethodName" SG_ 564 IBrkLghtFltSts_HW "BrkLghtFltSts_HW";
BA_ "ISignalName" SG_ 564 IBrkLghtFltSts_HW "IBrkLghtFltSts_HW";
BA_ "LongName" SG_ 564 IBrkLghtFltSts_HW "Brake_Light_Fault_Status_HardWired";
BA_ "SysSignalName" SG_ 564 IBrkLghtFltSts_HW "BrkLghtFltSts_HW";
BA_ "CompuMethodName" SG_ 564 IBrkLghtSts_HW "BrkLghtSts_HW";
BA_ "ISignalName" SG_ 564 IBrkLghtSts_HW "IBrkLghtSts_HW";
BA_ "LongName" SG_ 564 IBrkLghtSts_HW "Brake Light Status";
BA_ "SysSignalName" SG_ 564 IBrkLghtSts_HW "BrkLghtSts_HW";
BA_ "CompuMethodName" SG_ 564 IRLDircnLghtSts_HW "RLDircnLghtSts_HW";
BA_ "ISignalName" SG_ 564 IRLDircnLghtSts_HW "IRLDircnLghtSts_HW";
BA_ "LongName" SG_ 564 IRLDircnLghtSts_HW "Left Rear Direction Light Status";
BA_ "SysSignalName" SG_ 564 IRLDircnLghtSts_HW "RLDircnLghtSts_HW";
BA_ "CompuMethodName" SG_ 564 IRRDircnLghtSts_HW "RRDircnLghtSts_HW";
BA_ "ISignalName" SG_ 564 IRRDircnLghtSts_HW "IRRDircnLghtSts_HW";
BA_ "LongName" SG_ 564 IRRDircnLghtSts_HW "Right Rear Direction Light Status";
BA_ "SysSignalName" SG_ 564 IRRDircnLghtSts_HW "RRDircnLghtSts_HW";
BA_ "CompuMethodName" SG_ 564 ILdspcOpenSts "LdspcOpenSts";
BA_ "ISignalName" SG_ 564 ILdspcOpenSts "ILdspcOpenSts";
BA_ "LongName" SG_ 564 ILdspcOpenSts "Loadspace Open Status";
BA_ "SysSignalName" SG_ 564 ILdspcOpenSts "LdspcOpenSts";
BA_ "CompuMethodName" SG_ 564 IRevsLghtSts "RevsLghtSts";
BA_ "ISignalName" SG_ 564 IRevsLghtSts "IRevsLghtSts";
BA_ "LongName" SG_ 564 IRevsLghtSts "Reverse Light Status";
BA_ "SysSignalName" SG_ 564 IRevsLghtSts "RevsLghtSts";
BA_ "CompuMethodName" SG_ 564 ILdspcOpenStsV "LdspcOpenStsV";
BA_ "ISignalName" SG_ 564 ILdspcOpenStsV "ILdspcOpenStsV";
BA_ "LongName" SG_ 564 ILdspcOpenStsV "Loadspace Open Status Validity";
BA_ "SysSignalName" SG_ 564 ILdspcOpenStsV "LdspcOpenStsV";
BA_ "CompuMethodName" SG_ 564 IRLChrgrFlapOpenPos "RLChrgrFlapOpenPos";
BA_ "ISignalName" SG_ 564 IRLChrgrFlapOpenPos "IRLChrgrFlapOpenPos";
BA_ "LongName" SG_ 564 IRLChrgrFlapOpenPos "Rear Left Charger Flap Open Position";
BA_ "SysSignalName" SG_ 564 IRLChrgrFlapOpenPos "RLChrgrFlapOpenPos";
BA_ "CompuMethodName" SG_ 517 IRZCUeSw10Sts "RZCUeSw10Sts";
BA_ "ISignalName" SG_ 517 IRZCUeSw10Sts "IRZCUeSw10Sts";
BA_ "LongName" SG_ 517 IRZCUeSw10Sts "RZCU eSwitch10 Status";
BA_ "SysSignalName" SG_ 517 IRZCUeSw10Sts "RZCUeSw10Sts";
BA_ "CompuMethodName" SG_ 517 IRZCUeSw10DiagSts "RZCUeSw10DiagSts";
BA_ "ISignalName" SG_ 517 IRZCUeSw10DiagSts "IRZCUeSw10DiagSts";
BA_ "LongName" SG_ 517 IRZCUeSw10DiagSts "RZCU eSwitch10 Diagnostic Status";
BA_ "SysSignalName" SG_ 517 IRZCUeSw10DiagSts "RZCUeSw10DiagSts";
BA_ "CompuMethodName" SG_ 517 IRZCUIgnSts "RZCUIgnSts";
BA_ "ISignalName" SG_ 517 IRZCUIgnSts "IRZCUIgnSts";
BA_ "LongName" SG_ 517 IRZCUIgnSts "RZCU Ignition Status";
BA_ "SysSignalName" SG_ 517 IRZCUIgnSts "RZCUIgnSts";
BA_ "CompuMethodName" SG_ 517 IRZCUIgnDiagSts "RZCUIgnDiagSts";
BA_ "ISignalName" SG_ 517 IRZCUIgnDiagSts "IRZCUIgnDiagSts";
BA_ "LongName" SG_ 517 IRZCUIgnDiagSts "RZCU Ignition Diagnostic Status";
BA_ "SysSignalName" SG_ 517 IRZCUIgnDiagSts "RZCUIgnDiagSts";
BA_ "CompuMethodName" SG_ 517 IRZCUeFs3Sts "RZCUeFs3Sts";
BA_ "ISignalName" SG_ 517 IRZCUeFs3Sts "IRZCUeFs3Sts";
BA_ "LongName" SG_ 517 IRZCUeFs3Sts "RZCU eFuse3 Status";
BA_ "SysSignalName" SG_ 517 IRZCUeFs3Sts "RZCUeFs3Sts";
BA_ "CompuMethodName" SG_ 517 IRZCUeFs3DiagSts "RZCUeFs3DiagSts";
BA_ "ISignalName" SG_ 517 IRZCUeFs3DiagSts "IRZCUeFs3DiagSts";
BA_ "LongName" SG_ 517 IRZCUeFs3DiagSts "RZCU eFuse3 Diagnostic Status";
BA_ "SysSignalName" SG_ 517 IRZCUeFs3DiagSts "RZCUeFs3DiagSts";
BA_ "CompuMethodName" SG_ 517 IRZCUeFs2Sts "RZCUeFs2Sts";
BA_ "ISignalName" SG_ 517 IRZCUeFs2Sts "IRZCUeFs2Sts";
BA_ "LongName" SG_ 517 IRZCUeFs2Sts "RZCU eFuse2 Status";
BA_ "SysSignalName" SG_ 517 IRZCUeFs2Sts "RZCUeFs2Sts";
BA_ "CompuMethodName" SG_ 517 IRZCUeFs2DiagSts "RZCUeFs2DiagSts";
BA_ "ISignalName" SG_ 517 IRZCUeFs2DiagSts "IRZCUeFs2DiagSts";
BA_ "LongName" SG_ 517 IRZCUeFs2DiagSts "RZCU eFuse2 Diagnostic Status";
BA_ "SysSignalName" SG_ 517 IRZCUeFs2DiagSts "RZCUeFs2DiagSts";
BA_ "CompuMethodName" SG_ 517 IRZCUeFs1Sts "RZCUeFs1Sts";
BA_ "ISignalName" SG_ 517 IRZCUeFs1Sts "IRZCUeFs1Sts";
BA_ "LongName" SG_ 517 IRZCUeFs1Sts "RZCU eFuse1 Status";
BA_ "SysSignalName" SG_ 517 IRZCUeFs1Sts "RZCUeFs1Sts";
BA_ "CompuMethodName" SG_ 517 IRZCUeFs1DiagSts "RZCUeFs1DiagSts";
BA_ "ISignalName" SG_ 517 IRZCUeFs1DiagSts "IRZCUeFs1DiagSts";
BA_ "LongName" SG_ 517 IRZCUeFs1DiagSts "RZCU eFuse1 Diagnostic Status";
BA_ "SysSignalName" SG_ 517 IRZCUeFs1DiagSts "RZCUeFs1DiagSts";
BA_ "CompuMethodName" SG_ 517 IRZCUeSw9Sts "RZCUeSw9Sts";
BA_ "ISignalName" SG_ 517 IRZCUeSw9Sts "IRZCUeSw9Sts";
BA_ "LongName" SG_ 517 IRZCUeSw9Sts "RZCU eSwitch9 Status";
BA_ "SysSignalName" SG_ 517 IRZCUeSw9Sts "RZCUeSw9Sts";
BA_ "CompuMethodName" SG_ 517 IRZCUeSw9DiagSts "RZCUeSw9DiagSts";
BA_ "ISignalName" SG_ 517 IRZCUeSw9DiagSts "IRZCUeSw9DiagSts";
BA_ "LongName" SG_ 517 IRZCUeSw9DiagSts "RZCU eSwitch9 Diagnostic Status";
BA_ "SysSignalName" SG_ 517 IRZCUeSw9DiagSts "RZCUeSw9DiagSts";
VAL_ 960 IIPDThermalWrnngLvl 0 "IPDThermalWrnngLvl_0_Normal" 1 "IPDThermalWrnngLvl_1_Thermal_warning_level_1" 2 "IPDThermalWrnngLvl_2_Thermal_warning_level_2" 3 "IPDThermalWrnngLvl_3__Invalid_Value" 4 "IPDThermalWrnngLvl_4__Invalid_Value" 5 "IPDThermalWrnngLvl_5__Invalid_Value" 6 "IPDThermalWrnngLvl_6__Invalid_Value" 7 "IPDThermalWrnngLvl_7__Invalid_Value" 8 "IPDThermalWrnngLvl_8__Invalid_Value" 9 "IPDThermalWrnngLvl_9__Invalid_Value" 10 "IPDThermalWrnngLvl_10__Invalid_Value" 11 "IPDThermalWrnngLvl_11__Invalid_Value" 12 "IPDThermalWrnngLvl_12__Invalid_Value" 13 "IPDThermalWrnngLvl_13__Invalid_Value" 14 "IPDThermalWrnngLvl_14__Invalid_Value" 15 "IPDThermalWrnngLvl_15__Invalid_Value" 16 "IPDThermalWrnngLvl_16__Invalid_Value" 17 "IPDThermalWrnngLvl_17__Invalid_Value" 18 "IPDThermalWrnngLvl_18__Invalid_Value" 19 "IPDThermalWrnngLvl_19__Invalid_Value" 20 "IPDThermalWrnngLvl_20__Invalid_Value" 21 "IPDThermalWrnngLvl_21__Invalid_Value" 22 "IPDThermalWrnngLvl_22__Invalid_Value" 23 "IPDThermalWrnngLvl_23__Invalid_Value" 24 "IPDThermalWrnngLvl_24__Invalid_Value" 25 "IPDThermalWrnngLvl_25__Invalid_Value" 26 "IPDThermalWrnngLvl_26__Invalid_Value" 27 "IPDThermalWrnngLvl_27__Invalid_Value" 28 "IPDThermalWrnngLvl_28__Invalid_Value" 29 "IPDThermalWrnngLvl_29__Invalid_Value" 30 "IPDThermalWrnngLvl_30__Invalid_Value" 31 "IPDThermalWrnngLvl_31__Invalid_Value" 32 "IPDThermalWrnngLvl_32__Invalid_Value" 33 "IPDThermalWrnngLvl_33__Invalid_Value" 34 "IPDThermalWrnngLvl_34__Invalid_Value" 35 "IPDThermalWrnngLvl_35__Invalid_Value" 36 "IPDThermalWrnngLvl_36__Invalid_Value" 37 "IPDThermalWrnngLvl_37__Invalid_Value" 38 "IPDThermalWrnngLvl_38__Invalid_Value" 39 "IPDThermalWrnngLvl_39__Invalid_Value" 40 "IPDThermalWrnngLvl_40__Invalid_Value" 41 "IPDThermalWrnngLvl_41__Invalid_Value" 42 "IPDThermalWrnngLvl_42__Invalid_Value" 43 "IPDThermalWrnngLvl_43__Invalid_Value" 44 "IPDThermalWrnngLvl_44__Invalid_Value" 45 "IPDThermalWrnngLvl_45__Invalid_Value" 46 "IPDThermalWrnngLvl_46__Invalid_Value" 47 "IPDThermalWrnngLvl_47__Invalid_Value" 48 "IPDThermalWrnngLvl_48__Invalid_Value" 49 "IPDThermalWrnngLvl_49__Invalid_Value" 50 "IPDThermalWrnngLvl_50__Invalid_Value" 51 "IPDThermalWrnngLvl_51__Invalid_Value" 52 "IPDThermalWrnngLvl_52__Invalid_Value" 53 "IPDThermalWrnngLvl_53__Invalid_Value" 54 "IPDThermalWrnngLvl_54__Invalid_Value" 55 "IPDThermalWrnngLvl_55__Invalid_Value" 56 "IPDThermalWrnngLvl_56__Invalid_Value" 57 "IPDThermalWrnngLvl_57__Invalid_Value" 58 "IPDThermalWrnngLvl_58__Invalid_Value" 59 "IPDThermalWrnngLvl_59__Invalid_Value" 60 "IPDThermalWrnngLvl_60__Invalid_Value" 61 "IPDThermalWrnngLvl_61__Invalid_Value" 62 "IPDThermalWrnngLvl_62__Invalid_Value" 63 "IPDThermalWrnngLvl_63__Invalid_Value" 64 "IPDThermalWrnngLvl_64__Invalid_Value" 65 "IPDThermalWrnngLvl_65__Invalid_Value" 66 "IPDThermalWrnngLvl_66__Invalid_Value" 67 "IPDThermalWrnngLvl_67__Invalid_Value" 68 "IPDThermalWrnngLvl_68__Invalid_Value" 69 "IPDThermalWrnngLvl_69__Invalid_Value" 70 "IPDThermalWrnngLvl_70__Invalid_Value" 71 "IPDThermalWrnngLvl_71__Invalid_Value" 72 "IPDThermalWrnngLvl_72__Invalid_Value" 73 "IPDThermalWrnngLvl_73__Invalid_Value" 74 "IPDThermalWrnngLvl_74__Invalid_Value" 75 "IPDThermalWrnngLvl_75__Invalid_Value" 76 "IPDThermalWrnngLvl_76__Invalid_Value" 77 "IPDThermalWrnngLvl_77__Invalid_Value" 78 "IPDThermalWrnngLvl_78__Invalid_Value" 79 "IPDThermalWrnngLvl_79__Invalid_Value" 80 "IPDThermalWrnngLvl_80__Invalid_Value" 81 "IPDThermalWrnngLvl_81__Invalid_Value" 82 "IPDThermalWrnngLvl_82__Invalid_Value" 83 "IPDThermalWrnngLvl_83__Invalid_Value" 84 "IPDThermalWrnngLvl_84__Invalid_Value" 85 "IPDThermalWrnngLvl_85__Invalid_Value" 86 "IPDThermalWrnngLvl_86__Invalid_Value" 87 "IPDThermalWrnngLvl_87__Invalid_Value" 88 "IPDThermalWrnngLvl_88__Invalid_Value" 89 "IPDThermalWrnngLvl_89__Invalid_Value" 90 "IPDThermalWrnngLvl_90__Invalid_Value" 91 "IPDThermalWrnngLvl_91__Invalid_Value" 92 "IPDThermalWrnngLvl_92__Invalid_Value" 93 "IPDThermalWrnngLvl_93__Invalid_Value" 94 "IPDThermalWrnngLvl_94__Invalid_Value" 95 "IPDThermalWrnngLvl_95__Invalid_Value" 96 "IPDThermalWrnngLvl_96__Invalid_Value" 97 "IPDThermalWrnngLvl_97__Invalid_Value" 98 "IPDThermalWrnngLvl_98__Invalid_Value" 99 "IPDThermalWrnngLvl_99__Invalid_Value" 100 "IPDThermalWrnngLvl_100__Invalid_Value" 101 "IPDThermalWrnngLvl_101__Invalid_Value" 102 "IPDThermalWrnngLvl_102__Invalid_Value" 103 "IPDThermalWrnngLvl_103__Invalid_Value" 104 "IPDThermalWrnngLvl_104__Invalid_Value" 105 "IPDThermalWrnngLvl_105__Invalid_Value" 106 "IPDThermalWrnngLvl_106__Invalid_Value" 107 "IPDThermalWrnngLvl_107__Invalid_Value" 108 "IPDThermalWrnngLvl_108__Invalid_Value" 109 "IPDThermalWrnngLvl_109__Invalid_Value" 110 "IPDThermalWrnngLvl_110__Invalid_Value" 111 "IPDThermalWrnngLvl_111__Invalid_Value" 112 "IPDThermalWrnngLvl_112__Invalid_Value" 113 "IPDThermalWrnngLvl_113__Invalid_Value" 114 "IPDThermalWrnngLvl_114__Invalid_Value" 115 "IPDThermalWrnngLvl_115__Invalid_Value" 116 "IPDThermalWrnngLvl_116__Invalid_Value" 117 "IPDThermalWrnngLvl_117__Invalid_Value" 118 "IPDThermalWrnngLvl_118__Invalid_Value" 119 "IPDThermalWrnngLvl_119__Invalid_Value" 120 "IPDThermalWrnngLvl_120__Invalid_Value" 121 "IPDThermalWrnngLvl_121__Invalid_Value" 122 "IPDThermalWrnngLvl_122__Invalid_Value" 123 "IPDThermalWrnngLvl_123__Invalid_Value" 124 "IPDThermalWrnngLvl_124__Invalid_Value" 125 "IPDThermalWrnngLvl_125__Invalid_Value" 126 "IPDThermalWrnngLvl_126__Invalid_Value" 127 "IPDThermalWrnngLvl_127__Invalid_Value" 128 "IPDThermalWrnngLvl_128__Invalid_Value" 129 "IPDThermalWrnngLvl_129__Invalid_Value" 130 "IPDThermalWrnngLvl_130__Invalid_Value" 131 "IPDThermalWrnngLvl_131__Invalid_Value" 132 "IPDThermalWrnngLvl_132__Invalid_Value" 133 "IPDThermalWrnngLvl_133__Invalid_Value" 134 "IPDThermalWrnngLvl_134__Invalid_Value" 135 "IPDThermalWrnngLvl_135__Invalid_Value" 136 "IPDThermalWrnngLvl_136__Invalid_Value" 137 "IPDThermalWrnngLvl_137__Invalid_Value" 138 "IPDThermalWrnngLvl_138__Invalid_Value" 139 "IPDThermalWrnngLvl_139__Invalid_Value" 140 "IPDThermalWrnngLvl_140__Invalid_Value" 141 "IPDThermalWrnngLvl_141__Invalid_Value" 142 "IPDThermalWrnngLvl_142__Invalid_Value" 143 "IPDThermalWrnngLvl_143__Invalid_Value" 144 "IPDThermalWrnngLvl_144__Invalid_Value" 145 "IPDThermalWrnngLvl_145__Invalid_Value" 146 "IPDThermalWrnngLvl_146__Invalid_Value" 147 "IPDThermalWrnngLvl_147__Invalid_Value" 148 "IPDThermalWrnngLvl_148__Invalid_Value" 149 "IPDThermalWrnngLvl_149__Invalid_Value" 150 "IPDThermalWrnngLvl_150__Invalid_Value" 151 "IPDThermalWrnngLvl_151__Invalid_Value" 152 "IPDThermalWrnngLvl_152__Invalid_Value" 153 "IPDThermalWrnngLvl_153__Invalid_Value" 154 "IPDThermalWrnngLvl_154__Invalid_Value" 155 "IPDThermalWrnngLvl_155__Invalid_Value" 156 "IPDThermalWrnngLvl_156__Invalid_Value" 157 "IPDThermalWrnngLvl_157__Invalid_Value" 158 "IPDThermalWrnngLvl_158__Invalid_Value" 159 "IPDThermalWrnngLvl_159__Invalid_Value" 160 "IPDThermalWrnngLvl_160__Invalid_Value" 161 "IPDThermalWrnngLvl_161__Invalid_Value" 162 "IPDThermalWrnngLvl_162__Invalid_Value" 163 "IPDThermalWrnngLvl_163__Invalid_Value" 164 "IPDThermalWrnngLvl_164__Invalid_Value" 165 "IPDThermalWrnngLvl_165__Invalid_Value" 166 "IPDThermalWrnngLvl_166__Invalid_Value" 167 "IPDThermalWrnngLvl_167__Invalid_Value" 168 "IPDThermalWrnngLvl_168__Invalid_Value" 169 "IPDThermalWrnngLvl_169__Invalid_Value" 170 "IPDThermalWrnngLvl_170__Invalid_Value" 171 "IPDThermalWrnngLvl_171__Invalid_Value" 172 "IPDThermalWrnngLvl_172__Invalid_Value" 173 "IPDThermalWrnngLvl_173__Invalid_Value" 174 "IPDThermalWrnngLvl_174__Invalid_Value" 175 "IPDThermalWrnngLvl_175__Invalid_Value" 176 "IPDThermalWrnngLvl_176__Invalid_Value" 177 "IPDThermalWrnngLvl_177__Invalid_Value" 178 "IPDThermalWrnngLvl_178__Invalid_Value" 179 "IPDThermalWrnngLvl_179__Invalid_Value" 180 "IPDThermalWrnngLvl_180__Invalid_Value" 181 "IPDThermalWrnngLvl_181__Invalid_Value" 182 "IPDThermalWrnngLvl_182__Invalid_Value" 183 "IPDThermalWrnngLvl_183__Invalid_Value" 184 "IPDThermalWrnngLvl_184__Invalid_Value" 185 "IPDThermalWrnngLvl_185__Invalid_Value" 186 "IPDThermalWrnngLvl_186__Invalid_Value" 187 "IPDThermalWrnngLvl_187__Invalid_Value" 188 "IPDThermalWrnngLvl_188__Invalid_Value" 189 "IPDThermalWrnngLvl_189__Invalid_Value" 190 "IPDThermalWrnngLvl_190__Invalid_Value" 191 "IPDThermalWrnngLvl_191__Invalid_Value" 192 "IPDThermalWrnngLvl_192__Invalid_Value" 193 "IPDThermalWrnngLvl_193__Invalid_Value" 194 "IPDThermalWrnngLvl_194__Invalid_Value" 195 "IPDThermalWrnngLvl_195__Invalid_Value" 196 "IPDThermalWrnngLvl_196__Invalid_Value" 197 "IPDThermalWrnngLvl_197__Invalid_Value" 198 "IPDThermalWrnngLvl_198__Invalid_Value" 199 "IPDThermalWrnngLvl_199__Invalid_Value" 200 "IPDThermalWrnngLvl_200__Invalid_Value" 201 "IPDThermalWrnngLvl_201__Invalid_Value" 202 "IPDThermalWrnngLvl_202__Invalid_Value" 203 "IPDThermalWrnngLvl_203__Invalid_Value" 204 "IPDThermalWrnngLvl_204__Invalid_Value" 205 "IPDThermalWrnngLvl_205__Invalid_Value" 206 "IPDThermalWrnngLvl_206__Invalid_Value" 207 "IPDThermalWrnngLvl_207__Invalid_Value" 208 "IPDThermalWrnngLvl_208__Invalid_Value" 209 "IPDThermalWrnngLvl_209__Invalid_Value" 210 "IPDThermalWrnngLvl_210__Invalid_Value" 211 "IPDThermalWrnngLvl_211__Invalid_Value" 212 "IPDThermalWrnngLvl_212__Invalid_Value" 213 "IPDThermalWrnngLvl_213__Invalid_Value" 214 "IPDThermalWrnngLvl_214__Invalid_Value" 215 "IPDThermalWrnngLvl_215__Invalid_Value" 216 "IPDThermalWrnngLvl_216__Invalid_Value" 217 "IPDThermalWrnngLvl_217__Invalid_Value" 218 "IPDThermalWrnngLvl_218__Invalid_Value" 219 "IPDThermalWrnngLvl_219__Invalid_Value" 220 "IPDThermalWrnngLvl_220__Invalid_Value" 221 "IPDThermalWrnngLvl_221__Invalid_Value" 222 "IPDThermalWrnngLvl_222__Invalid_Value" 223 "IPDThermalWrnngLvl_223__Invalid_Value" 224 "IPDThermalWrnngLvl_224__Invalid_Value" 225 "IPDThermalWrnngLvl_225__Invalid_Value" 226 "IPDThermalWrnngLvl_226__Invalid_Value" 227 "IPDThermalWrnngLvl_227__Invalid_Value" 228 "IPDThermalWrnngLvl_228__Invalid_Value" 229 "IPDThermalWrnngLvl_229__Invalid_Value" 230 "IPDThermalWrnngLvl_230__Invalid_Value" 231 "IPDThermalWrnngLvl_231__Invalid_Value" 232 "IPDThermalWrnngLvl_232__Invalid_Value" 233 "IPDThermalWrnngLvl_233__Invalid_Value" 234 "IPDThermalWrnngLvl_234__Invalid_Value" 235 "IPDThermalWrnngLvl_235__Invalid_Value" 236 "IPDThermalWrnngLvl_236__Invalid_Value" 237 "IPDThermalWrnngLvl_237__Invalid_Value" 238 "IPDThermalWrnngLvl_238__Invalid_Value" 239 "IPDThermalWrnngLvl_239__Invalid_Value" 240 "IPDThermalWrnngLvl_240__Invalid_Value" 241 "IPDThermalWrnngLvl_241__Invalid_Value" 242 "IPDThermalWrnngLvl_242__Invalid_Value" 243 "IPDThermalWrnngLvl_243__Invalid_Value" 244 "IPDThermalWrnngLvl_244__Invalid_Value" 245 "IPDThermalWrnngLvl_245__Invalid_Value" 246 "IPDThermalWrnngLvl_246__Invalid_Value" 247 "IPDThermalWrnngLvl_247__Invalid_Value" 248 "IPDThermalWrnngLvl_248__Invalid_Value" 249 "IPDThermalWrnngLvl_249__Invalid_Value" 250 "IPDThermalWrnngLvl_250__Invalid_Value" 251 "IPDThermalWrnngLvl_251__Invalid_Value" 252 "IPDThermalWrnngLvl_252__Invalid_Value" 253 "IPDThermalWrnngLvl_253__Invalid_Value" 254 "IPDThermalWrnngLvl_254__Invalid_Value" 255 "IPDThermalWrnngLvl_255__Invalid_Value";
VAL_ 960 IIPDPMICTemp 255 "IPDPMICTemp_255_Invalid_Value";
VAL_ 960 IIPDPCBTemp2 255 "IPDPCBTemp2_255_Invalid_Value";
VAL_ 960 IIPDPCBTemp1 255 "IPDPCBTemp1_255_Invalid_Value";
VAL_ 960 IIPDSOCTemp 255 "IPDOrinTemp_255_Invalid_Value";
VAL_ 1229 ILHRDA_NM_BSMtoRMS_BKPCANFD 0 "LHRDA_NM_BSMtoRMS_BKPCANFD_0_False" 1 "LHRDA_NM_BSMtoRMS_BKPCANFD_1_True";
VAL_ 1229 ILHRDA_NM_PBSMtoRMS_BKPCANFD 0 "LHRDA_NM_PBSMtoRMS_BKPCANFD_0_False" 1 "LHRDA_NM_PBSMtoRMS_BKPCANFD_1_True";
VAL_ 1229 ILHRDA_NM_RMStoNOS_BKPCANFD 0 "LHRDA_NM_RMStoNOS_BKPCANFD_0_False" 1 "LHRDA_NM_RMStoNOS_BKPCANFD_1_True";
VAL_ 1229 ILHRDA_NM_RSStoNOS_BKPCANFD 0 "LHRDA_NM_RSStoNOS_BKPCANFD_0_False" 1 "LHRDA_NM_RSStoNOS_BKPCANFD_1_True";
VAL_ 1229 ILHRDA_NM_RSStoRMS_BKPCANFD 0 "LHRDA_NM_RSStoRMS_BKPCANFD_0_False" 1 "LHRDA_NM_RSStoRMS_BKPCANFD_1_True";
VAL_ 1229 ILHRDA_NM_NOStoRMS_BKPCANFD 0 "LHRDA_NM_NOStoRMS_BKPCANFD_0_False" 1 "LHRDA_NM_NOStoRMS_BKPCANFD_1_True";
VAL_ 1229 ILHRDA_NM_NOSSta_BKPCANFD 0 "LHRDA_NM_NOSSta_BKPCANFD_0_False" 1 "LHRDA_NM_NOSSta_BKPCANFD_1_True";
VAL_ 1229 ILHRDA_NM_RMSSta_BKPCANFD 0 "LHRDA_NM_RMSSta_BKPCANFD_0_False" 1 "LHRDA_NM_RMSSta_BKPCANFD_1_True";
VAL_ 1229 ILHRDA_NWI_BKPCANFD 0 "LHRDA_NWI_BKPCANFD_0_NoWakeNetworkSource";
VAL_ 1229 ILHRDA_NOI_BKPCANFD 0 "LHRDA_NOI_BKPCANFD_0_NoRequest" 65535 "LHRDA_NOI_BKPCANFD_65535_AllNetworkOperationActive";
VAL_ 1229 ILHRDA_NKI_BKPCANFD 0 "LHRDA_NKI_BKPCANFD_0_NoRequest";
VAL_ 181 IDircnLghtOnReq_LHZCU 0 "DircnLghtOnReq_LHZCU_0_Off" 1 "DircnLghtOnReq_LHZCU_1_Left_direction_light_on" 2 "DircnLghtOnReq_LHZCU_2_Right_direction_light_on" 3 "DircnLghtOnReq_LHZCU_3_Both_left_and_right_direction_light_on";
VAL_ 1149 ITPMSAutoLoctnCm 0 "TPMSAutoLoctnCm_0_False" 1 "TPMSAutoLoctnCm_1_True";
VAL_ 1149 IFRTireSts 0 "FRTireSts_0_Normal" 1 "FRTireSts_1_Unkown" 2 "FRTireSts_2_Pressure_Low" 3 "FRTireSts_3_Quick_leak" 4 "FRTireSts_4_Pressure_High" 5 "FRTireSts_5_Temperature_High" 6 "FRTireSts_6_Axle_Pressure_imbalance" 7 "FRTireSts_7_Battery_Low";
VAL_ 1149 IFLTireSts 0 "FLTireSts_0_Normal" 1 "FLTireSts_1_Unkown" 2 "FLTireSts_2_Pressure_Low" 3 "FLTireSts_3_Quick_leak" 4 "FLTireSts_4_Pressure_High" 5 "FLTireSts_5_Temperature_High" 6 "FLTireSts_6_Axle_Pressure_imbalance" 7 "FLTireSts_7_Battery_Low";
VAL_ 1149 ITPMSIdficnLrnCm 0 "TPMSIdficnLrnCm_0_False" 1 "TPMSIdficnLrnCm_1_True";
VAL_ 1149 IRRTireSts 0 "RRTireSts_0_Normal" 1 "RRTireSts_1_Unkown" 2 "RRTireSts_2_Pressure_Low" 3 "RRTireSts_3_Quick_leak" 4 "RRTireSts_4_Pressure_High" 5 "RRTireSts_5_Temperature_High" 6 "RRTireSts_6_Axle_Pressure_imbalance" 7 "RRTireSts_7_Battery_Low";
VAL_ 1149 IRLTireSts 0 "RLTireSts_0_Normal" 1 "RLTireSts_1_Unkown" 2 "RLTireSts_2_Pressure_Low" 3 "RLTireSts_3_Quick_leak" 4 "RLTireSts_4_Pressure_High" 5 "RLTireSts_5_Temperature_High" 6 "RLTireSts_6_Axle_Pressure_imbalance" 7 "RLTireSts_7_Battery_Low";
VAL_ 1149 ITPMSWntrMdA 0 "TPMSWntrMdA_0_False" 1 "TPMSWntrMdA_1_True";
VAL_ 1149 IRLTirePrsV 0 "RLTirePrsV_0_Valid" 1 "RLTirePrsV_1_Invalid";
VAL_ 1149 IFRTirePrsV 0 "FRTirePrsV_0_Valid" 1 "FRTirePrsV_1_Invalid";
VAL_ 1149 IRRTirePrsV 0 "RRTirePrsV_0_Valid" 1 "RRTirePrsV_1_Invalid";
VAL_ 1149 IFLTirePrsV 0 "FLTirePrsV_0_Valid" 1 "FLTirePrsV_1_Invalid";
VAL_ 638 IVehIlluminateCtrlCmd 0 "VehIlluminateCtrlCmd_0_Close" 1 "VehIlluminateCtrlCmd_1_Open";
VAL_ 638 IBrkLghtSta 0 "BrkLghtSta_0_Off" 1 "BrkLghtSta_1_On";
VAL_ 638 IBrkLghtFltSta 0 "BrkLghtFltSta_0_False" 1 "BrkLghtFltSta_1_True";
VAL_ 638 IDircnLghtSts 0 "DircnLghtSts_0_OFF" 1 "DircnLghtSts_1_Left_Direction_Light_On" 2 "DircnLghtSts_2_Right_Direction_Light_On" 3 "DircnLghtSts_3_Both_Side_Direction_Light_On" 4 "DircnLghtSts_4_Reserved";
VAL_ 638 IDircnLghtMdSts 0 "DircnLghtMdSts_0__Enabled" 1 "DircnLghtMdSts_1__Disabled";
VAL_ 638 IRevsLghtFltSta 0 "RevsLghtFltSta_0_False" 1 "RevsLghtFltSta_1_True";
VAL_ 638 IRevsLghtSta 0 "RevsLghtSta_0_off" 1 "RevsLghtSta_1_on";
VAL_ 638 IRearFogLghtAcFltsts 0 "RearFogLghtAcFltsts_0_False" 1 "RearFogLghtAcFltsts_1_True";
VAL_ 638 IRearFogLghtAcSts 0 "RearFogLghtAcSts_0_Off" 1 "RearFogLghtAcSts_1_On";
VAL_ 638 IRearFogLghtCtrl 0 "RearFogLghtCtrl_0_Off" 1 "RearFogLghtCtrl_1_On";
VAL_ 638 ISideLghtFltsts 0 "SideLghtFltsts_0_False" 1 "SideLghtFltsts_1_True";
VAL_ 638 IRRSideLghtCtrl 0 "RRSideLghtCtrl_0_Off" 1 "RRSideLghtCtrl_1_On";
VAL_ 638 IRLSideLghtCtrl 0 "RLSideLghtCtrl_0_Off" 1 "RLSideLghtCtrl_1_On";
VAL_ 638 IHdlmpLvlngFltSts 0 "HdlmpLvlngFltSts_0_False" 1 "HdlmpLvlngFltSts_1_True";
VAL_ 638 IHdlmpLvlngCrtl 0 "HdlmpLvlngCrtl_0_NoRequest" 1 "HdlmpLvlngCrtl_1_Leveling1" 2 "HdlmpLvlngCrtl_2_Leveling2" 3 "HdlmpLvlngCrtl_3_Leveling3" 4 "HdlmpLvlngCrtl_4_Leveling4" 5 "HdlmpLvlngCrtl_5_Reserved";
VAL_ 638 IDayTmRunngLghtFltsts 0 "DayTmRunngLghtFltsts_0_False" 1 "DayTmRunngLghtFltsts_1_True";
VAL_ 638 IDayTmRunngLghtSts 0 "DayTmRunngLghtSts_0_off" 1 "DayTmRunngLghtSts_1_on";
VAL_ 638 IFrtFogLghtSts 0 "FrtFogLghtSts_0_Off" 1 "FrtFogLghtSts_1_On";
VAL_ 638 IRFrtFogLghtCtrl 0 "RFrtFogLghtCtrl_0_Off" 1 "RFrtFogLghtCtrl_1_On";
VAL_ 638 ILFrtFogLghtCtrl 0 "LFrtFogLghtCtrl_0_Off" 1 "LFrtFogLghtCtrl_1_On";
VAL_ 638 IHdlmpLvlngSts 0 "HdlmpLvlngSts_0_NoRequest" 1 "HdlmpLvlngSts_1_Leveling1" 2 "HdlmpLvlngSts_2_Leveling2" 3 "HdlmpLvlngSts_3_Leveling3" 4 "HdlmpLvlngSts_4_Leveling4" 5 "HdlmpLvlngSts_5_Reserved";
VAL_ 638 IDircnLghtSwReq 0 "DircnLghtSwReq_0_Off" 1 "DircnLghtSwReq_1_Left_First_gear_direction_light_on" 2 "DircnLghtSwReq_2_Left_Second_gear_direction_light_on" 3 "DircnLghtSwReq_3_Right_First_gear_direction_light_on" 4 "DircnLghtSwReq_4_Right_Second_gear_direction_light_on";
VAL_ 638 IFrtFogLghtFltSts 0 "FrtFogLghtFltSts_0_False" 1 "FrtFogLghtFltSts_1_True";
VAL_ 638 IDircnLghtFltsts 0 "DircnLghtFltsts_0_No_Error" 1 "DircnLghtFltsts_1_Left_Direction_Light_Error" 2 "DircnLghtFltsts_2_Right_Direction_Light_Error" 3 "DircnLghtFltsts_3_Both_Side_Direction_Light_Error";
VAL_ 745 IAutoMainBeamLghtOn 0 "AutoMainBeamLghtOn_0_Off" 1 "AutoMainBeamLghtOn_1_On";
VAL_ 745 IMainBeamLghtOn 0 "MainBeamLghtOnReq_0_Off" 1 "MainBeamLghtOnReq_1_On";
VAL_ 745 IRLDoorLckSts 0 "RLDoorLckSts_0_Locked" 1 "RLDoorLckSts_1_Unlock" 2 "RLDoorLckSts_2_Error";
VAL_ 745 IComfortDircnLghtDsp 0 "ComfortDircnLghtDsp_0_FunctionDisable" 1 "ComfortDircnLghtDsp_1_Unavailable" 2 "ComfortDircnLghtDsp_2_OFF" 3 "ComfortDircnLghtDsp_3_ON";
VAL_ 745 IDircnLghtMdDsp 0 "DircnLghtMdDsp_0_FunctionDisable" 1 "DircnLghtMdDsp_1_Unavailable" 2 "DircnLghtMdDsp_2_OFF" 3 "DircnLghtMdDsp_3_ON";
VAL_ 745 IAllWndAndSrfLazyClsReq 0 "AllWndAndSrfLazyClsReq_l_0_False" 1 "AllWndAndSrfLazyClsReq_l_1_True";
VAL_ 745 IRrSrvcPosReq 0 "RrSrvcPosReq_0_No_Request" 1 "RrSrvcPosReq_1_Service_position";
VAL_ 745 IRrWiperFnEnb 0 "RrWiperFnEnb_0_Disable" 1 "RrWiperFnEnb_1_Enable";
VAL_ 1150 ITPMSF 0 "TPMSF_0_False" 1 "TPMSF_1_True";
VAL_ 1150 ITPMSTirePrsLowIO 0 "TPMSTirePrsLowIO_0_False" 1 "TPMSTirePrsLowIO_1_True";
VAL_ 784 IVehLckTypResp 0 "VehLckTypResp_0_No_Request" 1 "VehLckTypResp_1_Digital_Key_Exetrior_Lock_Request" 2 "VehLckTypResp_2_Digital_Key_Unlock_Request" 3 "VehLckTypResp_3_Comfortable_Exterior_Lock_Request" 4 "VehLckTypResp_4_Comfortable_Unlock_Request" 5 "VehLckTypResp_5_NFC_Exterior_Lock_Request" 6 "VehLckTypResp_6_NFC_UnLock_Request" 7 "VehLckTypResp_7_PE_Exterior_Lock_Request" 8 "VehLckTypResp_8_PE_Unlock_Request" 9 "VehLckTypResp_9_Mechanical_Exterior_Lock_Request" 10 "VehLckTypResp_10_Mechanical_Unlock_Request" 11 "VehLckTypResp_11_Automatic_Lock_Request" 12 "VehLckTypResp_12_Centre_Lock_Switch_Interior_Lock_Request" 13 "VehLckTypResp_13_Centre_Lock_Switch_Unlock_Request" 14 "VehLckTypResp_14_Vehicle_Speed_Interior_Lock_Request" 15 "VehLckTypResp_15_Crash_Unlock_Request" 16 "VehLckTypResp_16_Thermal_Unlock_Request" 17 "VehLckTypResp_17_Anti_Unlock_Request" 18 "VehLckTypResp_18_Door_Open_Unlock_Request" 19 "VehLckTypResp_19_Brake_Pedal_Request" 20 "VehLckTypResp_20_Transmission_Shift_Switch_Unlock_Request" 21 "VehLckTypResp_21_Ignite_Unlock_Request" 22 "VehLckTypResp_22_SOA_Exterior_Lock_Request" 23 "VehLckTypResp_23_SOA_Exterior_Unlock_Request" 24 "VehLckTypResp_24_SOA_Interior_Lock_Request" 25 "VehLckTypResp_25_SOA_Interior_Unlock_Request" 31 "VehLckTypResp_127_Reserved";
VAL_ 784 IVehLckActnFailRsn 0 "VehLckActnFailRsn_0_Default" 1 "VehLckActnFailRsn_1_VehMd_or_VehMdV_not_Satisfied" 2 "VehLckActnFailRsn_2_UsgMd_or_UsgMdV_not_Satisfied" 3 "VehLckActnFailRsn_3_Driver_Door_Open" 4 "VehLckActnFailRsn_4_Vehicle_Speed_not_Satisfied" 5 "VehLckActnFailRsn_5_Transmisson_Shift_Lever_not_Satisfied" 6 "VehLckActnFailRsn_6_Driver_Seat_Present" 7 "VehLckActnFailRsn_7_Smart_Key_Position_not_Satisfied" 8 "VehLckActnFailRsn_8_Lock_Motor_Fault" 9 "VehLckActnFailRsn_9_Any_Door_Open" 10 "VehLckActnFailRsn_10_System_Limit" 11 "VehLckActnFailRsn_11_Vehicle_Lock_Status_Limit" 12 "VehLckActnFailRsn_12_Config_not_Satisfied" 13 "VehLckActnFailRsn_13_Priority_not_Satisfied" 14 "VehLckActnFailRsn_14_Reserved" 15 "VehLckActnFailRsn_15_NoFailed";
VAL_ 784 IRLWinShrtDwnSucd 0 "RLWinShrtDwnSucd_0_failed" 1 "RLWinShrtDwnSucd_1_succeed";
VAL_ 784 IFLWinShrtDwnSucd 0 "FLWinShrtDwnSucd_0_failed" 1 "FLWinShrtDwnSucd_1_succeed";
VAL_ 784 ILOtsdMirFoldSts 0 "LOtsdMirFoldSts_0_Initial" 1 "LOtsdMirFoldSts_1_Folded" 2 "LOtsdMirFoldSts_2_Unfolded" 3 "LOtsdMirFoldSts_3_Folding" 4 "LOtsdMirFoldSts_4_Unfolding" 5 "LOtsdMirFoldSts_5_Failure";
VAL_ 784 IHtdFrtLftVwWndFaltSts 0 "HtdFrtLftVwWndFaltSts_0_Normal" 1 "HtdFrtLftVwWndFaltSts_1_Open" 2 "HtdFrtLftVwWndFaltSts_2_Short" 3 "HtdFrtLftVwWndFaltSts_3_Over_Temp" 4 "HtdFrtLftVwWndFaltSts_4_Other_Fault";
VAL_ 784 IRLWinMotSts 0 "RLWinMotSts_0_still" 1 "RLWinMotSts_1_up" 2 "RLWinMotSts_2_down" 3 "RLWinMotSts_3_auto_up" 4 "RLWinMotSts_4_auto_down" 5 "RLWinMotSts_5_aeration" 6 "RLWinMotSts_6_frameless_short_drive_up" 7 "RLWinMotSts_7_frameless_short_drive_down" 8 "RLWinMotSts_8_Anti_pinch_auto_reverse" 9 "RLWinMotSts_9_Stall" 10 "RLWinMotSts_10_Anti_pinch_Override" 11 "RLWinMotSts_11_AutoriseAtDoorOpen";
VAL_ 784 IRLWinLclSwtSts 0 "RLWinLclSwtSts_0_no_request" 1 "RLWinLclSwtSts_1_up_request" 2 "RLWinLclSwtSts_2_down_request" 3 "RLWinLclSwtSts_3_auto_up_request" 4 "RLWinLclSwtSts_4_auto_down_request";
VAL_ 784 ILckSysStsIndcn 0 "LckSysStsIndcn_0_OFF" 1 "LckSysStsIndcn_1_ON" 2 "LckSysStsIndcn_2_Flash";
VAL_ 784 IFLWinMotSts 0 "FLWinMotSts_0_still" 1 "FLWinMotSts_1_up" 2 "FLWinMotSts_2_down" 3 "FLWinMotSts_3_auto_up" 4 "FLWinMotSts_4_auto_down" 5 "FLWinMotSts_5_aeration" 6 "FLWinMotSts_6_frameless_short_drive_up" 7 "FLWinMotSts_7_frameless_short_drive_down" 8 "FLWinMotSts_8_Anti_pinch_auto_reverse" 9 "FLWinMotSts_9_Stall" 10 "FLWinMotSts_10_Anti_pinch_Override" 11 "FLWinMotSts_11_AutoriseAtDoorOpen";
VAL_ 784 IFLDoorLckSts 0 "FLDoorLckSts_0_Locked" 1 "FLDoorLckSts_1_Unlock" 2 "FLDoorLckSts_2_Error";
VAL_ 800 IRrWinInhbSwtSts 0 "RrWinInhbSwtSts_0_no_press" 1 "RrWinInhbSwtSts_1_press";
VAL_ 800 IRrWinInhbSwtFlt 0 "RrWinInhbSwtFlt_0_no_error" 1 "RrWinInhbSwtFlt_1_error";
VAL_ 800 IBCMOdoReq 0 "BCMOdoReq_0_NoRequest" 1 "BCMOdoReq_1_Request";
VAL_ 800 IDircnIndLampSwStsMntry 0 "DircnIndLampSwStsMntry_0_off" 1 "DircnIndLampSwStsMntry_1_LeftshortturnmodeSwitchactive" 2 "DircnIndLampSwStsMntry_2_LeftlongturnmodeSwitchactive" 3 "DircnIndLampSwStsMntry_3_RightShortTurnModeSwitchActive" 4 "DircnIndLampSwStsMntry_4_RightLongTurnModeSwitchActive" 5 "DircnIndLampSwStsMntry_5_UnknowPosition" 6 "DircnIndLampSwStsMntry_6_reserve" 7 "DircnIndLampSwStsMntry_7_reserve";
VAL_ 800 IImmoSubModTCAuthnRunSts 0 "ImmoSubModTCAuthnRunSts_0_NotStartImmo" 1 "ImmoSubModTCAuthnRunSts_1_ImmoRunning" 2 "ImmoSubModTCAuthnRunSts_2_ImmoResponseSucess" 3 "ImmoSubModTCAuthnRunSts_3_ImmoAttack" 4 "ImmoSubModTCAuthnRunSts_4_ImmoNoChallenge" 5 "ImmoSubModTCAuthnRunSts_5_ImmoErrorChallenge" 6 "ImmoSubModTCAuthnRunSts_6_ImmoNoCipher" 7 "ImmoSubModTCAuthnRunSts_7_Reserved";
VAL_ 800 IImmoSubModSACAuthnRunSts 0 "ImmoSubModSACAuthnRunSts_0_NotStartImmo" 1 "ImmoSubModSACAuthnRunSts_1_ImmoRunning" 2 "ImmoSubModSACAuthnRunSts_2_ImmoResponseSucess" 3 "ImmoSubModSACAuthnRunSts_3_ImmoAttack" 4 "ImmoSubModSACAuthnRunSts_4_ImmoNoChallenge" 5 "ImmoSubModSACAuthnRunSts_5_ImmoErrorChallenge" 6 "ImmoSubModSACAuthnRunSts_6_ImmoNoCipher" 7 "ImmoSubModSACAuthnRunSts_7_Reserved";
VAL_ 800 IMainBeamSwPosSts 0 "MainBeamSwPosSts_0_Off" 1 "MainBeamSwPosSts_1_MainBeamFlash" 2 "MainBeamSwPosSts_2_MainBeamOn" 3 "MainBeamSwPosSts_3_Reserved";
VAL_ 800 IEDRDircnIndLampSwSts 0 "EDRDircnIndLampSwSts_0_off" 1 "EDRDircnIndLampSwSts_1_Left" 2 "EDRDircnIndLampSwSts_2_right" 3 "EDRDircnIndLampSwSts_3_hazard";
VAL_ 800 IRFKeyAuthnChrgInhbtReq 0 "EqualsRFKeyAuthnChrgInhbtReq_0_NoRequest" 1 "EqualsRFKeyAuthnChrgInhbtReq_1_Request";
VAL_ 905 ISmtKeyAuthnMnModRunSts 0 "SmtKeyAuthnMnModRunSts_0_Initialization" 1 "SmtKeyAuthnMnModRunSts_1_Running" 2 "SmtKeyAuthnMnModRunSts_2_Pass" 3 "SmtKeyAuthnMnModRunSts_3_Failure_Attack" 4 "SmtKeyAuthnMnModRunSts_4_Failure_NoResponse" 5 "SmtKeyAuthnMnModRunSts_5_Failure_NoCipher" 6 "SmtKeyAuthnMnModRunSts_6_Reserved" 7 "SmtKeyAuthnMnModRunSts_7_Reserved";
VAL_ 905 IHtdFrtLftVwWndActSts 0 "HtdFrtLftVwWndActSts_0_Off" 1 "HtdFrtLftVwWndActSts_1_On";
VAL_ 905 ILOtsdMirActSts 0 "LOtsdMirActSts_0_No_Action" 1 "LOtsdMirActSts_1_Tilt_X" 2 "LOtsdMirActSts_2_Tilt_Y" 3 "LOtsdMirActSts_3_Fold_Unfold" 4 "LOtsdMirActSts_4_Recall";
VAL_ 905 IFrtWindShldSurndHmdty 255 "FrtWindShldSurndHmdty_255_Error";
VAL_ 905 IFrtWindShldSurndTem 255 "FrtWindShldSurndTem_255_Error";
VAL_ 905 IFrtWindShldSfcTem 2047 "FrtWindShldSfcTem_2047_Error";
VAL_ 905 ISolarStrngLSideV 0 "SolarStrngLSideV_0_Valid" 1 "SolarStrngLSideV_1_Invalid";
VAL_ 905 ISolarStrngRSideV 0 "SolarStrngRSideV_0_Valid" 1 "SolarStrngRSideV_1_Invalid";
VAL_ 905 IDKBLERst 0 "DKBLERst_0_No_Request" 1 "DKBLERst_1_Request";
VAL_ 905 IFrtWiperSpd 0 "FrtWiperSpd_0_NoRequest" 1 "FrtWiperSpd_1_LowSpeedWipe" 2 "FrtWiperSpd_2_HighSpeedWipe" 3 "FrtWiperSpd_3_reserved";
VAL_ 783 IWlcmReq 0 "WlcmReq_0_NoRuqest" 1 "WlcmReq_1_DayRuquest" 2 "WlcmReq_2_NigtRequest" 3 "WlcmReq_3_Reserve";
VAL_ 783 IFllwMeReq 0 "FllwMeReq_0_NoRuqest" 1 "FllwMeReq_1_DayRuquest" 2 "FllwMeReq_2_NigtRequest" 3 "FllwMeReq_3_Reserve";
VAL_ 783 IKickSnsrDetnEnb 0 "KickSnsrDetnEnb_0_OFF" 1 "KickSnsrDetnEnb_1_ON";
VAL_ 783 IKickSnsrDfct 0 "KickSnsrDfct_0_Normal" 1 "KickSnsrDfct_1_Fault";
VAL_ 783 IKickSnsrEleDfct 0 "KickSnsrEleDfct_0_Normal" 1 "KickSnsrEleDfct_1_Fault";
VAL_ 783 IKickSnsrPlayProtn 0 "KickSnsrPlayProtn_0_OFF" 1 "KickSnsrPlayProtn_1_ON";
VAL_ 783 IKickSnsrSts 0 "KickSnsrSts_0_NotActive" 1 "KickSnsrSts_1_Actived";
VAL_ 783 IFrwlLghtReq_LHZCU 0 "FrwlLghtReq_LHZCU_0_false" 1 "FrwlLghtReq_LHZCU_1_true";
VAL_ 783 IWlcmLghtReq_LHZCU 0 "WlcmLghtReq_LHZCU_0_false" 1 "WlcmLghtReq_LHZCU_1_true";
VAL_ 783 IFLDoorOpenSts 0 "FLDoorOpenSts_0_Closed" 1 "FLDoorOpenSts_1_CantDetectDoorAjarStatus" 2 "FLDoorOpenSts_2_Ajar" 3 "FLDoorOpenSts_3_Open";
VAL_ 783 IHUDLghtSnsrHdwrFltPrst 0 "HUDLghtSnsrHdwrFltPrst_l_0_False" 1 "HUDLghtSnsrHdwrFltPrst_l_1_True";
VAL_ 783 IHUDFwdLkngAmbtLghtLvl 16383 "HUDFwdLkngAmbtLghtLvl_16383_Invalid";
VAL_ 783 IFollowMeHomeReq_LHZCU 0 "FollowMeHomeReq_LHZCU_0_false" 1 "FollowMeHomeReq_LHZCU_1_true";
VAL_ 783 IBklghtReq 0 "BklghtReq_0_false" 1 "BklghtReq_1_true";
VAL_ 783 IHUDRLSAmbtLghtLvl 4095 "HUDRLSAmbtLghtLvl_4095_Invalid";
VAL_ 783 IHmdtySnsrHdwrFltPrst 0 "HmdtySnsrHdwrFltPrst_0_False" 1 "HmdtySnsrHdwrFltPrst_1_True";
VAL_ 783 IFrtPsngDoorOpenSts_LHZCU 0 "FrtPsngDoorOpenSts_LHZCU_0_Closed" 1 "FrtPsngDoorOpenSts_LHZCU_1_CantDetectDoorAjarStatus" 2 "FrtPsngDoorOpenSts_LHZCU_2_Ajar" 3 "FrtPsngDoorOpenSts_LHZCU_3_Open";
VAL_ 896 IFrtWiperSwSts 0 "FrtWiperSwSts_0_wipers_Off" 1 "FrtWiperSwSts_1_wipers_in_intermittent_mode" 2 "FrtWiperSwSts_2_wipers_in_slow_mode" 3 "FrtWiperSwSts_3_wipers_in_fast_mode";
VAL_ 896 IFrtWshrPumpA 0 "FrtWshrPumpA_0_False" 1 "FrtWshrPumpA_1_True";
VAL_ 896 IFrtWiperOpReq 0 "FrtWiperOpReq_0_wiper_off" 1 "FrtWiperOpReq_1_slow_speed_wipe_single" 2 "FrtWiperOpReq_2_slow_speed_wipe_continuous" 3 "FrtWiperOpReq_3_fast_speed_wipe" 4 "FrtWiperOpReq_4_fault_mode";
VAL_ 299 IRevsLghtCtrl 0 "RevsLghtCtrl_0_Off" 1 "RevsLghtCtrl_1_On";
VAL_ 299 IRRDircnLghtCtrl 0 "RRDircnLghtCtrl_0_Off" 1 "RRDircnLghtCtrl_1_on";
VAL_ 299 IRLDircnLghtCtrl 0 "RLDircnLghtCtrl_0_Off" 1 "RLDircnLghtCtrl_1_on";
VAL_ 299 IFRDircnLghtCtrl 0 "FRDircnLghtCtrl_0_Off" 1 "FRDircnLghtCtrl_1_on";
VAL_ 299 IFLDircnLghtCtrl 0 "FLDircnLghtCtrl_0_Off" 1 "FLDircnLghtCtrl_1_on";
VAL_ 299 IBrkLghtCtrl 0 "BrkLghtCtrl_0_Off" 1 "BrkLghtCtrl_1_On";
VAL_ 299 IHzrdLghtSwReq 0 "HzrdLghtSwReq_0_Off" 1 "HzrdLghtSwReq_1_On";
VAL_ 566 IFindCarFuncInfoDsp 0 "FindCarFuncInfoDsp_0_DIsable" 1 "FindCarFuncInfoDsp_1_Light_Horn_Enable" 2 "FindCarFuncInfoDsp_2_Light_Enable" 3 "FindCarFuncInfoDsp_3_Horn_Enable";
VAL_ 566 IDipdBeamLghtFltsts 0 "DipdBeamLghtFltsts_0_False" 1 "DipdBeamLghtFltsts_1_True";
VAL_ 566 IFLDoorHndlPESwtActv 0 "FLDoorHndlPESwtActv_0_NoPress" 1 "FLDoorHndlPESwtActv_1_ShortPress" 2 "FLDoorHndlPESwtActv_2_LongPress" 3 "FLDoorHndlPESwtActv_3_ActivePress";
VAL_ 566 IFRDoorHndlPESwtActv 0 "FRDoorHndlPESwtActv_0_NoPress" 1 "FRDoorHndlPESwtActv_1_ShortPress" 2 "FRDoorHndlPESwtActv_2_LongPress" 3 "FRDoorHndlPESwtActv_3_ActivePress";
VAL_ 566 IMainBeamLghtMdSts 0 "MainBeamLghtMdSts_0_No_Request" 1 "MainBeamLghtMdSts_1_Manual_Mode" 2 "MainBeamLghtMdSts_2_Auto_Mode" 3 "MainBeamLghtMdSts_3_Reserved_01";
VAL_ 566 IVehHzrdMdSts 0 "VehHzrdMdSts_0_No_Request" 1 "VehHzrdMdSts_1_Manual_Mode" 2 "VehHzrdMdSts_2_Collision_Mode" 3 "VehHzrdMdSts_3_SHWA_Mode" 4 "VehHzrdMdSts_4_RCW_Mode" 5 "VehHzrdMdSts_5_AI_Pilot_Warning_Mode" 6 "VehHzrdMdSts_6_Battery_Thermal_Malfunction" 7 "VehHzrdMdSts_7_Emergency_Brake" 8 "VehHzrdMdSts_8_Alarm_trigger" 9 "VehHzrdMdSts_9_Find_my_car" 10 "VehHzrdMdSts_10_ExtrLckLghtRmndr" 11 "VehHzrdMdSts_11_PwrLftgtDirIndcnLamp";
VAL_ 566 IHzrdLghtSwSts 0 "HzrdLghtSwSts_0_off" 1 "HzrdLghtSwSts_1_On";
VAL_ 566 IBrkLghtSwStsV 0 "BrkLghtSwStsV_0_Valid" 1 "BrkLghtSwStsV_1_Invalid";
VAL_ 566 IBrkLghtSwSts 0 "BrkLghtSwSts_0_Off" 1 "BrkLghtSwSts_1_On";
VAL_ 566 IRrWiperReq 0 "RrWiperReq_0_No_Request" 1 "RrWiperReq_1_Request";
VAL_ 566 IMainBeamLghtFltSts 0 "MainBeamLghtFltSts_0__False" 1 "MainBeamLghtFltSts_1__True";
VAL_ 566 IMainBeamLghtSts 0 "MainBeamLghtSts_0_Off" 1 "MainBeamLghtSts_1_On";
VAL_ 566 IMainBeamLghtSwSts 0 "MainBeamLghtSwSts_0_Off" 1 "MainBeamLghtSwSts_1_On" 2 "MainBeamLghtSwSts_2_Flash";
VAL_ 566 IDircnIndLghtSwSts 0 "DircnIndLghtSwSts_0_Off" 1 "DircnIndLghtSwSts_1_LeftOn" 2 "DircnIndLghtSwSts_2_RightOn" 3 "DircnIndLghtSwSts_3_reserve";
VAL_ 566 ILdspcRlseSwtActv 0 "LdspcRlseSwtActv_0_Inactive" 1 "LdspcRlseSwtActv_1_Active";
VAL_ 566 IRRWinDrvrSwtSts 0 "RRWinDrvrSwtSts_0_no_request" 1 "RRWinDrvrSwtSts_1_up_request" 2 "RRWinDrvrSwtSts_2_down_request" 3 "RRWinDrvrSwtSts_3_auto_up_request" 4 "RRWinDrvrSwtSts_4_auto_down_request";
VAL_ 566 ILckCtrlResp 0 "LckCtrlResp_0_NoRequest" 1 "LckCtrlResp_1_Approved" 2 "LckCtrlResp_2_PowerModeisnotOFF" 3 "LckCtrlResp_3_AnyDoorisOpen" 4 "LckCtrlResp_4_VehicleisnotinExternalLock" 5 "LckCtrlResp_5_LockSystemisFault" 6 "LckCtrlResp_6_VehicleisMoving" 7 "LckCtrlResp_7_AuthenticationFailure" 8 "LckCtrlResp_8_OtherReason" 9 "LckCtrlResp_9_FeatureisTimeout" 10 "LckCtrlResp_10_Featureisnotsupported";
VAL_ 566 IRLWinDrvrSwtSts 0 "RLWinDrvrSwtSts_0_no_request" 1 "RLWinDrvrSwtSts_1_up_request" 2 "RLWinDrvrSwtSts_2_down_request" 3 "RLWinDrvrSwtSts_3_auto_up_request" 4 "RLWinDrvrSwtSts_4_auto_down_request";
VAL_ 566 IFRWinDrvrSwtSts 0 "FRWinDrvrSwtSts_0_no_request" 1 "FRWinDrvrSwtSts_1_up_request" 2 "FRWinDrvrSwtSts_2_down_request" 3 "FRWinDrvrSwtSts_3_auto_up_request" 4 "FRWinDrvrSwtSts_4_auto_down_request";
VAL_ 566 IDipdBeamLghtSts 0 "DipdBeamLghtSts_0_Off" 1 "DipdBeamLghtSts_1_On";
VAL_ 566 IBrkPdlTrigd 0 "BrkPdlTrigd_0_False" 1 "BrkPdlTrigd_1_True";
VAL_ 566 IFLWinLclSwtSts 0 "FLWinLclSwtSts_0_no_request" 1 "FLWinLclSwtSts_1_up_request" 2 "FLWinLclSwtSts_2_down_request" 3 "FLWinLclSwtSts_3_auto_up_request" 4 "FLWinLclSwtSts_4_auto_down_request";
VAL_ 566 IExtrLckActnIndcn 0 "ExtrLckActnIndcn_0_NoAction" 1 "ExtrLckActnIndcn_1_LockAction" 2 "ExtrLckActnIndcn_2_UnLockAction" 3 "ExtrLckActnIndcn_3_Reserved" 4 "ExtrLckActnIndcn_4_Reserved" 5 "ExtrLckActnIndcn_5_Reserved" 6 "ExtrLckActnIndcn_6_Reserved" 7 "ExtrLckActnIndcn_7_Reserved";
VAL_ 566 IAutoMainBeamLghtSts 0 "AutoMainBeamLghtSts_0_Auto_Main_Beam_OFF_and_Main_Beam_OFF" 1 "AutoMainBeamLghtSts_1_Auto_Main_Beam_OFF_and_Main_Beam_ON" 2 "AutoMainBeamLghtSts_2_Auto_Main_Beam_On_and_Main_Beam_OFF" 3 "AutoMainBeamLghtSts_3_Auto_Main_Beam_On_and_Main_Beam_ON";
VAL_ 566 IDrvrDetSnsrFltSts 0 "DrvrDetSnsrFltSts_0_NoFault" 1 "DrvrDetSnsrFltSts_1_ShortToGnd" 2 "DrvrDetSnsrFltSts_2_ShortToBattery" 3 "DrvrDetSnsrFltSts_3_OpenCircuit";
VAL_ 566 IDircnIndLghtMdSts 0 "DircnIndLghtMdSts_0_off" 1 "DircnIndLghtMdSts_1_Left_First_gear_On" 2 "DircnIndLghtMdSts_2_Left_Second_gear_On" 3 "DircnIndLghtMdSts_3_Right_First_gear_On" 4 "DircnIndLghtMdSts_4_Right_Second_gear_On" 5 "DircnIndLghtMdSts_5_reserve";
VAL_ 653 IAutoLghtOnReq 0 "AutoLghtOnReq_0_False" 1 "AutoLghtOnReq_1_True";
VAL_ 653 IExtrTrunkCtrlReq 0 "ExtrTrunkCtrlReq__0_NoRequest" 1 "ExtrTrunkCtrlReq__1_OpenRequest" 2 "ExtrTrunkCtrlReq__2_CloseRequest" 3 "ExtrTrunkCtrlReq__3_ControlRequest" 4 "ExtrTrunkCtrlReq__4_StopRequest" 5 "ExtrTrunkCtrlReq__5_UnlockRequest" 6 "ExtrTrunkCtrlReq__6_Reserved" 7 "ExtrTrunkCtrlReq__7_Reserved";
VAL_ 653 IDoorLckCtrlReq 0 "DoorLckCtrlReq_0_NoRequest" 1 "DoorLckCtrlReq_1_LockRequest" 2 "DoorLckCtrlReq_2_SuperLockRequest" 3 "DoorLckCtrlReq_3_UnlockRequest" 4 "DoorLckCtrlReq_4_SPEUnlockRequest";
VAL_ 653 ILghtSnsrHdwrFltPrst 0 "LghtSnsrHdwrFltPrst_0_False" 1 "LghtSnsrHdwrFltPrst_1_True";
VAL_ 653 IExtrTrunkCtrlSrcReq 0 "ExtrTrunkCtrlSrcReq__0_NoValidSource" 1 "ExtrTrunkCtrlSrcReq__1_DKMMRequest" 2 "ExtrTrunkCtrlSrcReq__2_LdspcSwtReq" 3 "ExtrTrunkCtrlSrcReq__3_KickSensor" 4 "ExtrTrunkCtrlSrcReq__4_PhoneAPP" 5 "ExtrTrunkCtrlSrcReq__5_InnerSwt" 6 "ExtrTrunkCtrlSrcReq__6_Reserved" 7 "ExtrTrunkCtrlSrcReq__7_Reserved";
VAL_ 653 ILghtSwPosSts 0 "LghtSwPosSts_0_Switch_is_on_Off_position" 1 "LghtSwPosSts_1_Switch_is_on_Auto_position" 2 "LghtSwPosSts_2_Side_Lamp" 3 "LghtSwPosSts_3_Dipped_Beam" 4 "LghtSwPosSts_4_Unknow_position" 5 "LghtSwPosSts_5_reserved" 6 "LghtSwPosSts_6_reserved" 7 "LghtSwPosSts_7_reserved";
VAL_ 652 IDrvrDetSts 0 "DrvrDetSts_0_NoDriverPresent" 1 "DrvrDetSts_1_DriverPresent" 2 "DrvrDetSts_2_SensorFault";
VAL_ 652 IRLDoorOpenSts 0 "RLDoorOpenSts_0_Closed" 1 "RLDoorOpenSts_1_CantDetectDoorAjarStatus" 2 "RLDoorOpenSts_2_Ajar" 3 "RLDoorOpenSts_3_Open";
VAL_ 652 IDrvrDoorOpenSts 0 "DrvrDoorOpenSts_0_Closed" 1 "DrvrDoorOpenSts_1_CantDetectDoorAjarStatus" 2 "DrvrDoorOpenSts_2_Ajar" 3 "DrvrDoorOpenSts_3_Open";
VAL_ 652 IBntOpenSts 0 "BntOpenSts_0_BonnetClosed" 1 "BntOpenSts_1_BonnetOpen" 2 "BntOpenSts_2_BonnetSwitchDisconnect" 3 "BntOpenSts_3_Reserved";
VAL_ 652 IVehLckSts 0 "VehLckSts_0_Unlocked" 1 "VehLckSts_1_SignalPositionEntryUnlocked" 2 "VehLckSts_2_InteriorLocked" 3 "VehLckSts_3_ExteriorLocked" 4 "VehLckSts_4_SuperLocked" 5 "VehLckSts_5_Reserved" 6 "VehLckSts_6_Reserved" 7 "VehLckSts_7_Unknow";
VAL_ 714 IAGSModestatus2 0 "AGSModestatus2_0_normal_mode" 1 "AGSModestatus2_1_error_mode" 2 "AGSModestatus2_2_sleep_mode" 3 "AGSModestatus2_3_Reserved";
VAL_ 714 IAGSModestatus1 0 "AGSModestatus1_0_normal_mode" 1 "AGSModestatus1_1_error_mode" 2 "AGSModestatus1_2_sleep_mode" 3 "AGSModestatus1_3_Reserved";
VAL_ 714 IAGS1FltRsn 0 "AGS1FltRsn_0_normal" 1 "AGS1FltRsn_1_AGSMotorTemperatureSensorFault1" 2 "AGS1FltRsn_2_AGSMotorVoltageSensorFault1" 4 "AGS1FltRsn_4_AGSMotorCurrentSensorFault1" 8 "AGS1FltRsn_8_AGSMotorOverheat1" 16 "AGS1FltRsn_16_AGSMotorShortToGround1" 32 "AGS1FltRsn_32_AGSMotorShortToBattery1" 64 "AGS1FltRsn_64_AGSMotorElectronicFault1" 128 "AGS1FltRsn_128_AGSMechanicalBreakError1" 256 "AGS1FltRsn_256_AGSMechanicalblockError1" 512 "AGS1FltRsn_512_AGSControlTimeoutFault1" 1024 "AGS1FltRsn_1024_AGSMotorOverSpeed1" 2048 "AGS1FltRsn_2048_AGSMotorOverCurrent1";
VAL_ 714 IAGS2FltRsn 0 "AGS2FltRsn_0_normal" 1 "AGS2FltRsn_1_AGSMotorTemperatureSensorFault2" 2 "AGS2FltRsn_2_AGSMotorVoltageSensorFault2" 4 "AGS2FltRsn_4_AGSMotorCurrentSensorFault2" 8 "AGS2FltRsn_8_AGSMotorOverheat2" 16 "AGS2FltRsn_16_AGSMotorShortToGround2" 32 "AGS2FltRsn_32_AGSMotorShortToBattery2" 64 "AGS2FltRsn_64_AGSMotorElectronicFault2" 128 "AGS2FltRsn_128_AGSMechanicalBreakError2" 256 "AGS2FltRsn_256_AGSMechanicalblockError2" 512 "AGS2FltRsn_512_AGSControlTimeoutFault2" 1024 "AGS2FltRsn_1024_AGSMotorOverSpeed2" 2048 "AGS2FltRsn_2048_AGSMotorOverCurrent2";
VAL_ 714 IEPTElecWtrPumpActuSpd 255 "EPTElecWtrPumpActuSpd_255_invalid";
VAL_ 714 IESSElecWtrPumpActuSpd 255 "ESSElecWtrPumpActuSpd_255_invalid";
VAL_ 714 IAGSTorqueResponse2 0 "AGSTorqueResponse2_0_normal_torque_level" 1 "AGSTorqueResponse2_1_Boost_mode_torque_level_1" 2 "AGSTorqueResponse2_2_Boost_mode_torque_level_2" 3 "AGSTorqueResponse2_3_reserved";
VAL_ 714 IAGSTorqueResponse1 0 "AGSTorqueResponse1_0_normal_torque_level" 1 "AGSTorqueResponse1_1_Boost_mode_torque_level_1" 2 "AGSTorqueResponse1_2_Boost_mode_torque_level_2" 3 "AGSTorqueResponse1_3_reserved";
VAL_ 714 IAGSSelflearnStatus2 0 "AGSSelflearnStatus2_0_successful" 1 "AGSSelflearnStatus2_1_self_learning" 2 "AGSSelflearnStatus2_2_failed" 3 "AGSSelflearnStatus2_3_reserved";
VAL_ 714 IAGSSelflearnStatus1 0 "AGSSelflearnStatus1_0_successful" 1 "AGSSelflearnStatus1_1_self_learning" 2 "AGSSelflearnStatus1_2_failed" 3 "AGSSelflearnStatus1_3_reserved";
VAL_ 714 IEDUClntTemV 0 "EDUClntTemV_0_Valid" 1 "EDUClntTemV_1_Invalid";
VAL_ 714 IAGSMoveStatus2 0 "AGSMoveStatus2_0_motor_is_idle" 1 "AGSMoveStatus2_1_motor_is_moving";
VAL_ 714 IAGSMoveStatus1 0 "AGSMoveStatus1_0_motor_is_idle" 1 "AGSMoveStatus1_1_motor_is_moving";
VAL_ 1228 IRHRDA_NM_BSMtoRMS_BKPCANFD 0 "RHRDA_NM_BSMtoRMS_BKPCANFD_0_False" 1 "RHRDA_NM_BSMtoRMS_BKPCANFD_1_True";
VAL_ 1228 IRHRDA_NM_PBSMtoRMS_BKPCANFD 0 "RHRDA_NM_PBSMtoRMS_BKPCANFD_0_False" 1 "RHRDA_NM_PBSMtoRMS_BKPCANFD_1_True";
VAL_ 1228 IRHRDA_NM_RMStoNOS_BKPCANFD 0 "RHRDA_NM_RMStoNOS_BKPCANFD_0_False" 1 "RHRDA_NM_RMStoNOS_BKPCANFD_1_True";
VAL_ 1228 IRHRDA_NM_RSStoNOS_BKPCANFD 0 "RHRDA_NM_RSStoNOS_BKPCANFD_0_False" 1 "RHRDA_NM_RSStoNOS_BKPCANFD_1_True";
VAL_ 1228 IRHRDA_NM_RSStoRMS_BKPCANFD 0 "RHRDA_NM_RSStoRMS_BKPCANFD_0_False" 1 "RHRDA_NM_RSStoRMS_BKPCANFD_1_True";
VAL_ 1228 IRHRDA_NM_NOStoRMS_BKPCANFD 0 "RHRDA_NM_NOStoRMS_BKPCANFD_0_False" 1 "RHRDA_NM_NOStoRMS_BKPCANFD_1_True";
VAL_ 1228 IRHRDA_NM_NOSSta_BKPCANFD 0 "RHRDA_NM_NOSSta_BKPCANFD_0_False" 1 "RHRDA_NM_NOSSta_BKPCANFD_1_True";
VAL_ 1228 IRHRDA_NM_RMSSta_BKPCANFD 0 "RHRDA_NM_RMSSta_BKPCANFD_0_False" 1 "RHRDA_NM_RMSSta_BKPCANFD_1_True";
VAL_ 1228 IRHRDA_NWI_BKPCANFD 0 "RHRDA_NWI_BKPCANFD_0_NoWakeNetworkSource";
VAL_ 1228 IRHRDA_NOI_BKPCANFD 0 "RHRDA_NOI_BKPCANFD_0_NoRequest" 65535 "RHRDA_NOI_BKPCANFD_65535_AllNetworkOperationActive";
VAL_ 1228 IRHRDA_NKI_BKPCANFD 0 "RHRDA_NKI_BKPCANFD_0_NoRequest";
VAL_ 936 IESSPTCHVILStsV_RHZCU 0 "ESSPTCHVILStsV_RHZCU_0_Valid" 1 "ESSPTCHVILStsV_RHZCU_1_Invalid";
VAL_ 936 IESSPTCHVILSts_RHZCU 0 "ESSPTCHVILSts_RHZCU_0_Initial" 1 "ESSPTCHVILSts_RHZCU_1_Normal" 2 "ESSPTCHVILSts_RHZCU_2_Fault";
VAL_ 936 IFrSsdLrngFailRrsn 0 "FrSsdLrngFailRrsn_0_No_Fail" 1 "FrSsdLrngFailRrsn_1_Motor_drive_fault" 2 "FrSsdLrngFailRrsn_2_Hall_fault" 3 "FrSsdLrngFailRrsn_3_Hall_number_anomaly" 4 "FrSsdLrngFailRrsn_4_Abnormal_voltage_fault" 5 "FrSsdLrngFailRrsn_5_Other_fault";
VAL_ 936 IAVCamrHeatFltSts 0 "AVCamrHeatFltSts_0_False" 1 "AVCamrHeatFltSts_1_True";
VAL_ 701 IITMSEDUClntInltTemV 0 "ITMSEDUClntInltTemV_0_Valid" 1 "ITMSEDUClntInltTemV_1_Invalid";
VAL_ 701 IEACPwrLmtSts 0 "EACPwrLmtSts_0_False" 1 "EACPwrLmtSts_1_True";
VAL_ 701 IITMSEnbWPTC 0 "ITMSEnbWPTC_0_OFF" 1 "ITMSEnbWPTC_1_ON";
VAL_ 701 IITMSEPTCoolngFanSts 0 "ITMSEPTCoolngFanSts_0_NormalOff" 1 "ITMSEPTCoolngFanSts_1_NormalOn" 2 "ITMSEPTCoolngFanSts_2_Fault";
VAL_ 701 IITMSMotHeatEnb 0 "ITMSMotHeatEnb_0_Off" 1 "ITMSMotHeatEnb_1_On";
VAL_ 701 IITMSBMSClntPumpSts 0 "ITMSBMSClntPumpSts_0_OFF" 1 "ITMSBMSClntPumpSts_1_ON" 2 "ITMSBMSClntPumpSts_2_Failed";
VAL_ 701 IPTCPwrLmtSts 0 "PTCPwrLmtSts_0_False" 1 "PTCPwrLmtSts_1_True";
VAL_ 701 IITMSEPTEDUClntPumpSts 0 "ITMSEPTEDUClntPumpSts_0_NormalOff" 1 "ITMSEPTEDUClntPumpSts_1_NormalOn" 2 "ITMSEPTEDUClntPumpSts_2_Failed";
VAL_ 962 IRmtBattWarmSts 0 "RmtBattWarmSts_0_Off_Mode" 1 "RmtBattWarmSts_1_BattCooling" 2 "RmtBattWarmSts_2_BattWarming";
VAL_ 962 IKeepPwrRsnThrmlSys 0 "KeepPwrRsnThrmlSys_0_Unknow" 1 "KeepPwrRsnThrmlSys_1_OFF_Request" 2 "KeepPwrRsnThrmlSys_2_HV_System_Requirement" 3 "KeepPwrRsnThrmlSys_3_Thrml_AfterRun" 4 "KeepPwrRsnThrmlSys_4_GoingDown";
VAL_ 962 IRmtBattWarmAbotRsn 0 "RmtBattWarmAbotRsn_0_Default_or_NormalWork" 1 "RmtBattWarmAbotRsn_1_Completed" 2 "RmtBattWarmAbotRsn_2_Ended_Request" 3 "RmtBattWarmAbotRsn_3_Usgmd_is_not_sleep_standby" 4 "RmtBattWarmAbotRsn_4_RVSSts_LVSSts_is_Inactive" 5 "RmtBattWarmAbotRsn_5_Electric_Powertrain_not_Allowed" 6 "RmtBattWarmAbotRsn_6_Vehicle_Loadshed_Level_Risk" 7 "RmtBattWarmAbotRsn_7_System_Fault" 8 "RmtBattWarmAbotRsn_8_Other_Reason";
VAL_ 943 IFRDoorOpenSts 0 "FRDoorOpenSts_0_Closed" 1 "FRDoorOpenSts_1_CantDetectDoorAjarStatus" 2 "FRDoorOpenSts_2_Ajar" 3 "FRDoorOpenSts_3_Open";
VAL_ 943 IRRWinShrtDwnSucd 0 "RRWinShrtDwnSucd_0_failed" 1 "RRWinShrtDwnSucd_1_succeed";
VAL_ 943 IROtsdMirFoldSts 0 "ROtsdMirFoldSts_0_Initial" 1 "ROtsdMirFoldSts_1_Folded" 2 "ROtsdMirFoldSts_2_Unfolded" 3 "ROtsdMirFoldSts_3_Folding" 4 "ROtsdMirFoldSts_4_Unfolding" 5 "ROtsdMirFoldSts_5_Failure";
VAL_ 943 IRRWinMotSts 0 "RRWinMotSts_0_still" 1 "RRWinMotSts_1_up" 2 "RRWinMotSts_2_down" 3 "RRWinMotSts_3_auto_up" 4 "RRWinMotSts_4_auto_down" 5 "RRWinMotSts_5_aeration" 6 "RRWinMotSts_6_frameless_short_drive_up" 7 "RRWinMotSts_7_frameless_short_drive_down" 8 "RRWinMotSts_8_Anti_pinch_auto_reverse" 9 "RRWinMotSts_9_Stall" 10 "RRWinMotSts_10_Anti_pinch_Override" 11 "RRWinMotSts_11_AutoriseAtDoorOpen";
VAL_ 943 IFRWinShrtDwnSucd 0 "FRWinShrtDwnSucd_0_failed" 1 "FRWinShrtDwnSucd_1_succeed";
VAL_ 943 IRRWinLclSwtFlt 0 "RRWinLclSwtFlt_0_no_error" 1 "RRWinLclSwtFlt_1_error";
VAL_ 943 IRRWinLclSwtSts 0 "RRWinLclSwtSts_0_no_request" 1 "RRWinLclSwtSts_1_up_request" 2 "RRWinLclSwtSts_2_down_request" 3 "RRWinLclSwtSts_3_auto_up_request" 4 "RRWinLclSwtSts_4_auto_down_request";
VAL_ 943 IRRWinIninSts 0 "RRWinIninSts_0_initialized" 1 "RRWinIninSts_1_not_initialized";
VAL_ 943 IFRWinIninSts 0 "FRWinIninSts_0_initialized" 1 "FRWinIninSts_1_not_initialized";
VAL_ 649 IRRDoorOpenSts 0 "RRDoorOpenSts_0_Closed" 1 "RRDoorOpenSts_1_CantDetectDoorAjarStatus" 2 "RRDoorOpenSts_2_Ajar" 3 "RRDoorOpenSts_3_Open";
VAL_ 649 IRHZCUeSw41DiagSts 0 "RHZCUeSw41DiagSts_0_NoFault" 1 "RHZCUeSw41DiagSts_1_OCP" 2 "RHZCUeSw41DiagSts_2_OVP" 3 "RHZCUeSw41DiagSts_3_UVP" 4 "RHZCUeSw41DiagSts_4_OT" 5 "RHZCUeSw41DiagSts_5_SPI_Fault" 6 "RHZCUeSw41DiagSts_6_ChipFault" 7 "RHZCUeSw41DiagSts_7_OpenCircuit" 8 "RHZCUeSw41DiagSts_8_ShortToGND" 9 "RHZCUeSw41DiagSts_9_ShortToBattery" 10 "RHZCUeSw41DiagSts_10_OtherFault" 11 "RHZCUeSw41DiagSts_11_Drive_Mismatch";
VAL_ 649 IRHZCUeSw41Sts 0 "RHZCUeSw41Sts_0_Unknown" 1 "RHZCUeSw41Sts_1_Off" 2 "RHZCUeSw41Sts_2_On" 3 "RHZCUeSw41Sts_3_LatchOn" 4 "RHZCUeSw41Sts_4_Failure" 5 "RHZCUeSw41Sts_5_GoingDown";
VAL_ 940 IRHZCUeSw14Sts 0 "RHZCUeSw14Sts_0_Unknown" 1 "RHZCUeSw14Sts_1_Off" 2 "RHZCUeSw14Sts_2_On" 3 "RHZCUeSw14Sts_3_LatchOn" 4 "RHZCUeSw14Sts_4_FailureOff" 5 "RHZCUeSw14Sts_5_GoingDown";
VAL_ 940 IRHZCUeSw14DiagSts 0 "RHZCUeSw14DiagSts_0_NoFault" 1 "RHZCUeSw14DiagSts_1_OCP" 2 "RHZCUeSw14DiagSts_2_OVP" 3 "RHZCUeSw14DiagSts_3_UVP" 4 "RHZCUeSw14DiagSts_4_OT" 5 "RHZCUeSw14DiagSts_5_SPI_Fault" 6 "RHZCUeSw14DiagSts_6_ChipFault" 7 "RHZCUeSw14DiagSts_7_OpenCircuit" 8 "RHZCUeSw14DiagSts_8_ShortToGND" 9 "RHZCUeSw14DiagSts_9_ShortToBattery" 10 "RHZCUeSw14DiagSts_10_OtherFault" 11 "RHZCUeSw14DiagSts_11_Drive_Mismatch";
VAL_ 940 IRHZCUeSw31Sts 0 "RHZCUeSw31Sts_0_Unknown" 1 "RHZCUeSw31Sts_1_Off" 2 "RHZCUeSw31Sts_2_On" 3 "RHZCUeSw31Sts_3_LatchOn" 4 "RHZCUeSw31Sts_4_Failure" 5 "RHZCUeSw31Sts_5_GoingDown";
VAL_ 940 IRHZCUeSw31DiagSts 0 "RHZCUeSw31DiagSts_0_NoFault" 1 "RHZCUeSw31DiagSts_1_OCP" 2 "RHZCUeSw31DiagSts_2_OVP" 3 "RHZCUeSw31DiagSts_3_UVP" 4 "RHZCUeSw31DiagSts_4_OT" 5 "RHZCUeSw31DiagSts_5_SPI_Fault" 6 "RHZCUeSw31DiagSts_6_ChipFault" 7 "RHZCUeSw31DiagSts_7_OpenCircuit" 8 "RHZCUeSw31DiagSts_8_ShortToGND" 9 "RHZCUeSw31DiagSts_9_ShortToBattery" 10 "RHZCUeSw31DiagSts_10_OtherFault" 11 "RHZCUeSw31DiagSts_11_Drive_Mismatch";
VAL_ 940 IRHZCUIgnSts 0 "RHZCUIgnSts_0_Unknown" 1 "RHZCUIgnSts_1_Off" 2 "RHZCUIgnSts_2_On" 3 "RHZCUIgnSts_3_LatchOn" 4 "RHZCUIgnSts_4_FailureOff" 5 "RHZCUIgnSts_5_Reserve";
VAL_ 940 IRHZCUIgnDiagSts 0 "RHZCUIgnDiagSts_0_NoFault" 1 "RHZCUIgnDiagSts_1_OCP" 2 "RHZCUIgnDiagSts_2_OVP" 3 "RHZCUIgnDiagSts_3_UVP" 4 "RHZCUIgnDiagSts_4_OT" 5 "RHZCUIgnDiagSts_5_SPI_Fault" 6 "RHZCUIgnDiagSts_6_ChipFault" 7 "RHZCUIgnDiagSts_7_OpenCircuit" 8 "RHZCUIgnDiagSts_8_ShortToGND" 9 "RHZCUIgnDiagSts_9_ShortToBattery" 10 "RHZCUIgnDiagSts_10_OtherFault" 11 "RHZCUignDiagSts_11_Drive_Mismatch";
VAL_ 940 IRHZCUeFs3Sts 0 "RHZCUeFs3Sts_0_Unknown" 1 "RHZCUeFs3Sts_1_Off" 2 "RHZCUeFs3Sts_2_On" 3 "RHZCUeFs3Sts_3_LatchOn" 4 "RHZCUeFs3Sts_4_FailureOff" 5 "RHZCUeFs3Sts_5_GoingDown";
VAL_ 940 IRHZCUeFs3DiagSts 0 "RHZCUeFs3DiagSts_0_NoFault" 1 "RHZCUeFs3DiagSts_1_OCP" 2 "RHZCUeFs3DiagSts_2_OVP" 3 "RHZCUeFs3DiagSts_3_UVP" 4 "RHZCUeFs3DiagSts_4_OT" 5 "RHZCUeFs3DiagSts_5_SPI_Fault" 6 "RHZCUeFs3DiagSts_6_ChipFault" 7 "RHZCUeFs3DiagSts_7_OpenCircuit" 8 "RHZCUeFs3DiagSts_8_ShortToGND" 9 "RHZCUeFs3DiagSts_9_ShortToBattery" 10 "RHZCUeFs3DiagSts_10_OtherFault" 11 "RHZCUeFs3DiagSts_11_Drive_Mismatch";
VAL_ 940 IRHZCUeFs2Sts 0 "RHZCUeFs2Sts_0_Unknown" 1 "RHZCUeFs2Sts_1_Off" 2 "RHZCUeFs2Sts_2_On" 3 "RHZCUeFs2Sts_3_LatchOn" 4 "RHZCUeFs2Sts_4_FailureOff" 5 "RHZCUeFs2Sts_5_GoingDown";
VAL_ 940 IRHZCUeFs2DiagSts 0 "RHZCUeFs2DiagSts_0_NoFault" 1 "RHZCUeFs2DiagSts_1_OCP" 2 "RHZCUeFs2DiagSts_2_OVP" 3 "RHZCUeFs2DiagSts_3_UVP" 4 "RHZCUeFs2DiagSts_4_OT" 5 "RHZCUeFs2DiagSts_5_SPI_Fault" 6 "RHZCUeFs2DiagSts_6_ChipFault" 7 "RHZCUeFs2DiagSts_7_OpenCircuit" 8 "RHZCUeFs2DiagSts_8_ShortToGND" 9 "RHZCUeFs2DiagSts_9_ShortToBattery" 10 "RHZCUeFs2DiagSts_10_OtherFault" 11 "RHZCUeFs2DiagSts_11_Drive_Mismatch";
VAL_ 940 IRHZCUeFs1Sts 0 "RHZCUeFs1Sts_0_Unknown" 1 "RHZCUeFs1Sts_1_Off" 2 "RHZCUeFs1Sts_2_On" 3 "RHZCUeFs1Sts_3_LatchOn" 4 "RHZCUeFs1Sts_4_FailureOff" 5 "RHZCUeFs1Sts_5_GoingDown";
VAL_ 940 IRHZCUeFs1DiagSts 0 "RHZCUeFs1DiagSts_0_NoFault" 1 "RHZCUeFs1DiagSts_1_OCP" 2 "RHZCUeFs1DiagSts_2_OVP" 3 "RHZCUeFs1DiagSts_3_UVP" 4 "RHZCUeFs1DiagSts_4_OT" 5 "RHZCUeFs1DiagSts_5_SPI_Fault" 6 "RHZCUeFs1DiagSts_6_ChipFault" 7 "RHZCUeFs1DiagSts_7_OpenCircuit" 8 "RHZCUeFs1DiagSts_8_ShortToGND" 9 "RHZCUeFs1DiagSts_9_ShortToBattery" 10 "RHZCUeFs1DiagSts_10_OtherFault" 11 "RHZCUeFs1DiagSts_11_Drive_Mismatch";
VAL_ 940 IRHZCUeSw10Sts 0 "RHZCUeSw10Sts_0_Unknown" 1 "RHZCUeSw10Sts_1_Off" 2 "RHZCUeSw10Sts_2_On" 3 "RHZCUeSw10Sts_3_LatchOn" 4 "RHZCUeSw10Sts_4_FailureOff" 5 "RHZCUeSw10Sts_5_GoingDown";
VAL_ 940 IRHZCUeSw10DiagSts 0 "RHZCUeSw10DiagSts_0_NoFault" 1 "RHZCUeSw10DiagSts_1_OCP" 2 "RHZCUeSw10DiagSts_2_OVP" 3 "RHZCUeSw10DiagSts_3_UVP" 4 "RHZCUeSw10DiagSts_4_OT" 5 "RHZCUeSw10DiagSts_5_SPI_Fault" 6 "RHZCUeSw10DiagSts_6_ChipFault" 7 "RHZCUeSw10DiagSts_7_OpenCircuit" 8 "RHZCUeSw10DiagSts_8_ShortToGND" 9 "RHZCUeSw10DiagSts_9_ShortToBattery" 10 "RHZCUeSw10DiagSts_10_OtherFault" 11 "RHZCUeSw10DiagSts_11_Drive_Mismatch";
VAL_ 940 IRHZCUeSw34Sts 0 "RHZCUeSw34Sts_0_Unknown" 1 "RHZCUeSw34Sts_1_Off" 2 "RHZCUeSw34Sts_2_On" 3 "RHZCUeSw34Sts_3_LatchOn" 4 "RHZCUeSw34Sts_4_Failure" 5 "RHZCUeSw34Sts_5_GoingDown";
VAL_ 940 IRHZCUeSw34DiagSts 0 "RHZCUeSw34DiagSts_0_NoFault" 1 "RHZCUeSw34DiagSts_1_OCP" 2 "RHZCUeSw34DiagSts_2_OVP" 3 "RHZCUeSw34DiagSts_3_UVP" 4 "RHZCUeSw34DiagSts_4_OT" 5 "RHZCUeSw34DiagSts_5_SPI_Fault" 6 "RHZCUeSw34DiagSts_6_ChipFault" 7 "RHZCUeSw34DiagSts_7_OpenCircuit" 8 "RHZCUeSw34DiagSts_8_ShortToGND" 9 "RHZCUeSw34DiagSts_9_ShortToBattery" 10 "RHZCUeSw34DiagSts_10_OtherFault" 11 "RHZCUeSw34DiagSts_11_Drive_Mismatch";
VAL_ 564 IRLDircnLghtSts 0 "RLDircnLghtSts_0_Off" 1 "RLDircnLghtSts_1_On";
VAL_ 564 IRRDircnLghtSts 0 "RRDircnLghtSts_0_Off" 1 "RRDircnLghtSts_1_On";
VAL_ 564 IRRDircnLghtFltsts 0 "RRDircnLghtFltsts_0_False" 1 "RRDircnLghtFltsts_1_True";
VAL_ 564 IRLDircnLghtFltsts 0 "RLDircnLghtFltsts_0_False" 1 "RLDircnLghtFltsts_1_True";
VAL_ 564 IRRDircnLghtFltsts_HW 0 "RRDircnLghtFltsts_HW_0_False" 1 "RRDircnLghtFltsts_HW_1_True";
VAL_ 564 IRLDircnLghtFltsts_HW 0 "RLDircnLghtFltsts_HW_0_False" 1 "RLDircnLghtFltsts_HW_1_True";
VAL_ 564 IRearFogLghtFltsts 0 "RearFogLghtFltsts_0_False" 1 "RearFogLghtFltsts_1_True";
VAL_ 564 IRearFogLghtSts 0 "RearFogLghtSts_0_Off" 1 "RearFogLghtSts_1_On";
VAL_ 564 IRevsLghtFltSts 0 "RevsLghtFltSts_0_False" 1 "RevsLghtFltSts_1_True";
VAL_ 564 IBrkLghtFltSts_HW 0 "BrkLghtFltSts_HW_0_False" 1 "BrkLghtFltSts_HW_1_True";
VAL_ 564 IBrkLghtSts_HW 0 "BrkLghtSts_HW_0_Off" 1 "BrkLghtSts_HW_1_On";
VAL_ 564 IRLDircnLghtSts_HW 0 "RLDircnLghtSts_HW_0_Off" 1 "RLDircnLghtSts_HW_1_On";
VAL_ 564 IRRDircnLghtSts_HW 0 "RRDircnLghtSts_HW_0_Off" 1 "RRDircnLghtSts_HW_1_On";
VAL_ 564 ILdspcOpenSts 0 "LdspcOpenSts_0_Closed" 1 "LdspcOpenSts_1_Open";
VAL_ 564 IRevsLghtSts 0 "RevsLghtSts_0_off" 1 "RevsLghtSts_1_on";
VAL_ 564 ILdspcOpenStsV 0 "LdspcOpenStsV_0_Valid" 1 "LdspcOpenStsV_1_Invalid";
VAL_ 564 IRLChrgrFlapOpenPos 0 "RLChrgrFlapOpenPos_0_CLOSE" 100 "RLChrgrFlapOpenPos_100_OPEN" 126 "RLChrgrFlapOpenPos_126_InitValue" 127 "RLChrgrFlapOpenPos_127_Error";
VAL_ 517 IRZCUeSw10Sts 0 "RZCUeSw10Sts_0_Unknown" 1 "RZCUeSw10Sts_1_Off" 2 "RZCUeSw10Sts_2_On" 3 "RZCUeSw10Sts_3_LatchOn" 4 "RZCUeSw10Sts_4_FailureOff" 5 "RZCUeSw10Sts_5_GoingDown";
VAL_ 517 IRZCUeSw10DiagSts 0 "RZCUeSw10DiagSts_0_NoFault" 1 "RZCUeSw10DiagSts_1_OCP" 2 "RZCUeSw10DiagSts_2_OVP" 3 "RZCUeSw10DiagSts_3_UVP" 4 "RZCUeSw10DiagSts_4_OT" 5 "RZCUeSw10DiagSts_5_SPI_Fault" 6 "RZCUeSw10DiagSts_6_ChipFault" 7 "RZCUeSw10DiagSts_7_OpenCircuit" 8 "RZCUeSw10DiagSts_8_ShortToGND" 9 "RZCUeSw10DiagSts_9_ShortToBattery" 10 "RZCUeSw10DiagSts_10_OtherFault" 11 "RZCUeSw10DiagSts_11_Drive_Mismatch";
VAL_ 517 IRZCUIgnSts 0 "RZCUIgnSts_0_Unknown" 1 "RZCUIgnSts_1_Off" 2 "RZCUIgnSts_2_On" 3 "RZCUIgnSts_3_LatchOn" 4 "RZCUIgnSts_4_FailureOff" 5 "RZCUIgnSts_5_Reserve";
VAL_ 517 IRZCUIgnDiagSts 0 "RZCUIgnDiagSts_0_NoFault" 1 "RZCUIgnDiagSts_1_OCP" 2 "RZCUIgnDiagSts_2_OVP" 3 "RZCUIgnDiagSts_3_UVP" 4 "RZCUIgnDiagSts_4_OT" 5 "RZCUIgnDiagSts_5_SPI_Fault" 6 "RZCUIgnDiagSts_6_ChipFault" 7 "RZCUIgnDiagSts_7_OpenCircuit" 8 "RZCUIgnDiagSts_8_ShortToGND" 9 "RZCUIgnDiagSts_9_ShortToBattery" 10 "RZCUIgnDiagSts_10_OtherFault" 11 "RZCUIgnDiagSts_11_Drive_Mismatch";
VAL_ 517 IRZCUeFs3Sts 0 "RZCUeFs3Sts_0_Unknown" 1 "RZCUeFs3Sts_1_Off" 2 "RZCUeFs3Sts_2_On" 3 "RZCUeFs3Sts_3_LatchOn" 4 "RZCUeFs3Sts_4_FailureOff" 5 "RZCUeFs3Sts_5_GoingDown";
VAL_ 517 IRZCUeFs3DiagSts 0 "RZCUeFs3DiagSts_0_NoFault" 1 "RZCUeFs3DiagSts_1_OCP" 2 "RZCUeFs3DiagSts_2_OVP" 3 "RZCUeFs3DiagSts_3_UVP" 4 "RZCUeFs3DiagSts_4_OT" 5 "RZCUeFs3DiagSts_5_SPI_Fault" 6 "RZCUeFs3DiagSts_6_ChipFault" 7 "RZCUeFs3DiagSts_7_OpenCircuit" 8 "RZCUeFs3DiagSts_8_ShortToGND" 9 "RZCUeFs3DiagSts_9_ShortToBattery" 10 "RZCUeFs3DiagSts_10_OtherFault" 11 "RZCUeFs3DiagSts_11_Drive_Mismatch";
VAL_ 517 IRZCUeFs2Sts 0 "RZCUeFs2Sts_0_Unknown" 1 "RZCUeFs2Sts_1_Off" 2 "RZCUeFs2Sts_2_On" 3 "RZCUeFs2Sts_3_LatchOn" 4 "RZCUeFs2Sts_4_FailureOff" 5 "RZCUeFs2Sts_5_GoingDown";
VAL_ 517 IRZCUeFs2DiagSts 0 "RZCUeFs2DiagSts_0_NoFault" 1 "RZCUeFs2DiagSts_1_OCP" 2 "RZCUeFs2DiagSts_2_OVP" 3 "RZCUeFs2DiagSts_3_UVP" 4 "RZCUeFs2DiagSts_4_OT" 5 "RZCUeFs2DiagSts_5_SPI_Fault" 6 "RZCUeFs2DiagSts_6_ChipFault" 7 "RZCUeFs2DiagSts_7_OpenCircuit" 8 "RZCUeFs2DiagSts_8_ShortToGND" 9 "RZCUeFs2DiagSts_9_ShortToBattery" 10 "RZCUeFs2DiagSts_10_OtherFault" 11 "RZCUeFs2DiagSts_11_Drive_Mismatch";
VAL_ 517 IRZCUeFs1Sts 0 "RZCUeFs1Sts_0_Unknown" 1 "RZCUeFs1Sts_1_Off" 2 "RZCUeFs1Sts_2_On" 3 "RZCUeFs1Sts_3_LatchOn" 4 "RZCUeFs1Sts_4_FailureOff" 5 "RZCUeFs1Sts_5_GoingDown";
VAL_ 517 IRZCUeFs1DiagSts 0 "RZCUeFs1DiagSts_0_NoFault" 1 "RZCUeFs1DiagSts_1_OCP" 2 "RZCUeFs1DiagSts_2_OVP" 3 "RZCUeFs1DiagSts_3_UVP" 4 "RZCUeFs1DiagSts_4_OT" 5 "RZCUeFs1DiagSts_5_SPI_Fault" 6 "RZCUeFs1DiagSts_6_ChipFault" 7 "RZCUeFs1DiagSts_7_OpenCircuit" 8 "RZCUeFs1DiagSts_8_ShortToGND" 9 "RZCUeFs1DiagSts_9_ShortToBattery" 10 "RZCUeFs1DiagSts_10_OtherFault" 11 "RZCUeFs1DiagSts_11_Drive_Mismatch";
VAL_ 517 IRZCUeSw9Sts 0 "RZCUeSw9Sts_0_Unknown" 1 "RZCUeSw9Sts_1_Off" 2 "RZCUeSw9Sts_2_On" 3 "RZCUeSw9Sts_3_LatchOn" 4 "RZCUeSw9Sts_4_FailureOff" 5 "RZCUeSw9Sts_5_GoingDown";
VAL_ 517 IRZCUeSw9DiagSts 0 "RZCUeSw9DiagSts_0_NoFault" 1 "RZCUeSw9DiagSts_1_OCP" 2 "RZCUeSw9DiagSts_2_OVP" 3 "RZCUeSw9DiagSts_3_UVP" 4 "RZCUeSw9DiagSts_4_OT" 5 "RZCUeSw9DiagSts_5_SPI_Fault" 6 "RZCUeSw9DiagSts_6_ChipFault" 7 "RZCUeSw9DiagSts_7_OpenCircuit" 8 "RZCUeSw9DiagSts_8_ShortToGND" 9 "RZCUeSw9DiagSts_9_ShortToBattery" 10 "RZCUeSw9DiagSts_10_OtherFault" 11 "RZCUeSw9DiagSts_11_Drive_Mismatch";
SIG_GROUP_ 299 ILHZCU_20ms_Group03 1 : IBrkLghtCtrl IFLDircnLghtCtrl IFRDircnLghtCtrl IHzrdLghtSwReq ILHZCU_20ms_Group03_CRC ILHZCU_20ms_Group03_RC ILHZCU_20ms_Group03_Reserved1 ILHZCU_20ms_Group03_Reserved11 ILHZCU_20ms_Group03_Reserved2 ILHZCU_20ms_Group03_Reserved3 ILHZCU_20ms_Group03_Reserved4 ILHZCU_20ms_Group03_Reserved5 ILHZCU_20ms_Group03_Reserved6 IRLDircnLghtCtrl IRRDircnLghtCtrl IRevsLghtCtrl;
SIG_GROUP_ 652 ILHZCU_50ms_Group06 1 : IBntOpenSts IDrvrDetSts IDrvrDoorOpenSts ILHZCU_50ms_Group06_CRC ILHZCU_50ms_Group06_RC ILHZCU_50ms_Group06_Reserved1 ILHZCU_50ms_Group06_Reserved2 ILHZCU_50ms_Group06_Reserved3 ILHZCU_50ms_Group06_Reserved4 ILHZCU_50ms_Group06_Reserved5 ILHZCU_50ms_Group06_Reserved6 IRLDoorOpenSts IVehLckSts;
SIG_GROUP_ 649 IRHZCU_50ms_Group01 1 : IRHZCU_50ms_Group01_CRC IRHZCU_50ms_Group01_RC IRHZCU_50ms_Group01_Reserved1 IRHZCU_50ms_Group01_Reserved2 IRHZCU_50ms_Group01_Reserved3 IRHZCU_50ms_Group01_Reserved4 IRHZCU_50ms_Group01_Reserved5 IRHZCU_50ms_Group01_Reserved6 IRHZCU_50ms_Group01_Reserved7 IRHZCUeSw41DiagSts IRHZCUeSw41Sts IRRDoorOpenSts;
